[part 4 of 12: package /Cluster]
AUTOSAR XML (schema 4-3-0)
package /Cluster  (continued)
  can cluster HCP5_CANFD01: baudrate=500000, protocol-name=CAN, protocol-version=2.0, bus-off-recovery={bor-counter-l-1-to-l-2=1, bor-time-l-1=0.05, bor-time-l-2=0.2}, can-fd-baudrate=2000000  (continued)
    can physical channel CHNL: comm-connectors=CN_HCP5_CANFD01  (continued)
      frame BMC_HV_03_XIX_HCP5_CANFD01: id 0x1A555555, from BMC_HV, frame-length=24, can-addressing-mode=EXTENDED, can-frame-rx-behavior=CAN-FD, can-frame-tx-behavior=CAN-FD
        pdu BMC_HV_03_XIX_HCP5_CANFD01: length=24, transmission-mode-true-timing=cyclic-timing={time-offset=0, time-period=0.5}, unused-bit-pattern=0
          signal BMC_ThermSpreizung_XIX_BMC_HV_03_XIX_HCP5_CANFD01: start 12, 4 bit, little-endian, data-type-policy=OVERRIDE, i-signal-type=PRIMITIVE, init-value=14, base-type=BT_BMC_ThermSpreizung, invalid-value=Invalid_BMC_ThermSpreizung_XIX_BMC_HV_03_XIX_HCP5_CANFD01:15, compu {phys=raw*10 for raw 0..10, 14=Cxe_Init (CM_BMC_ThermSpreizung_Cxe_Init), 15=Cxf_Fehler (CM_BMC_ThermSpreizung_Cxf_Fehler); unit Unit_PerCent}, range phys 0..100 Unit_PerCent, raw 0..15, unit=Unit_PerCent, transfer-property=PENDING  # Beschreibt die thermische Spreizung der HV-Batterie. 0 % homogener Temperaturverlauf. 100% hoechst heterogener Temperaturverlauf
          signal BMC_VorlaufTemperatur_XIX_BMC_HV_03_XIX_HCP5_CANFD01: start 16, 10 bit, little-endian, data-type-policy=OVERRIDE, i-signal-type=PRIMITIVE, init-value=1022, base-type=BT_BMC_VorlaufTemperatur, invalid-value=Invalid_BMC_VorlaufTemperatur_XIX_BMC_HV_03_XIX_HCP5_CANFD01:1023, compu {phys=raw*0.125-40 for raw 0..1020, 1021=Cx3fd_Nicht_verbaut (CM_BMC_VorlaufTemperatur_Cx3fd_Nicht_verbaut), 1022=Cx3fe_Init (CM_BMC_VorlaufTemperatur_Cx3fe_Init), 1023=Cx3ff_Fehler (CM_BMC_VorlaufTemperatur_Cx3ff_Fehler); unit Unit_DegreCelsi}, range phys -40..87.5 Unit_DegreCelsi, raw 0..1023, unit=Unit_DegreCelsi, transfer-property=PENDING  # Aktuelle Vorlauftemperatur der Batterie
          signal BMC_RuecklaufTemperatur_XIX_BMC_HV_03_XIX_HCP5_CANFD01: start 26, 10 bit, little-endian, data-type-policy=OVERRIDE, i-signal-type=PRIMITIVE, init-value=1022, base-type=BT_BMC_RuecklaufTemperatur, invalid-value=Invalid_BMC_RuecklaufTemperatur_XIX_BMC_HV_03_XIX_HCP5_CANFD01:1023, compu {phys=raw*0.125-40 for raw 0..1020, 1021=Cx3fd_Nicht_verbaut (CM_BMC_RuecklaufTemperatur_Cx3fd_Nicht_verbaut), 1022=Cx3fe_Init (CM_BMC_RuecklaufTemperatur_Cx3fe_Init), 1023=Cx3ff_Fehler (CM_BMC_RuecklaufTemperatur_Cx3ff_Fehler); unit Unit_DegreCelsi}, range phys -40..87.5 Unit_DegreCelsi, raw 0..1023, unit=Unit_DegreCelsi, transfer-property=PENDING  # Aktuelle Ruecklauftemperatur der Batterie
          signal BMC_Temperatur_XIX_BMC_HV_03_XIX_HCP5_CANFD01: start 36, 10 bit, little-endian, data-type-policy=OVERRIDE, i-signal-type=PRIMITIVE, init-value=1022, base-type=BT_BMC_Temperatur, invalid-value=Invalid_BMC_Temperatur_XIX_BMC_HV_03_XIX_HCP5_CANFD01:1023, compu {phys=raw*0.125-40 for raw 0..1021, 1022=Cx3fe_Init (CM_BMC_Temperatur_Cx3fe_Init), 1023=Cx3ff_Fehler (CM_BMC_Temperatur_Cx3ff_Fehler); unit Unit_DegreCelsi}, range phys -40..87.625 Unit_DegreCelsi, raw 0..1023, unit=Unit_DegreCelsi, transfer-property=PENDING  # battery temperature / Momentanwert: Temperatur der Traktionsbatterie
          signal BMC_Abschaltankuendigung_XIX_BMC_HV_03_XIX_HCP5_CANFD01: start 46, 10 bit, little-endian, data-type-policy=OVERRIDE, i-signal-type=PRIMITIVE, init-value=1022, base-type=BT_BMC_Abschaltankuendigung, invalid-value=Invalid_BMC_Abschaltankuendigung_XIX_BMC_HV_03_XIX_HCP5_CANFD01:1023, compu {phys=raw*0.5 for raw 0..1021, 1022=Cx3fe_keine_Abschaltung (CM_BMC_Abschaltankuendigung_Cx3fe_keine_Abschaltung) (keine Abschaltung), 1023=Cx3ff_Fehler (CM_BMC_Abschaltankuendigung_Cx3ff_Fehler); unit Unit_Secon}, range phys 0..510.5 Unit_Secon, raw 0..1023, unit=Unit_Secon, transfer-property=PENDING  # Zeitliche Ankündigung einer Abschaltung der HV Batterie.
          signal BMC_NutzbareKapazitaet_XIX_BMC_HV_03_XIX_HCP5_CANFD01: start 56, 12 bit, little-endian, data-type-policy=OVERRIDE, i-signal-type=PRIMITIVE, init-value=4094, base-type=BT_BMC_NutzbareKapazitaet, invalid-value=Invalid_BMC_NutzbareKapazitaet_XIX_BMC_HV_03_XIX_HCP5_CANFD01:4095, compu {phys=raw*0.125 for raw 0..4093, 4094=Cxffe_Init (CM_BMC_NutzbareKapazitaet_Cxffe_Init), 4095=Cxfff_Fehler (CM_BMC_NutzbareKapazitaet_Cxfff_Fehler); unit Unit_AmperHour}, range phys 0..511.625 Unit_AmperHour, raw 0..4095, unit=Unit_AmperHour, transfer-property=PENDING  # Nutzbare Kapazität der Batterie, entspricht der Ladungsmenge von 100% NutzbarerSOC. Diese Größe ist abhängig vom Bank-Modus (seriell/parallel).
          signal BMC_Dauer_Entladeleistung_XIX_BMC_HV_03_XIX_HCP5_CANFD01: start 68, 12 bit, little-endian, data-type-policy=OVERRIDE, i-signal-type=PRIMITIVE, init-value=4094, base-type=BT_BMC_Dauer_Entladeleistung, invalid-value=Invalid_BMC_Dauer_Entladeleistung_XIX_BMC_HV_03_XIX_HCP5_CANFD01:4095, compu {phys=raw*200 for raw 0..4093, 4094=Cxffe_Init (CM_BMC_Dauer_Entladeleistung_Cxffe_Init), 4095=Cxfff_Fehler (CM_BMC_Dauer_Entladeleistung_Cxfff_Fehler); unit Unit_Watt}, range phys 0..818600 Unit_Watt, raw 0..4095, unit=Unit_Watt, transfer-property=PENDING  # ist die aktuelle Dauer-Leistungsfähigkeit der Batterie. Wenn dieser Wert überschritten wird, kann ein zeitliches Derating der maximalen Leistungsgrenzen stattfindet. Die Dauerleistung ändert sich mit Batterietemperatur und Ladezustand.
          signal BMC_Dauer_Ladeleistung_XIX_BMC_HV_03_XIX_HCP5_CANFD01: start 80, 12 bit, little-endian, data-type-policy=OVERRIDE, i-signal-type=PRIMITIVE, init-value=4094, base-type=BT_BMC_Dauer_Ladeleistung, invalid-value=Invalid_BMC_Dauer_Ladeleistung_XIX_BMC_HV_03_XIX_HCP5_CANFD01:4095, compu {phys=raw*200 for raw 0..4093, 4094=Cxffe_Init (CM_BMC_Dauer_Ladeleistung_Cxffe_Init), 4095=Cxfff_Fehler (CM_BMC_Dauer_Ladeleistung_Cxfff_Fehler); unit Unit_Watt}, range phys 0..818600 Unit_Watt, raw 0..4095, unit=Unit_Watt, transfer-property=PENDING  # ist die aktuelle Dauer-Leistungsfähigkeit der Batterie. Wenn dieser Wert überschritten wird, kann ein zeitliches Derating der maximalen Leistungsgrenzen stattfindet. Die Dauerleistung ändert sich mit Batterietemperatur und Ladezustand.
          signal BMC_VerlustEnergie_XIX_BMC_HV_03_XIX_HCP5_CANFD01: start 92, 13 bit, little-endian, data-type-policy=OVERRIDE, i-signal-type=PRIMITIVE, init-value=8190, base-type=BT_BMC_VerlustEnergie, invalid-value=Invalid_BMC_VerlustEnergie_XIX_BMC_HV_03_XIX_HCP5_CANFD01:8191, compu {phys=raw*4 for raw 0..8189, 8190=Cx1ffe_Init (CM_BMC_VerlustEnergie_Cx1ffe_Init), 8191=Cx1fff_Fehler (CM_BMC_VerlustEnergie_Cx1fff_Fehler); unit Unit_WattHour}, range phys 0..32756 Unit_WattHour, raw 0..8191, unit=Unit_WattHour, transfer-property=PENDING  # Verlustenergie für den Fall, dass I=Irwds eingeprägt wird im HV-ON bis zur vollständigen Entladung (KundenSOC=0%) . Im AC/DC-Laden bis zur vollständigen Ladung (KundenSOC=100%).
          signal BMC_ThermAuslastung_XIX_BMC_HV_03_XIX_HCP5_CANFD01: start 105, 7 bit, little-endian, data-type-policy=OVERRIDE, i-signal-type=PRIMITIVE, init-value=126, base-type=BT_BMC_ThermAuslastung, invalid-value=Invalid_BMC_ThermAuslastung_XIX_BMC_HV_03_XIX_HCP5_CANFD01:127, compu {phys=raw for raw 0..100, 101=Cx65_Notfallkuehlung (CM_BMC_ThermAuslastung_Cx65_Notfallkuehlung), 126=Cx7e_Init (CM_BMC_ThermAuslastung_Cx7e_Init), 127=Cx7f_Fehler (CM_BMC_ThermAuslastung_Cx7f_Fehler); unit Unit_PerCent}, range phys 0..100 Unit_PerCent, raw 0..127, unit=Unit_PerCent, transfer-property=PENDING  # 0- hohe Heizanforderung funktionale Einschränkung 26- mittlere Heizanforderung Temperatur anheben 36- kleine Heizanforderung passives Heizen 46- thermischer Wohlfühlbereich keine Kühl-/Heizleistung 56- kleine Kühlstufe Temperatur halten 66- mittlere Kühlstufe Temperatur absenken 76- große Kühlstufe funktionale Einschränkung 101- Notfallkühlung 126- Init 127- Fehler
          signal BMC_MaxEnergieinhalt_XIX_BMC_HV_03_XIX_HCP5_CANFD01: start 112, 16 bit, little-endian, data-type-policy=OVERRIDE, i-signal-type=PRIMITIVE, init-value=65534, base-type=BT_BMC_MaxEnergieinhalt, invalid-value=Invalid_BMC_MaxEnergieinhalt_XIX_BMC_HV_03_XIX_HCP5_CANFD01:65535, compu {phys=raw*4 for raw 0..65533, 65534=Cxfffe_Init (CM_BMC_MaxEnergieinhalt_Cxfffe_Init), 65535=Cxffff_Fehler (CM_BMC_MaxEnergieinhalt_Cxffff_Fehler); unit Unit_WattHour}, range phys 0..262132 Unit_WattHour, raw 0..65535, unit=Unit_WattHour, transfer-property=PENDING  # Maximaler Energieinhalt der Batterie bei 100% NutzbarerSOC unter Beruecksichtigung der Verluste (I_RWDS)
          signal BMC_Energie_Entladen_XIX_BMC_HV_03_XIX_HCP5_CANFD01: start 128, 16 bit, little-endian, data-type-policy=OVERRIDE, i-signal-type=PRIMITIVE, init-value=65534, base-type=BT_BMC_Energie_Entladen, invalid-value=Invalid_BMC_Energie_Entladen_XIX_BMC_HV_03_XIX_HCP5_CANFD01:65535, compu {phys=raw*0.01 for raw 0..65533, 65534=Cxfffe_Init (CM_BMC_Energie_Entladen_Cxfffe_Init), 65535=Cxffff_Fehler (CM_BMC_Energie_Entladen_Cxffff_Fehler); unit Unit_KiloWattHour}, range phys 0..655.33 Unit_KiloWattHour, raw 0..65535, unit=Unit_KiloWattHour, transfer-property=PENDING  # Energie, welche seit dem letzten Fahrzyklus während eines Ladevorgangs aus der HV-Batterie entnommen wurde
          signal BMC_Energie_Laden_XIX_BMC_HV_03_XIX_HCP5_CANFD01: start 144, 16 bit, little-endian, data-type-policy=OVERRIDE, i-signal-type=PRIMITIVE, init-value=65534, base-type=BT_BMC_Energie_Laden, invalid-value=Invalid_BMC_Energie_Laden_XIX_BMC_HV_03_XIX_HCP5_CANFD01:65535, compu {phys=raw*0.01 for raw 0..65533, 65534=Cxfffe_Init (CM_BMC_Energie_Laden_Cxfffe_Init), 65535=Cxffff_Fehler (CM_BMC_Energie_Laden_Cxffff_Fehler); unit Unit_KiloWattHour}, range phys 0..655.33 Unit_KiloWattHour, raw 0..65535, unit=Unit_KiloWattHour, transfer-property=PENDING  # Energie, welche seit dem letzten Fahrzyklus während eines Ladevorgansg in die HV-Batterie geladen wurde.
          signal BMC_Konditionierung_Anf_XIX_BMC_HV_03_XIX_HCP5_CANFD01: start 160, 1 bit, little-endian, data-type-policy=OVERRIDE, i-signal-type=PRIMITIVE, init-value=0, base-type=BT_BMC_Konditionierung_Anf, compu {0=Cx0_keine_Konditionierungsanforderung (CM_BMC_Konditionierung_Anf_Cx0_keine_Konditionierungsanforderung) (keine Konditionierungsanforderung), 1=Cx1_Konditionierungsanforderung (CM_BMC_Konditionierung_Anf_Cx1_Konditionierungsanforderung)}, range raw 0..1, transfer-property=PENDING  # Anforderung der HV Batterie um deren thermische Konditionierung durchzuführen nachdem das Fahrzeug geweckt wurde.
          signal BMC_Bidi_Min_SoC_XIX_BMC_HV_03_XIX_HCP5_CANFD01: start 161, 7 bit, little-endian, data-type-policy=OVERRIDE, i-signal-type=PRIMITIVE, init-value=126, base-type=BT_BMC_Bidi_Min_SoC, invalid-value=Invalid_BMC_Bidi_Min_SoC_XIX_BMC_HV_03_XIX_HCP5_CANFD01:127, compu {phys=raw for raw 0..100, 126=Cx7e_Init (CM_BMC_Bidi_Min_SoC_Cx7e_Init), 127=Cx7f_Fehler (CM_BMC_Bidi_Min_SoC_Cx7f_Fehler); unit Unit_PerCent}, range phys 0..100 Unit_PerCent, raw 0..127, unit=Unit_PerCent, transfer-property=PENDING  # Wertebereich: 0 - 100% Defaultwert: 20%
          signal BMC_Bidi_GenutzteEnergie_XIX_BMC_HV_03_XIX_HCP5_CANFD01: start 168, 16 bit, little-endian, data-type-policy=OVERRIDE, i-signal-type=PRIMITIVE, init-value=65534, base-type=BT_BMC_Bidi_GenutzteEnergie, invalid-value=Invalid_BMC_Bidi_GenutzteEnergie_XIX_BMC_HV_03_XIX_HCP5_CANFD01:65535, compu {phys=raw for raw 0..65533, 65534=Cxfffe_Init (CM_BMC_Bidi_GenutzteEnergie_Cxfffe_Init), 65535=Cxffff_Fehler (CM_BMC_Bidi_GenutzteEnergie_Cxffff_Fehler); unit Unit_KiloWattHour}, range phys 0..65533 Unit_KiloWattHour, raw 0..65535, unit=Unit_KiloWattHour, transfer-property=PENDING  # Beschreibt den bereits verwendeten Energiedurchsatz (Absolutwert, für Entladen) für die Funktion Bidi.
          signal BMC_Bidi_Veto_Temp_XIX_BMC_HV_03_XIX_HCP5_CANFD01: start 184, 1 bit, little-endian, data-type-policy=OVERRIDE, i-signal-type=PRIMITIVE, init-value=0, base-type=BT_BMC_Bidi_Veto_Temp, compu {0=Cx0_kein_Veto (CM_BMC_Bidi_Veto_Temp_Cx0_kein_Veto), 1=Cx1_Veto (CM_BMC_Bidi_Veto_Temp_Cx1_Veto)}, range raw 0..1, transfer-property=PENDING  # Freigabestatus der Funktion Bidi in Abhängigkeit der Ist-Temperatur
          signal BMC_Bidi_Max_SoC_XIX_BMC_HV_03_XIX_HCP5_CANFD01: start 185, 7 bit, little-endian, data-type-policy=OVERRIDE, i-signal-type=PRIMITIVE, init-value=126, base-type=BT_BMC_Bidi_Max_SoC, invalid-value=Invalid_BMC_Bidi_Max_SoC_XIX_BMC_HV_03_XIX_HCP5_CANFD01:127, compu {phys=raw for raw 0..100, 126=Cx7e_Init (CM_BMC_Bidi_Max_SoC_Cx7e_Init), 127=Cx7f_Fehler (CM_BMC_Bidi_Max_SoC_Cx7f_Fehler); unit Unit_PerCent}, range phys 0..100 Unit_PerCent, raw 0..127, unit=Unit_PerCent, transfer-property=PENDING  # Wertebereich: 0 - 100% Defaultwert: 80%
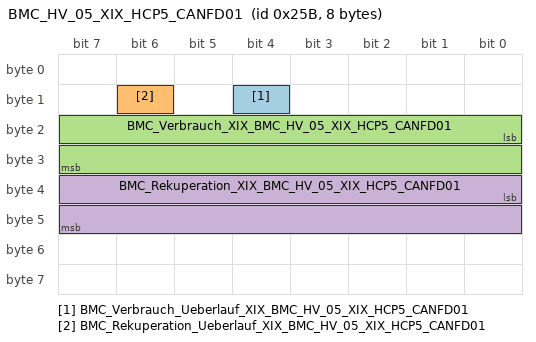
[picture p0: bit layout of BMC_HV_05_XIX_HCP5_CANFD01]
      frame BMC_HV_05_XIX_HCP5_CANFD01: id 0x25B, from BMC_HV, frame-length=8, can-addressing-mode=STANDARD, can-frame-rx-behavior=CAN-FD, can-frame-tx-behavior=CAN-FD
        pdu BMC_HV_05_XIX_HCP5_CANFD01: length=8, transmission-mode-true-timing=cyclic-timing={time-offset=0, time-period=0.05}, unused-bit-pattern=0
          signal BMC_Verbrauch_Ueberlauf_XIX_BMC_HV_05_XIX_HCP5_CANFD01: start 12, 1 bit, little-endian, data-type-policy=OVERRIDE, i-signal-type=PRIMITIVE, init-value=0, base-type=BT_BMC_Verbrauch_Ueberlauf, compu {0=Cx0_nicht_Ueberlauf (CM_BMC_Verbrauch_Ueberlauf_Cx0_nicht_Ueberlauf), 1=Cx1_Ueberlauf (CM_BMC_Verbrauch_Ueberlauf_Cx1_Ueberlauf)}, range raw 0..1, transfer-property=PENDING  # Signalisiert ob der Überlauf einen physikalischer Ursprung hat (0 = kein Überlauf oder Überlauf mit keinem physikalischem Ursprung)
          signal BMC_Rekuperation_Ueberlauf_XIX_BMC_HV_05_XIX_HCP5_CANFD01: start 14, 1 bit, little-endian, data-type-policy=OVERRIDE, i-signal-type=PRIMITIVE, init-value=0, base-type=BT_BMC_Rekuperation_Ueberlauf, compu {0=Cx0_kein_Ueberlauf (CM_BMC_Rekuperation_Ueberlauf_Cx0_kein_Ueberlauf), 1=Cx1_Ueberlauf (CM_BMC_Rekuperation_Ueberlauf_Cx1_Ueberlauf)}, range raw 0..1, transfer-property=PENDING  # Signalisiert ob der Überlauf einen physikalischer Ursprung hat (0 = kein Überlauf oder Überlauf mit keinem physikalischem Ursprung)
          signal BMC_Verbrauch_XIX_BMC_HV_05_XIX_HCP5_CANFD01: start 16, 16 bit, little-endian, data-type-policy=OVERRIDE, i-signal-type=PRIMITIVE, init-value=0, base-type=BT_BMC_Verbrauch, compu {phys=raw*10 for raw 0..65535; unit Unit_WattSecond}, range phys 0..655350 Unit_WattSecond, raw 0..65535, unit=Unit_WattSecond, transfer-property=PENDING  # Zähler: Energieentnahme aus der HV-Batterie
          signal BMC_Rekuperation_XIX_BMC_HV_05_XIX_HCP5_CANFD01: start 32, 16 bit, little-endian, data-type-policy=OVERRIDE, i-signal-type=PRIMITIVE, init-value=0, base-type=BT_BMC_Rekuperation, compu {phys=raw*10 for raw 0..65535; unit Unit_WattSecond}, range phys 0..655350 Unit_WattSecond, raw 0..65535, unit=Unit_WattSecond, transfer-property=PENDING  # Zähler: Anzeigesignal: Energiezufuhr in die HV-Batterie (Reku). Darf nicht durch Laden der Batterie bedatet werden
      frame BMC_HV_06_SOK_XIX_HCP5_CANFD01: id 0x16A95516, from BMC_HV, frame-length=12, can-addressing-mode=EXTENDED, can-frame-rx-behavior=CAN-FD, can-frame-tx-behavior=CAN-FD
        secured i pdu BMC_HV_06_SOK_XIX_HCP5_CANFD01:
          length=12
          authentication-props=SecureCommunicationAuthenticationProps_XIX_32
          freshness-props=SecureCommunicationFreshnessProps
          payload=PT_BMC_HV_06
          secure-communication-props={auth-data-freshness-length=0, auth-data-freshness-start-position=0, auth-info-tx-length=32, authentication-build-attempts=1, authentication-retries=4, data-id=535, freshness-value-id=2, freshness-value-length=64, freshness-value-tx-length=0}
          use-as-cryptographic-i-pdu=false
      frame BMC_HV_07_SOK_XIX_HCP5_CANFD01: id 0x16A95532, from BMC_HV, frame-length=12, can-addressing-mode=EXTENDED, can-frame-rx-behavior=CAN-FD, can-frame-tx-behavior=CAN-FD
        secured i pdu BMC_HV_07_SOK_XIX_HCP5_CANFD01:
          length=12
          authentication-props=SecureCommunicationAuthenticationProps_XIX_32
          freshness-props=SecureCommunicationFreshnessProps
          payload=PT_BMC_HV_07
          secure-communication-props={auth-data-freshness-length=0, auth-data-freshness-start-position=0, auth-info-tx-length=32, authentication-build-attempts=1, authentication-retries=4, data-id=730, freshness-value-id=3, freshness-value-length=64, freshness-value-tx-length=0}
          use-as-cryptographic-i-pdu=false
      frame BMC_HV_08_SOK_XIX_HCP5_CANFD01: id 0x1A555631, from BMC_HV, frame-length=48, can-addressing-mode=EXTENDED, can-frame-rx-behavior=CAN-FD, can-frame-tx-behavior=CAN-FD
        secured i pdu BMC_HV_08_SOK_XIX_HCP5_CANFD01:
          length=48
          authentication-props=SecureCommunicationAuthenticationProps_XIX_32
          freshness-props=SecureCommunicationFreshnessProps
          payload=PT_BMC_HV_08
          secure-communication-props={auth-data-freshness-length=0, auth-data-freshness-start-position=0, auth-info-tx-length=32, authentication-build-attempts=1, authentication-retries=4, data-id=731, freshness-value-id=4, freshness-value-length=64, freshness-value-tx-length=0}
          use-as-cryptographic-i-pdu=false
      frame BMC_HV_09_SOK_XIX_HCP5_CANFD01: id 0x12DD5593, from BMC_HV, frame-length=20, can-addressing-mode=EXTENDED, can-frame-rx-behavior=CAN-FD, can-frame-tx-behavior=CAN-FD
        secured i pdu BMC_HV_09_SOK_XIX_HCP5_CANFD01:
          length=20
          authentication-props=SecureCommunicationAuthenticationProps_XIX_32
          freshness-props=SecureCommunicationFreshnessProps
          payload=PT_BMC_HV_09
          secure-communication-props={auth-data-freshness-length=0, auth-data-freshness-start-position=0, auth-info-tx-length=32, authentication-build-attempts=1, authentication-retries=4, data-id=810, freshness-value-id=5, freshness-value-length=64, freshness-value-tx-length=0}
          use-as-cryptographic-i-pdu=false
      frame BMC_HV_14_SOK_XIX_HCP5_CANFD01: id 0x12DD55C4, from BMC_HV, frame-length=16, can-addressing-mode=STANDARD, can-frame-rx-behavior=CAN-FD, can-frame-tx-behavior=CAN-FD
        secured i pdu BMC_HV_14_SOK_XIX_HCP5_CANFD01:
          length=16
          authentication-props=SecureCommunicationAuthenticationProps_XIX_32
          freshness-props=SecureCommunicationFreshnessProps
          payload=PT_BMC_HV_14
          secure-communication-props={auth-data-freshness-length=0, auth-data-freshness-start-position=0, auth-info-tx-length=32, authentication-build-attempts=1, authentication-retries=4, data-id=846, freshness-value-id=6, freshness-value-length=64, freshness-value-tx-length=0}
          use-as-cryptographic-i-pdu=false
      frame Charisma_20_XIX_HCP5_CANFD01: id 0x1A55556D, to BMC_HV, frame-length=20, can-addressing-mode=EXTENDED, can-frame-rx-behavior=CAN-FD, can-frame-tx-behavior=CAN-FD
        pdu Charisma_20_XIX_HCP5_CANFD01: length=20, minimum-delay=0.05, transmission-mode-true-timing={cyclic-timing={time-offset=0, time-period=1}, event-controlled-timing={number-of-repetitions=0, repetition-period=0}}, unused-bit-pattern=0
          signal CHA_ReqPrgBms_XIX_Charisma_20_XIX_HCP5_CANFD01: start 12, 4 bit, little-endian, data-type-policy=OVERRIDE, i-signal-type=PRIMITIVE, init-value=0, base-type=BT_CHA_ReqPrgBms, compu {0=Cx0_no_program (CM_CHA_ReqPrgBms_Cx0_no_program), 1=Cx1_program_1 (CM_CHA_ReqPrgBms_Cx1_program_1), 2=Cx2_program_2 (CM_CHA_ReqPrgBms_Cx2_program_2), 3=Cx3_program_3 (CM_CHA_ReqPrgBms_Cx3_program_3), 4=Cx4_program_4 (CM_CHA_ReqPrgBms_Cx4_program_4), 5=Cx5_program_5 (CM_CHA_ReqPrgBms_Cx5_program_5), 6=Cx6_program_6 (CM_CHA_ReqPrgBms_Cx6_program_6), 7=Cx7_program_7 (CM_CHA_ReqPrgBms_Cx7_program_7), 8=Cx8_program_8 (CM_CHA_ReqPrgBms_Cx8_program_8), 9=Cx9_program_9 (CM_CHA_ReqPrgBms_Cx9_program_9), 10=Cxa_program_10 (CM_CHA_ReqPrgBms_Cxa_program_10), 11=Cxb_program_11 (CM_CHA_ReqPrgBms_Cxb_program_11), 12=Cxc_program_12 (CM_CHA_ReqPrgBms_Cxc_program_12), 13=Cxd_program_13 (CM_CHA_ReqPrgBms_Cxd_program_13), 14=Cxe_program_14 (CM_CHA_ReqPrgBms_Cxe_program_14), 15=Cxf_program_15 (CM_CHA_ReqPrgBms_Cxf_program_15)}, range raw 0..15, transfer-property=TRIGGERED-ON-CHANGE-WITHOUT-REPETITION, to BMC_HV(timeout 5 s)  # Anforderung des Fahrprogramms seitens Charisma an das Batterie-Management-System
          signal CHA_ReqPrgEps_XIX_Charisma_20_XIX_HCP5_CANFD01: start 20, 4 bit, little-endian, data-type-policy=OVERRIDE, i-signal-type=PRIMITIVE, init-value=0, base-type=BT_CHA_ReqPrgEps, compu {0=Cx0_no_program (CM_CHA_ReqPrgEps_Cx0_no_program), 1=Cx1_program_1 (CM_CHA_ReqPrgEps_Cx1_program_1), 2=Cx2_program_2 (CM_CHA_ReqPrgEps_Cx2_program_2), 3=Cx3_program_3 (CM_CHA_ReqPrgEps_Cx3_program_3), 4=Cx4_program_4 (CM_CHA_ReqPrgEps_Cx4_program_4), 5=Cx5_program_5 (CM_CHA_ReqPrgEps_Cx5_program_5), 6=Cx6_program_6 (CM_CHA_ReqPrgEps_Cx6_program_6), 7=Cx7_program_7 (CM_CHA_ReqPrgEps_Cx7_program_7), 8=Cx8_program_8 (CM_CHA_ReqPrgEps_Cx8_program_8), 9=Cx9_program_9 (CM_CHA_ReqPrgEps_Cx9_program_9), 10=Cxa_program_10 (CM_CHA_ReqPrgEps_Cxa_program_10), 11=Cxb_program_11 (CM_CHA_ReqPrgEps_Cxb_program_11), 12=Cxc_program_12 (CM_CHA_ReqPrgEps_Cxc_program_12), 13=Cxd_program_13 (CM_CHA_ReqPrgEps_Cxd_program_13), 14=Cxe_program_14 (CM_CHA_ReqPrgEps_Cxe_program_14), 15=Cxf_program_15 (CM_CHA_ReqPrgEps_Cxf_program_15)}, range raw 0..15, transfer-property=TRIGGERED-ON-CHANGE-WITHOUT-REPETITION  # Anforderung des Fahrprogramms seitens Charisma an die EPS-Lenkung.
          signal CHA_ReqPrgTqVect_XIX_Charisma_20_XIX_HCP5_CANFD01: start 28, 4 bit, little-endian, data-type-policy=OVERRIDE, i-signal-type=PRIMITIVE, init-value=0, base-type=BT_CHA_ReqPrgTqVect, compu {0=Cx0_no_program (CM_CHA_ReqPrgTqVect_Cx0_no_program), 1=Cx1_program_1 (CM_CHA_ReqPrgTqVect_Cx1_program_1), 2=Cx2_program_2 (CM_CHA_ReqPrgTqVect_Cx2_program_2), 3=Cx3_program_3 (CM_CHA_ReqPrgTqVect_Cx3_program_3), 4=Cx4_program_4 (CM_CHA_ReqPrgTqVect_Cx4_program_4), 5=Cx5_program_5 (CM_CHA_ReqPrgTqVect_Cx5_program_5), 6=Cx6_program_6 (CM_CHA_ReqPrgTqVect_Cx6_program_6), 7=Cx7_program_7 (CM_CHA_ReqPrgTqVect_Cx7_program_7), 8=Cx8_program_8 (CM_CHA_ReqPrgTqVect_Cx8_program_8), 9=Cx9_program_9 (CM_CHA_ReqPrgTqVect_Cx9_program_9), 10=Cxa_program_10 (CM_CHA_ReqPrgTqVect_Cxa_program_10), 11=Cxb_program_11 (CM_CHA_ReqPrgTqVect_Cxb_program_11), 12=Cxc_program_12 (CM_CHA_ReqPrgTqVect_Cxc_program_12), 13=Cxd_program_13 (CM_CHA_ReqPrgTqVect_Cxd_program_13), 14=Cxe_program_14 (CM_CHA_ReqPrgTqVect_Cxe_program_14), 15=Cxf_program_15 (CM_CHA_ReqPrgTqVect_Cxf_program_15)}, range raw 0..15, transfer-property=TRIGGERED-ON-CHANGE-WITHOUT-REPETITION  # Anforderung des Fahrprogramms seitens Charisma an die Torque-Vectoring-Systeme (z.B. QSP, eTV, BTV)
          signal CHA_ReqPrgKl_XIX_Charisma_20_XIX_HCP5_CANFD01: start 32, 4 bit, little-endian, data-type-policy=OVERRIDE, i-signal-type=PRIMITIVE, init-value=0, base-type=BT_CHA_ReqPrgKl, compu {0=Cx0_no_program (CM_CHA_ReqPrgKl_Cx0_no_program), 1=Cx1_program_1 (CM_CHA_ReqPrgKl_Cx1_program_1), 2=Cx2_program_2 (CM_CHA_ReqPrgKl_Cx2_program_2), 3=Cx3_program_3 (CM_CHA_ReqPrgKl_Cx3_program_3), 4=Cx4_program_4 (CM_CHA_ReqPrgKl_Cx4_program_4), 5=Cx5_program_5 (CM_CHA_ReqPrgKl_Cx5_program_5), 6=Cx6_program_6 (CM_CHA_ReqPrgKl_Cx6_program_6), 7=Cx7_program_7 (CM_CHA_ReqPrgKl_Cx7_program_7), 8=Cx8_program_8 (CM_CHA_ReqPrgKl_Cx8_program_8), 9=Cx9_program_9 (CM_CHA_ReqPrgKl_Cx9_program_9), 10=Cxa_program_10 (CM_CHA_ReqPrgKl_Cxa_program_10), 11=Cxb_program_11 (CM_CHA_ReqPrgKl_Cxb_program_11), 12=Cxc_program_12 (CM_CHA_ReqPrgKl_Cxc_program_12), 13=Cxd_program_13 (CM_CHA_ReqPrgKl_Cxd_program_13), 14=Cxe_program_14 (CM_CHA_ReqPrgKl_Cxe_program_14), 15=Cxf_program_15 (CM_CHA_ReqPrgKl_Cxf_program_15)}, range raw 0..15, transfer-property=TRIGGERED-ON-CHANGE-WITHOUT-REPETITION  # Anforderung des Fahrprogramms seitens Charisma an die Klima-Anlage
          signal CHA_ReqPrgDynTqCtrl_XIX_Charisma_20_XIX_HCP5_CANFD01: start 36, 4 bit, little-endian, data-type-policy=OVERRIDE, i-signal-type=PRIMITIVE, init-value=0, base-type=BT_CHA_ReqPrgDynTqCtrl, compu {0=Cx0_no_program (CM_CHA_ReqPrgDynTqCtrl_Cx0_no_program), 1=Cx1_program_1 (CM_CHA_ReqPrgDynTqCtrl_Cx1_program_1), 2=Cx2_program_2 (CM_CHA_ReqPrgDynTqCtrl_Cx2_program_2), 3=Cx3_program_3 (CM_CHA_ReqPrgDynTqCtrl_Cx3_program_3), 4=Cx4_program_4 (CM_CHA_ReqPrgDynTqCtrl_Cx4_program_4), 5=Cx5_program_5 (CM_CHA_ReqPrgDynTqCtrl_Cx5_program_5), 6=Cx6_program_6 (CM_CHA_ReqPrgDynTqCtrl_Cx6_program_6), 7=Cx7_program_7 (CM_CHA_ReqPrgDynTqCtrl_Cx7_program_7), 8=Cx8_program_8 (CM_CHA_ReqPrgDynTqCtrl_Cx8_program_8), 9=Cx9_program_9 (CM_CHA_ReqPrgDynTqCtrl_Cx9_program_9), 10=Cxa_program_10 (CM_CHA_ReqPrgDynTqCtrl_Cxa_program_10), 11=Cxb_program_11 (CM_CHA_ReqPrgDynTqCtrl_Cxb_program_11), 12=Cxc_program_12 (CM_CHA_ReqPrgDynTqCtrl_Cxc_program_12), 13=Cxd_program_13 (CM_CHA_ReqPrgDynTqCtrl_Cxd_program_13), 14=Cxe_program_14 (CM_CHA_ReqPrgDynTqCtrl_Cxe_program_14), 15=Cxf_program_15 (CM_CHA_ReqPrgDynTqCtrl_Cxf_program_15)}, range raw 0..15, transfer-property=TRIGGERED-ON-CHANGE-WITHOUT-REPETITION  # Anforderung des Fahrprogramms seitens Charisma an Allradregelsysteme (z.B. quattro ultra und eQuattro)
          signal CHA_ReqPrgAcc_XIX_Charisma_20_XIX_HCP5_CANFD01: start 40, 4 bit, little-endian, data-type-policy=OVERRIDE, i-signal-type=PRIMITIVE, init-value=0, base-type=BT_CHA_ReqPrgAcc, compu {0=Cx0_no_program (CM_CHA_ReqPrgAcc_Cx0_no_program), 1=Cx1_program_1 (CM_CHA_ReqPrgAcc_Cx1_program_1), 2=Cx2_program_2 (CM_CHA_ReqPrgAcc_Cx2_program_2), 3=Cx3_program_3 (CM_CHA_ReqPrgAcc_Cx3_program_3), 4=Cx4_program_4 (CM_CHA_ReqPrgAcc_Cx4_program_4), 5=Cx5_program_5 (CM_CHA_ReqPrgAcc_Cx5_program_5), 6=Cx6_program_6 (CM_CHA_ReqPrgAcc_Cx6_program_6), 7=Cx7_program_7 (CM_CHA_ReqPrgAcc_Cx7_program_7), 8=Cx8_program_8 (CM_CHA_ReqPrgAcc_Cx8_program_8), 9=Cx9_program_9 (CM_CHA_ReqPrgAcc_Cx9_program_9), 10=Cxa_program_10 (CM_CHA_ReqPrgAcc_Cxa_program_10), 11=Cxb_program_11 (CM_CHA_ReqPrgAcc_Cxb_program_11), 12=Cxc_program_12 (CM_CHA_ReqPrgAcc_Cxc_program_12), 13=Cxd_program_13 (CM_CHA_ReqPrgAcc_Cxd_program_13), 14=Cxe_program_14 (CM_CHA_ReqPrgAcc_Cxe_program_14), 15=Cxf_program_15 (CM_CHA_ReqPrgAcc_Cxf_program_15)}, range raw 0..15, transfer-property=TRIGGERED-ON-CHANGE-WITHOUT-REPETITION  # Anforderung des Fahrprogramms seitens Charisma an die Funktion ACC.
          signal CHA_ReqPrgRwb_XIX_Charisma_20_XIX_HCP5_CANFD01: start 44, 4 bit, little-endian, data-type-policy=OVERRIDE, i-signal-type=PRIMITIVE, init-value=0, base-type=BT_CHA_ReqPrgRwb, compu {0=Cx0_no_program (CM_CHA_ReqPrgRwb_Cx0_no_program), 1=Cx1_program_1 (CM_CHA_ReqPrgRwb_Cx1_program_1), 2=Cx2_program_2 (CM_CHA_ReqPrgRwb_Cx2_program_2), 3=Cx3_program_3 (CM_CHA_ReqPrgRwb_Cx3_program_3), 4=Cx4_program_4 (CM_CHA_ReqPrgRwb_Cx4_program_4), 5=Cx5_program_5 (CM_CHA_ReqPrgRwb_Cx5_program_5), 6=Cx6_program_6 (CM_CHA_ReqPrgRwb_Cx6_program_6), 7=Cx7_program_7 (CM_CHA_ReqPrgRwb_Cx7_program_7), 8=Cx8_program_8 (CM_CHA_ReqPrgRwb_Cx8_program_8), 9=Cx9_program_9 (CM_CHA_ReqPrgRwb_Cx9_program_9), 10=Cxa_program_10 (CM_CHA_ReqPrgRwb_Cxa_program_10), 11=Cxb_program_11 (CM_CHA_ReqPrgRwb_Cxb_program_11), 12=Cxc_program_12 (CM_CHA_ReqPrgRwb_Cxc_program_12), 13=Cxd_program_13 (CM_CHA_ReqPrgRwb_Cxd_program_13), 14=Cxe_program_14 (CM_CHA_ReqPrgRwb_Cxe_program_14), 15=Cxf_program_15 (CM_CHA_ReqPrgRwb_Cxf_program_15)}, range raw 0..15, transfer-property=TRIGGERED-ON-CHANGE-WITHOUT-REPETITION  # Anforderung des Fahrprogramms seitens Charisma an die Funktion Reichweitenberechnung.
          signal CHA_ReqPrgHsp_XIX_Charisma_20_XIX_HCP5_CANFD01: start 48, 4 bit, little-endian, data-type-policy=OVERRIDE, i-signal-type=PRIMITIVE, init-value=0, base-type=BT_CHA_ReqPrgHsp, compu {0=Cx0_no_program (CM_CHA_ReqPrgHsp_Cx0_no_program), 1=Cx1_program_1 (CM_CHA_ReqPrgHsp_Cx1_program_1), 2=Cx2_program_2 (CM_CHA_ReqPrgHsp_Cx2_program_2), 3=Cx3_program_3 (CM_CHA_ReqPrgHsp_Cx3_program_3), 4=Cx4_program_4 (CM_CHA_ReqPrgHsp_Cx4_program_4), 5=Cx5_program_5 (CM_CHA_ReqPrgHsp_Cx5_program_5), 6=Cx6_program_6 (CM_CHA_ReqPrgHsp_Cx6_program_6), 7=Cx7_program_7 (CM_CHA_ReqPrgHsp_Cx7_program_7), 8=Cx8_program_8 (CM_CHA_ReqPrgHsp_Cx8_program_8), 9=Cx9_program_9 (CM_CHA_ReqPrgHsp_Cx9_program_9), 10=Cxa_program_10 (CM_CHA_ReqPrgHsp_Cxa_program_10), 11=Cxb_program_11 (CM_CHA_ReqPrgHsp_Cxb_program_11), 12=Cxc_program_12 (CM_CHA_ReqPrgHsp_Cxc_program_12), 13=Cxd_program_13 (CM_CHA_ReqPrgHsp_Cxd_program_13), 14=Cxe_program_14 (CM_CHA_ReqPrgHsp_Cxe_program_14), 15=Cxf_program_15 (CM_CHA_ReqPrgHsp_Cxf_program_15)}, range raw 0..15, transfer-property=TRIGGERED-ON-CHANGE-WITHOUT-REPETITION  # Anforderung des Fahrprogramms seitens Charisma an die Heckspoiler-Steuerung. Nur in Porsche-Fahrzeugen gütlig.
          signal CHA_ReqPrgWarnBrk_XIX_Charisma_20_XIX_HCP5_CANFD01: start 52, 4 bit, little-endian, data-type-policy=OVERRIDE, i-signal-type=PRIMITIVE, init-value=0, base-type=BT_CHA_ReqPrgWarnBrk, compu {0=Cx0_no_program (CM_CHA_ReqPrgWarnBrk_Cx0_no_program), 1=Cx1_program_1 (CM_CHA_ReqPrgWarnBrk_Cx1_program_1), 2=Cx2_program_2 (CM_CHA_ReqPrgWarnBrk_Cx2_program_2), 3=Cx3_program_3 (CM_CHA_ReqPrgWarnBrk_Cx3_program_3), 4=Cx4_program_4 (CM_CHA_ReqPrgWarnBrk_Cx4_program_4), 5=Cx5_program_5 (CM_CHA_ReqPrgWarnBrk_Cx5_program_5), 6=Cx6_program_6 (CM_CHA_ReqPrgWarnBrk_Cx6_program_6), 7=Cx7_program_7 (CM_CHA_ReqPrgWarnBrk_Cx7_program_7), 8=Cx8_program_8 (CM_CHA_ReqPrgWarnBrk_Cx8_program_8), 9=Cx9_program_9 (CM_CHA_ReqPrgWarnBrk_Cx9_program_9), 10=Cxa_program_10 (CM_CHA_ReqPrgWarnBrk_Cxa_program_10), 11=Cxb_program_11 (CM_CHA_ReqPrgWarnBrk_Cxb_program_11), 12=Cxc_program_12 (CM_CHA_ReqPrgWarnBrk_Cxc_program_12), 13=Cxd_program_13 (CM_CHA_ReqPrgWarnBrk_Cxd_program_13), 14=Cxe_program_14 (CM_CHA_ReqPrgWarnBrk_Cxe_program_14), 15=Cxf_program_15 (CM_CHA_ReqPrgWarnBrk_Cxf_program_15)}, range raw 0..15, transfer-property=TRIGGERED-ON-CHANGE-WITHOUT-REPETITION  # Anforderung des Fahrprogramms seitens Charisma an die Funktion Warn-Brems
          signal CHA_ReqPrgExtrLight_XIX_Charisma_20_XIX_HCP5_CANFD01: start 56, 4 bit, little-endian, data-type-policy=OVERRIDE, i-signal-type=PRIMITIVE, init-value=0, base-type=BT_CHA_ReqPrgExtrLight, compu {0=Cx0_no_program (CM_CHA_ReqPrgExtrLight_Cx0_no_program), 1=Cx1_program_1 (CM_CHA_ReqPrgExtrLight_Cx1_program_1), 2=Cx2_program_2 (CM_CHA_ReqPrgExtrLight_Cx2_program_2), 3=Cx3_program_3 (CM_CHA_ReqPrgExtrLight_Cx3_program_3), 4=Cx4_program_4 (CM_CHA_ReqPrgExtrLight_Cx4_program_4), 5=Cx5_program_5 (CM_CHA_ReqPrgExtrLight_Cx5_program_5), 6=Cx6_program_6 (CM_CHA_ReqPrgExtrLight_Cx6_program_6), 7=Cx7_program_7 (CM_CHA_ReqPrgExtrLight_Cx7_program_7), 8=Cx8_program_8 (CM_CHA_ReqPrgExtrLight_Cx8_program_8), 9=Cx9_program_9 (CM_CHA_ReqPrgExtrLight_Cx9_program_9), 10=Cxa_program_10 (CM_CHA_ReqPrgExtrLight_Cxa_program_10), 11=Cxb_program_11 (CM_CHA_ReqPrgExtrLight_Cxb_program_11), 12=Cxc_program_12 (CM_CHA_ReqPrgExtrLight_Cxc_program_12), 13=Cxd_program_13 (CM_CHA_ReqPrgExtrLight_Cxd_program_13), 14=Cxe_program_14 (CM_CHA_ReqPrgExtrLight_Cxe_program_14), 15=Cxf_program_15 (CM_CHA_ReqPrgExtrLight_Cxf_program_15)}, range raw 0..15, transfer-property=TRIGGERED-ON-CHANGE-WITHOUT-REPETITION  # Anforderung des Fahrprogramms seitens Charisma an die Scheinwerfer-Funktionen.
          signal CHA_ReqPrgEsc_XIX_Charisma_20_XIX_HCP5_CANFD01: start 60, 4 bit, little-endian, data-type-policy=OVERRIDE, i-signal-type=PRIMITIVE, init-value=0, base-type=BT_CHA_ReqPrgEsc, compu {0=Cx0_no_program (CM_CHA_ReqPrgEsc_Cx0_no_program), 1=Cx1_program_1 (CM_CHA_ReqPrgEsc_Cx1_program_1), 2=Cx2_program_2 (CM_CHA_ReqPrgEsc_Cx2_program_2), 3=Cx3_program_3 (CM_CHA_ReqPrgEsc_Cx3_program_3), 4=Cx4_program_4 (CM_CHA_ReqPrgEsc_Cx4_program_4), 5=Cx5_program_5 (CM_CHA_ReqPrgEsc_Cx5_program_5), 6=Cx6_program_6 (CM_CHA_ReqPrgEsc_Cx6_program_6), 7=Cx7_program_7 (CM_CHA_ReqPrgEsc_Cx7_program_7), 8=Cx8_program_8 (CM_CHA_ReqPrgEsc_Cx8_program_8), 9=Cx9_program_9 (CM_CHA_ReqPrgEsc_Cx9_program_9), 10=Cxa_program_10 (CM_CHA_ReqPrgEsc_Cxa_program_10), 11=Cxb_program_11 (CM_CHA_ReqPrgEsc_Cxb_program_11), 12=Cxc_program_12 (CM_CHA_ReqPrgEsc_Cxc_program_12), 13=Cxd_program_13 (CM_CHA_ReqPrgEsc_Cxd_program_13), 14=Cxe_program_14 (CM_CHA_ReqPrgEsc_Cxe_program_14), 15=Cxf_program_15 (CM_CHA_ReqPrgEsc_Cxf_program_15)}, range raw 0..15, transfer-property=TRIGGERED-ON-CHANGE-WITHOUT-REPETITION  # Anforderung des Fahrprogramms seitens Charisma an das ESC
          signal CHA_ReqPrgHdc_XIX_Charisma_20_XIX_HCP5_CANFD01: start 64, 4 bit, little-endian, data-type-policy=OVERRIDE, i-signal-type=PRIMITIVE, init-value=0, base-type=BT_CHA_ReqPrgHdc, compu {0=Cx0_no_program (CM_CHA_ReqPrgHdc_Cx0_no_program), 1=Cx1_program_1 (CM_CHA_ReqPrgHdc_Cx1_program_1), 2=Cx2_program_2 (CM_CHA_ReqPrgHdc_Cx2_program_2), 3=Cx3_program_3 (CM_CHA_ReqPrgHdc_Cx3_program_3), 4=Cx4_program_4 (CM_CHA_ReqPrgHdc_Cx4_program_4), 5=Cx5_program_5 (CM_CHA_ReqPrgHdc_Cx5_program_5), 6=Cx6_program_6 (CM_CHA_ReqPrgHdc_Cx6_program_6), 7=Cx7_program_7 (CM_CHA_ReqPrgHdc_Cx7_program_7), 8=Cx8_program_8 (CM_CHA_ReqPrgHdc_Cx8_program_8), 9=Cx9_program_9 (CM_CHA_ReqPrgHdc_Cx9_program_9), 10=Cxa_program_10 (CM_CHA_ReqPrgHdc_Cxa_program_10), 11=Cxb_program_11 (CM_CHA_ReqPrgHdc_Cxb_program_11), 12=Cxc_program_12 (CM_CHA_ReqPrgHdc_Cxc_program_12), 13=Cxd_program_13 (CM_CHA_ReqPrgHdc_Cxd_program_13), 14=Cxe_program_14 (CM_CHA_ReqPrgHdc_Cxe_program_14), 15=Cxf_program_15 (CM_CHA_ReqPrgHdc_Cxf_program_15)}, range raw 0..15, transfer-property=TRIGGERED-ON-CHANGE-WITHOUT-REPETITION  # Anforderung des Fahrprogramms seitens Charisma an die Bergabfahrhilfe.
          signal CHA_ReqPrgLC_XIX_Charisma_20_XIX_HCP5_CANFD01: start 68, 4 bit, little-endian, data-type-policy=OVERRIDE, i-signal-type=PRIMITIVE, init-value=0, base-type=BT_CHA_ReqPrgLC, compu {0=Cx0_no_program (CM_CHA_ReqPrgLC_Cx0_no_program), 1=Cx1_program_1 (CM_CHA_ReqPrgLC_Cx1_program_1), 2=Cx2_program_2 (CM_CHA_ReqPrgLC_Cx2_program_2), 3=Cx3_program_3 (CM_CHA_ReqPrgLC_Cx3_program_3), 4=Cx4_program_4 (CM_CHA_ReqPrgLC_Cx4_program_4), 5=Cx5_program_5 (CM_CHA_ReqPrgLC_Cx5_program_5), 6=Cx6_program_6 (CM_CHA_ReqPrgLC_Cx6_program_6), 7=Cx7_program_7 (CM_CHA_ReqPrgLC_Cx7_program_7), 8=Cx8_program_8 (CM_CHA_ReqPrgLC_Cx8_program_8), 9=Cx9_program_9 (CM_CHA_ReqPrgLC_Cx9_program_9), 10=Cxa_program_10 (CM_CHA_ReqPrgLC_Cxa_program_10), 11=Cxb_program_11 (CM_CHA_ReqPrgLC_Cxb_program_11), 12=Cxc_program_12 (CM_CHA_ReqPrgLC_Cxc_program_12), 13=Cxd_program_13 (CM_CHA_ReqPrgLC_Cxd_program_13), 14=Cxe_program_14 (CM_CHA_ReqPrgLC_Cxe_program_14), 15=Cxf_program_15 (CM_CHA_ReqPrgLC_Cxf_program_15)}, range raw 0..15, transfer-property=TRIGGERED-ON-CHANGE-WITHOUT-REPETITION  # Anforderung des Fahrprogramms seitens Charisma an die Funktion Niveauregulierung.
          signal CHA_ReqPrgAcvChassis_XIX_Charisma_20_XIX_HCP5_CANFD01: start 72, 4 bit, little-endian, data-type-policy=OVERRIDE, i-signal-type=PRIMITIVE, init-value=0, base-type=BT_CHA_ReqPrgAcvChassis, compu {0=Cx0_no_program (CM_CHA_ReqPrgAcvChassis_Cx0_no_program), 1=Cx1_program_1 (CM_CHA_ReqPrgAcvChassis_Cx1_program_1), 2=Cx2_program_2 (CM_CHA_ReqPrgAcvChassis_Cx2_program_2), 3=Cx3_program_3 (CM_CHA_ReqPrgAcvChassis_Cx3_program_3), 4=Cx4_program_4 (CM_CHA_ReqPrgAcvChassis_Cx4_program_4), 5=Cx5_program_5 (CM_CHA_ReqPrgAcvChassis_Cx5_program_5), 6=Cx6_program_6 (CM_CHA_ReqPrgAcvChassis_Cx6_program_6), 7=Cx7_program_7 (CM_CHA_ReqPrgAcvChassis_Cx7_program_7), 8=Cx8_program_8 (CM_CHA_ReqPrgAcvChassis_Cx8_program_8), 9=Cx9_program_9 (CM_CHA_ReqPrgAcvChassis_Cx9_program_9), 10=Cxa_program_10 (CM_CHA_ReqPrgAcvChassis_Cxa_program_10), 11=Cxb_program_11 (CM_CHA_ReqPrgAcvChassis_Cxb_program_11), 12=Cxc_program_12 (CM_CHA_ReqPrgAcvChassis_Cxc_program_12), 13=Cxd_program_13 (CM_CHA_ReqPrgAcvChassis_Cxd_program_13), 14=Cxe_program_14 (CM_CHA_ReqPrgAcvChassis_Cxe_program_14), 15=Cxf_program_15 (CM_CHA_ReqPrgAcvChassis_Cxf_program_15)}, range raw 0..15, transfer-property=TRIGGERED-ON-CHANGE-WITHOUT-REPETITION  # Anforderung des Fahrprogramms seitens Charisma an das aktive Fahrwerk
          signal CHA_ReqPrgDC_XIX_Charisma_20_XIX_HCP5_CANFD01: start 76, 4 bit, little-endian, data-type-policy=OVERRIDE, i-signal-type=PRIMITIVE, init-value=0, base-type=BT_CHA_ReqPrgDC, compu {0=Cx0_no_program (CM_CHA_ReqPrgDC_Cx0_no_program), 1=Cx1_program_1 (CM_CHA_ReqPrgDC_Cx1_program_1), 2=Cx2_program_2 (CM_CHA_ReqPrgDC_Cx2_program_2), 3=Cx3_program_3 (CM_CHA_ReqPrgDC_Cx3_program_3), 4=Cx4_program_4 (CM_CHA_ReqPrgDC_Cx4_program_4), 5=Cx5_program_5 (CM_CHA_ReqPrgDC_Cx5_program_5), 6=Cx6_program_6 (CM_CHA_ReqPrgDC_Cx6_program_6), 7=Cx7_program_7 (CM_CHA_ReqPrgDC_Cx7_program_7), 8=Cx8_program_8 (CM_CHA_ReqPrgDC_Cx8_program_8), 9=Cx9_program_9 (CM_CHA_ReqPrgDC_Cx9_program_9), 10=Cxa_program_10 (CM_CHA_ReqPrgDC_Cxa_program_10), 11=Cxb_program_11 (CM_CHA_ReqPrgDC_Cxb_program_11), 12=Cxc_program_12 (CM_CHA_ReqPrgDC_Cxc_program_12), 13=Cxd_program_13 (CM_CHA_ReqPrgDC_Cxd_program_13), 14=Cxe_program_14 (CM_CHA_ReqPrgDC_Cxe_program_14), 15=Cxf_program_15 (CM_CHA_ReqPrgDC_Cxf_program_15)}, range raw 0..15, transfer-property=TRIGGERED-ON-CHANGE-WITHOUT-REPETITION  # Anforderung des Fahrprogramms seitens Charisma an die Dämpferregelung
          signal CHA_ReqPrgDt_XIX_Charisma_20_XIX_HCP5_CANFD01: start 84, 4 bit, little-endian, data-type-policy=OVERRIDE, i-signal-type=PRIMITIVE, init-value=0, base-type=BT_CHA_ReqPrgDt, compu {0=Cx0_no_program (CM_CHA_ReqPrgDt_Cx0_no_program), 1=Cx1_program_1 (CM_CHA_ReqPrgDt_Cx1_program_1), 2=Cx2_program_2 (CM_CHA_ReqPrgDt_Cx2_program_2), 3=Cx3_program_3 (CM_CHA_ReqPrgDt_Cx3_program_3), 4=Cx4_program_4 (CM_CHA_ReqPrgDt_Cx4_program_4), 5=Cx5_program_5 (CM_CHA_ReqPrgDt_Cx5_program_5), 6=Cx6_program_6 (CM_CHA_ReqPrgDt_Cx6_program_6), 7=Cx7_program_7 (CM_CHA_ReqPrgDt_Cx7_program_7), 8=Cx8_program_8 (CM_CHA_ReqPrgDt_Cx8_program_8), 9=Cx9_program_9 (CM_CHA_ReqPrgDt_Cx9_program_9), 10=Cxa_program_10 (CM_CHA_ReqPrgDt_Cxa_program_10), 11=Cxb_program_11 (CM_CHA_ReqPrgDt_Cxb_program_11), 12=Cxc_program_12 (CM_CHA_ReqPrgDt_Cxc_program_12), 13=Cxd_program_13 (CM_CHA_ReqPrgDt_Cxd_program_13), 14=Cxe_program_14 (CM_CHA_ReqPrgDt_Cxe_program_14), 15=Cxf_program_15 (CM_CHA_ReqPrgDt_Cxf_program_15)}, range raw 0..15, transfer-property=TRIGGERED-ON-CHANGE-WITHOUT-REPETITION  # Anforderung des Fahrprogramms seitens Charisma an die Antriebsfunktionen Motor und Getriebe.
          signal CHA_ReqPrgRcp_XIX_Charisma_20_XIX_HCP5_CANFD01: start 88, 4 bit, little-endian, data-type-policy=OVERRIDE, i-signal-type=PRIMITIVE, init-value=0, base-type=BT_CHA_ReqPrgRcp, compu {0=Cx0_no_program (CM_CHA_ReqPrgRcp_Cx0_no_program), 1=Cx1_program_1 (CM_CHA_ReqPrgRcp_Cx1_program_1), 2=Cx2_program_2 (CM_CHA_ReqPrgRcp_Cx2_program_2), 3=Cx3_program_3 (CM_CHA_ReqPrgRcp_Cx3_program_3), 4=Cx4_program_4 (CM_CHA_ReqPrgRcp_Cx4_program_4), 5=Cx5_program_5 (CM_CHA_ReqPrgRcp_Cx5_program_5), 6=Cx6_program_6 (CM_CHA_ReqPrgRcp_Cx6_program_6), 7=Cx7_program_7 (CM_CHA_ReqPrgRcp_Cx7_program_7), 8=Cx8_program_8 (CM_CHA_ReqPrgRcp_Cx8_program_8), 9=Cx9_program_9 (CM_CHA_ReqPrgRcp_Cx9_program_9), 10=Cxa_program_10 (CM_CHA_ReqPrgRcp_Cxa_program_10), 11=Cxb_program_11 (CM_CHA_ReqPrgRcp_Cxb_program_11), 12=Cxc_program_12 (CM_CHA_ReqPrgRcp_Cxc_program_12), 13=Cxd_program_13 (CM_CHA_ReqPrgRcp_Cxd_program_13), 14=Cxe_program_14 (CM_CHA_ReqPrgRcp_Cxe_program_14), 15=Cxf_program_15 (CM_CHA_ReqPrgRcp_Cxf_program_15)}, range raw 0..15, transfer-property=TRIGGERED-ON-CHANGE-WITHOUT-REPETITION  # Anforderung des Fahrprogramms seitens Charisma an Funktion Rekuperation. Nur in Porsche-Fahrzeugen gütlig.
          signal CHA_ReqPrgIntrLight_XIX_Charisma_20_XIX_HCP5_CANFD01: start 92, 4 bit, little-endian, data-type-policy=OVERRIDE, i-signal-type=PRIMITIVE, init-value=0, base-type=BT_CHA_ReqPrgIntrLight, compu {0=Cx0_no_program (CM_CHA_ReqPrgIntrLight_Cx0_no_program), 1=Cx1_program_1 (CM_CHA_ReqPrgIntrLight_Cx1_program_1), 2=Cx2_program_2 (CM_CHA_ReqPrgIntrLight_Cx2_program_2), 3=Cx3_program_3 (CM_CHA_ReqPrgIntrLight_Cx3_program_3), 4=Cx4_program_4 (CM_CHA_ReqPrgIntrLight_Cx4_program_4), 5=Cx5_program_5 (CM_CHA_ReqPrgIntrLight_Cx5_program_5), 6=Cx6_program_6 (CM_CHA_ReqPrgIntrLight_Cx6_program_6), 7=Cx7_program_7 (CM_CHA_ReqPrgIntrLight_Cx7_program_7), 8=Cx8_program_8 (CM_CHA_ReqPrgIntrLight_Cx8_program_8), 9=Cx9_program_9 (CM_CHA_ReqPrgIntrLight_Cx9_program_9), 10=Cxa_program_10 (CM_CHA_ReqPrgIntrLight_Cxa_program_10), 11=Cxb_program_11 (CM_CHA_ReqPrgIntrLight_Cxb_program_11), 12=Cxc_program_12 (CM_CHA_ReqPrgIntrLight_Cxc_program_12), 13=Cxd_program_13 (CM_CHA_ReqPrgIntrLight_Cxd_program_13), 14=Cxe_program_14 (CM_CHA_ReqPrgIntrLight_Cxe_program_14), 15=Cxf_program_15 (CM_CHA_ReqPrgIntrLight_Cxf_program_15)}, range raw 0..15, transfer-property=TRIGGERED-ON-CHANGE-WITHOUT-REPETITION  # Anforderung des Fahrprogramms seitens Charisma an die Innenbeleuchtung
          signal CHA_ReqPrgPreCrash_XIX_Charisma_20_XIX_HCP5_CANFD01: start 96, 4 bit, little-endian, data-type-policy=OVERRIDE, i-signal-type=PRIMITIVE, init-value=0, base-type=BT_CHA_ReqPrgPreCrash, compu {0=Cx0_no_program (CM_CHA_ReqPrgPreCrash_Cx0_no_program), 1=Cx1_program_1 (CM_CHA_ReqPrgPreCrash_Cx1_program_1), 2=Cx2_program_2 (CM_CHA_ReqPrgPreCrash_Cx2_program_2), 3=Cx3_program_3 (CM_CHA_ReqPrgPreCrash_Cx3_program_3), 4=Cx4_program_4 (CM_CHA_ReqPrgPreCrash_Cx4_program_4), 5=Cx5_program_5 (CM_CHA_ReqPrgPreCrash_Cx5_program_5), 6=Cx6_program_6 (CM_CHA_ReqPrgPreCrash_Cx6_program_6), 7=Cx7_program_7 (CM_CHA_ReqPrgPreCrash_Cx7_program_7), 8=Cx8_program_8 (CM_CHA_ReqPrgPreCrash_Cx8_program_8), 9=Cx9_program_9 (CM_CHA_ReqPrgPreCrash_Cx9_program_9), 10=Cxa_program_10 (CM_CHA_ReqPrgPreCrash_Cxa_program_10), 11=Cxb_program_11 (CM_CHA_ReqPrgPreCrash_Cxb_program_11), 12=Cxc_program_12 (CM_CHA_ReqPrgPreCrash_Cxc_program_12), 13=Cxd_program_13 (CM_CHA_ReqPrgPreCrash_Cxd_program_13), 14=Cxe_program_14 (CM_CHA_ReqPrgPreCrash_Cxe_program_14), 15=Cxf_program_15 (CM_CHA_ReqPrgPreCrash_Cxf_program_15)}, range raw 0..15, transfer-property=TRIGGERED-ON-CHANGE-WITHOUT-REPETITION  # Anforderung des Fahrprogramms seitens Charisma an die PreCrash-Funktion.
          signal CHA_ReqPrgCMM_XIX_Charisma_20_XIX_HCP5_CANFD01: start 100, 4 bit, little-endian, data-type-policy=OVERRIDE, i-signal-type=PRIMITIVE, init-value=0, base-type=BT_CHA_ReqPrgCMM, compu {0=Cx0_no_program (CM_CHA_ReqPrgCMM_Cx0_no_program), 1=Cx1_program_1 (CM_CHA_ReqPrgCMM_Cx1_program_1), 2=Cx2_program_2 (CM_CHA_ReqPrgCMM_Cx2_program_2), 3=Cx3_program_3 (CM_CHA_ReqPrgCMM_Cx3_program_3), 4=Cx4_program_4 (CM_CHA_ReqPrgCMM_Cx4_program_4), 5=Cx5_program_5 (CM_CHA_ReqPrgCMM_Cx5_program_5), 6=Cx6_program_6 (CM_CHA_ReqPrgCMM_Cx6_program_6), 7=Cx7_program_7 (CM_CHA_ReqPrgCMM_Cx7_program_7), 8=Cx8_program_8 (CM_CHA_ReqPrgCMM_Cx8_program_8), 9=Cx9_program_9 (CM_CHA_ReqPrgCMM_Cx9_program_9), 10=Cxa_program_10 (CM_CHA_ReqPrgCMM_Cxa_program_10), 11=Cxb_program_11 (CM_CHA_ReqPrgCMM_Cxb_program_11), 12=Cxc_program_12 (CM_CHA_ReqPrgCMM_Cxc_program_12), 13=Cxd_program_13 (CM_CHA_ReqPrgCMM_Cxd_program_13), 14=Cxe_program_14 (CM_CHA_ReqPrgCMM_Cxe_program_14), 15=Cxf_program_15 (CM_CHA_ReqPrgCMM_Cxf_program_15)}, range raw 0..15, transfer-property=TRIGGERED-ON-CHANGE-WITHOUT-REPETITION  # Requested Charisma-programm directly to ChassisModeManager.
          signal CHA_ReqPrgExtrSound_XIX_Charisma_20_XIX_HCP5_CANFD01: start 104, 4 bit, little-endian, data-type-policy=OVERRIDE, i-signal-type=PRIMITIVE, init-value=0, base-type=BT_CHA_ReqPrgExtrSound, compu {0=Cx0_no_program (CM_CHA_ReqPrgExtrSound_Cx0_no_program), 1=Cx1_program_1 (CM_CHA_ReqPrgExtrSound_Cx1_program_1), 2=Cx2_program_2 (CM_CHA_ReqPrgExtrSound_Cx2_program_2), 3=Cx3_program_3 (CM_CHA_ReqPrgExtrSound_Cx3_program_3), 4=Cx4_program_4 (CM_CHA_ReqPrgExtrSound_Cx4_program_4), 5=Cx5_program_5 (CM_CHA_ReqPrgExtrSound_Cx5_program_5), 6=Cx6_program_6 (CM_CHA_ReqPrgExtrSound_Cx6_program_6), 7=Cx7_program_7 (CM_CHA_ReqPrgExtrSound_Cx7_program_7), 8=Cx8_program_8 (CM_CHA_ReqPrgExtrSound_Cx8_program_8), 9=Cx9_program_9 (CM_CHA_ReqPrgExtrSound_Cx9_program_9), 10=Cxa_program_10 (CM_CHA_ReqPrgExtrSound_Cxa_program_10), 11=Cxb_program_11 (CM_CHA_ReqPrgExtrSound_Cxb_program_11), 12=Cxc_program_12 (CM_CHA_ReqPrgExtrSound_Cxc_program_12), 13=Cxd_program_13 (CM_CHA_ReqPrgExtrSound_Cxd_program_13), 14=Cxe_program_14 (CM_CHA_ReqPrgExtrSound_Cxe_program_14), 15=Cxf_program_15 (CM_CHA_ReqPrgExtrSound_Cxf_program_15)}, range raw 0..15, transfer-property=TRIGGERED-ON-CHANGE-WITHOUT-REPETITION  # Requested Charisma-programm to exterior-sound-systems.
          signal CHA_ReqPrgIntrSound_XIX_Charisma_20_XIX_HCP5_CANFD01: start 108, 4 bit, little-endian, data-type-policy=OVERRIDE, i-signal-type=PRIMITIVE, init-value=0, base-type=BT_CHA_ReqPrgIntrSound, compu {0=Cx0_no_program (CM_CHA_ReqPrgIntrSound_Cx0_no_program), 1=Cx1_program_1 (CM_CHA_ReqPrgIntrSound_Cx1_program_1), 2=Cx2_program_2 (CM_CHA_ReqPrgIntrSound_Cx2_program_2), 3=Cx3_program_3 (CM_CHA_ReqPrgIntrSound_Cx3_program_3), 4=Cx4_program_4 (CM_CHA_ReqPrgIntrSound_Cx4_program_4), 5=Cx5_program_5 (CM_CHA_ReqPrgIntrSound_Cx5_program_5), 6=Cx6_program_6 (CM_CHA_ReqPrgIntrSound_Cx6_program_6), 7=Cx7_program_7 (CM_CHA_ReqPrgIntrSound_Cx7_program_7), 8=Cx8_program_8 (CM_CHA_ReqPrgIntrSound_Cx8_program_8), 9=Cx9_program_9 (CM_CHA_ReqPrgIntrSound_Cx9_program_9), 10=Cxa_program_10 (CM_CHA_ReqPrgIntrSound_Cxa_program_10), 11=Cxb_program_11 (CM_CHA_ReqPrgIntrSound_Cxb_program_11), 12=Cxc_program_12 (CM_CHA_ReqPrgIntrSound_Cxc_program_12), 13=Cxd_program_13 (CM_CHA_ReqPrgIntrSound_Cxd_program_13), 14=Cxe_program_14 (CM_CHA_ReqPrgIntrSound_Cxe_program_14), 15=Cxf_program_15 (CM_CHA_ReqPrgIntrSound_Cxf_program_15)}, range raw 0..15, transfer-property=TRIGGERED-ON-CHANGE-WITHOUT-REPETITION  # Requested Charisma-programm to interior-sound-systems.
          signal CHA_CurProf_XIX_Charisma_20_XIX_HCP5_CANFD01: start 112, 5 bit, little-endian, data-type-policy=OVERRIDE, i-signal-type=PRIMITIVE, init-value=0, base-type=BT_CHA_CurProf, compu {0=Cx0_no_profile (CM_CHA_CurProf_Cx0_no_profile), 1=Cx1_profile_1 (CM_CHA_CurProf_Cx1_profile_1), 2=Cx2_profile_2 (CM_CHA_CurProf_Cx2_profile_2), 3=Cx3_profile_3 (CM_CHA_CurProf_Cx3_profile_3), 4=Cx4_profile_4 (CM_CHA_CurProf_Cx4_profile_4), 5=Cx5_profile_5 (CM_CHA_CurProf_Cx5_profile_5), 6=Cx6_profile_6 (CM_CHA_CurProf_Cx6_profile_6), 7=Cx7_profile_7 (CM_CHA_CurProf_Cx7_profile_7), 8=Cx8_profile_8 (CM_CHA_CurProf_Cx8_profile_8), 9=Cx9_profile_9 (CM_CHA_CurProf_Cx9_profile_9), 10=Cxa_profile_10 (CM_CHA_CurProf_Cxa_profile_10), 11=Cxb_profile_11 (CM_CHA_CurProf_Cxb_profile_11), 12=Cxc_profile_12 (CM_CHA_CurProf_Cxc_profile_12), 13=Cxd_profile_13 (CM_CHA_CurProf_Cxd_profile_13), 14=Cxe_profile_14 (CM_CHA_CurProf_Cxe_profile_14), 15=Cxf_profile_15 (CM_CHA_CurProf_Cxf_profile_15), 16=Cx10_profile_16 (CM_CHA_CurProf_Cx10_profile_16), 17=Cx11_profile_17 (CM_CHA_CurProf_Cx11_profile_17), 18=Cx12_profile_18 (CM_CHA_CurProf_Cx12_profile_18), 19=Cx13_profile_19 (CM_CHA_CurProf_Cx13_profile_19), 20=Cx14_profile_20 (CM_CHA_CurProf_Cx14_profile_20), 21=Cx15_profile_21 (CM_CHA_CurProf_Cx15_profile_21), 22=Cx16_profile_22 (CM_CHA_CurProf_Cx16_profile_22), 23=Cx17_profile_23 (CM_CHA_CurProf_Cx17_profile_23), 24=Cx18_profile_24 (CM_CHA_CurProf_Cx18_profile_24), 25=Cx19_profile_25 (CM_CHA_CurProf_Cx19_profile_25), 26=Cx1a_profile_26 (CM_CHA_CurProf_Cx1a_profile_26), 27=Cx1b_profile_27 (CM_CHA_CurProf_Cx1b_profile_27), 28=Cx1c_profile_28 (CM_CHA_CurProf_Cx1c_profile_28), 29=Cx1d_profile_29 (CM_CHA_CurProf_Cx1d_profile_29), 30=Cx1e_profile_30 (CM_CHA_CurProf_Cx1e_profile_30), 31=Cx1f_profile_31 (CM_CHA_CurProf_Cx1f_profile_31)}, range raw 0..31, transfer-property=TRIGGERED-ON-CHANGE-WITHOUT-REPETITION  # Ausgabe des aktuell selektierten Charisma Fahrprofils
          signal CHA_ProfChanged_XIX_Charisma_20_XIX_HCP5_CANFD01: start 117, 1 bit, little-endian, data-type-policy=OVERRIDE, i-signal-type=PRIMITIVE, init-value=0, base-type=BT_CHA_ProfChanged, compu {0=Cx0_profile_not_changed (CM_CHA_ProfChanged_Cx0_profile_not_changed), 1=Cx1_profile_changed (CM_CHA_ProfChanged_Cx1_profile_changed)}, range raw 0..1, transfer-property=TRIGGERED-ON-CHANGE-WITHOUT-REPETITION  # Triggersignal für die Änderung bzw. Neuauswahl des aktivierten Charisma Fahrprofils
          signal CHA_StCurProfDft_XIX_Charisma_20_XIX_HCP5_CANFD01: start 118, 2 bit, little-endian, data-type-policy=OVERRIDE, i-signal-type=PRIMITIVE, init-value=0, base-type=BT_CHA_StCurProfDft, compu {0=Cx0_Init (CM_CHA_StCurProfDft_Cx0_Init), 1=Cx1_profile_is_not_configurable (CM_CHA_StCurProfDft_Cx1_profile_is_not_configurable), 2=Cx2_profile_is_default (CM_CHA_StCurProfDft_Cx2_profile_is_default), 3=Cx3_profile_is_not_default (CM_CHA_StCurProfDft_Cx3_profile_is_not_default)}, range raw 0..3, transfer-property=TRIGGERED-ON-CHANGE-WITHOUT-REPETITION  # Signal indicates if the current Charisma-profile
          signal CHA_ReqPrgDispSetup_XIX_Charisma_20_XIX_HCP5_CANFD01: start 120, 4 bit, little-endian, data-type-policy=OVERRIDE, i-signal-type=PRIMITIVE, init-value=0, base-type=BT_CHA_ReqPrgDispSetup, compu {0=Cx0_init (CM_CHA_ReqPrgDispSetup_Cx0_init), 1=Cx1_layout_comfort (CM_CHA_ReqPrgDispSetup_Cx1_layout_comfort), 2=Cx2_layout_eco (CM_CHA_ReqPrgDispSetup_Cx2_layout_eco), 3=Cx3_layout_sport (CM_CHA_ReqPrgDispSetup_Cx3_layout_sport), 4=Cx4_layout_offroad (CM_CHA_ReqPrgDispSetup_Cx4_layout_offroad), 5=Cx5_layout_sportplus (CM_CHA_ReqPrgDispSetup_Cx5_layout_sportplus), 6=Cx6_program_6 (CM_CHA_ReqPrgDispSetup_Cx6_program_6), 7=Cx7_program_7 (CM_CHA_ReqPrgDispSetup_Cx7_program_7), 8=Cx8_program_8 (CM_CHA_ReqPrgDispSetup_Cx8_program_8), 9=Cx9_program_9 (CM_CHA_ReqPrgDispSetup_Cx9_program_9), 10=Cxa_program_10 (CM_CHA_ReqPrgDispSetup_Cxa_program_10), 11=Cxb_program_11 (CM_CHA_ReqPrgDispSetup_Cxb_program_11), 12=Cxc_program_12 (CM_CHA_ReqPrgDispSetup_Cxc_program_12), 13=Cxd_program_13 (CM_CHA_ReqPrgDispSetup_Cxd_program_13), 14=Cxe_program_14 (CM_CHA_ReqPrgDispSetup_Cxe_program_14), 15=Cxf_program_15 (CM_CHA_ReqPrgDispSetup_Cxf_program_15)}, range raw 0..15, transfer-property=TRIGGERED-ON-CHANGE-WITHOUT-REPETITION  # Requested Charisma-programm to Kombi to change display setup.
          signal CHA_ReqPrgVLim_XIX_Charisma_20_XIX_HCP5_CANFD01: start 124, 4 bit, little-endian, data-type-policy=OVERRIDE, i-signal-type=PRIMITIVE, init-value=0, base-type=BT_CHA_ReqPrgVLim, compu {0=Cx0_no_program (CM_CHA_ReqPrgVLim_Cx0_no_program), 1=Cx1_program_1 (CM_CHA_ReqPrgVLim_Cx1_program_1), 2=Cx2_program_2 (CM_CHA_ReqPrgVLim_Cx2_program_2), 3=Cx3_program_3 (CM_CHA_ReqPrgVLim_Cx3_program_3), 4=Cx4_program_4 (CM_CHA_ReqPrgVLim_Cx4_program_4), 5=Cx5_program_5 (CM_CHA_ReqPrgVLim_Cx5_program_5), 6=Cx6_program_6 (CM_CHA_ReqPrgVLim_Cx6_program_6), 7=Cx7_program_7 (CM_CHA_ReqPrgVLim_Cx7_program_7), 8=Cx8_program_8 (CM_CHA_ReqPrgVLim_Cx8_program_8), 9=Cx9_program_9 (CM_CHA_ReqPrgVLim_Cx9_program_9), 10=Cxa_program_10 (CM_CHA_ReqPrgVLim_Cxa_program_10), 11=Cxb_program_11 (CM_CHA_ReqPrgVLim_Cxb_program_11), 12=Cxc_program_12 (CM_CHA_ReqPrgVLim_Cxc_program_12), 13=Cxd_program_13 (CM_CHA_ReqPrgVLim_Cxd_program_13), 14=Cxe_program_14 (CM_CHA_ReqPrgVLim_Cxe_program_14), 15=Cxf_program_15 (CM_CHA_ReqPrgVLim_Cxf_program_15)}, range raw 0..15, transfer-property=TRIGGERED-ON-CHANGE-WITHOUT-REPETITION  # Requested Charisma-programm directly to the speedlimiter.
          signal CHA_FlgGlbFallBkIdc_XIX_Charisma_20_XIX_HCP5_CANFD01: start 128, 1 bit, little-endian, data-type-policy=OVERRIDE, i-signal-type=PRIMITIVE, init-value=0, base-type=BT_CHA_FlgGlbFallBkIdc, compu {0=Cx0_global_fall_back_not_indicated (CM_CHA_FlgGlbFallBkIdc_Cx0_global_fall_back_not_indicated), 1=Cx1_global_fall_back_indicated (CM_CHA_FlgGlbFallBkIdc_Cx1_global_fall_back_indicated)}, range raw 0..1, transfer-property=TRIGGERED-ON-CHANGE-WITHOUT-REPETITION  # Rueckmeldung der Funktion Charisma, ob ein Teilnehmer einen globalen Rueckfall gemeldet bzw. angefordert hat. Das Signal gibt keine Aussage darueber , ob in Folge der Teilnehmer-Meldung auch ein Profil-Wechsel oder eine -Sperrung durchgefuehrt wurde.
          signal CHA_ReqPrgAcvStg_XIX_Charisma_20_XIX_HCP5_CANFD01: start 129, 4 bit, little-endian, data-type-policy=OVERRIDE, i-signal-type=PRIMITIVE, init-value=0, base-type=BT_CHA_ReqPrgAcvStg, compu {0=Cx0_no_program (CM_CHA_ReqPrgAcvStg_Cx0_no_program), 1=Cx1_program_1 (CM_CHA_ReqPrgAcvStg_Cx1_program_1), 2=Cx2_program_2 (CM_CHA_ReqPrgAcvStg_Cx2_program_2), 3=Cx3_program_3 (CM_CHA_ReqPrgAcvStg_Cx3_program_3), 4=Cx4_program_4 (CM_CHA_ReqPrgAcvStg_Cx4_program_4), 5=Cx5_program_5 (CM_CHA_ReqPrgAcvStg_Cx5_program_5), 6=Cx6_program_6 (CM_CHA_ReqPrgAcvStg_Cx6_program_6), 7=Cx7_program_7 (CM_CHA_ReqPrgAcvStg_Cx7_program_7), 8=Cx8_program_8 (CM_CHA_ReqPrgAcvStg_Cx8_program_8), 9=Cx9_program_9 (CM_CHA_ReqPrgAcvStg_Cx9_program_9), 10=Cxa_program_10 (CM_CHA_ReqPrgAcvStg_Cxa_program_10), 11=Cxb_program_11 (CM_CHA_ReqPrgAcvStg_Cxb_program_11), 12=Cxc_program_12 (CM_CHA_ReqPrgAcvStg_Cxc_program_12), 13=Cxd_program_13 (CM_CHA_ReqPrgAcvStg_Cxd_program_13), 14=Cxe_program_14 (CM_CHA_ReqPrgAcvStg_Cxe_program_14), 15=Cxf_program_15 (CM_CHA_ReqPrgAcvStg_Cxf_program_15)}, range raw 0..15, transfer-property=TRIGGERED-ON-CHANGE-WITHOUT-REPETITION  # Anforderung des Fahrprogramms seitens Charisma an die Funktion vernetzte Lenkung
          signal CHA_FlgEndOfList_XIX_Charisma_20_XIX_HCP5_CANFD01: start 133, 2 bit, little-endian, data-type-policy=OVERRIDE, i-signal-type=PRIMITIVE, init-value=0, base-type=BT_CHA_FlgEndOfList, compu {0=Cx0_no_trigger (CM_CHA_FlgEndOfList_Cx0_no_trigger), 1=Cx1_left_end_reached_trigger (CM_CHA_FlgEndOfList_Cx1_left_end_reached_trigger), 2=Cx2_right_end_reached_trigger (CM_CHA_FlgEndOfList_Cx2_right_end_reached_trigger)}, range raw 0..2, transfer-property=TRIGGERED-ON-CHANGE-WITHOUT-REPETITION  # Charisma provides the information to the HMI, if the driver selects the first or the last profile in the profile-list. The signal is sent with the correspondig list-end for a certain-time when the driver activates or reactivates a profile at the end of the list.
          signal CHA_ReqPrgHdUpDisp_XIX_Charisma_20_XIX_HCP5_CANFD01: start 135, 4 bit, little-endian, data-type-policy=OVERRIDE, i-signal-type=PRIMITIVE, init-value=0, base-type=BT_CHA_ReqPrgHdUpDisp, compu {0=Cx0_no_program (CM_CHA_ReqPrgHdUpDisp_Cx0_no_program), 1=Cx1_program_1 (CM_CHA_ReqPrgHdUpDisp_Cx1_program_1), 2=Cx2_program_2 (CM_CHA_ReqPrgHdUpDisp_Cx2_program_2), 3=Cx3_program_3 (CM_CHA_ReqPrgHdUpDisp_Cx3_program_3), 4=Cx4_program_4 (CM_CHA_ReqPrgHdUpDisp_Cx4_program_4), 5=Cx5_program_5 (CM_CHA_ReqPrgHdUpDisp_Cx5_program_5), 6=Cx6_program_6 (CM_CHA_ReqPrgHdUpDisp_Cx6_program_6), 7=Cx7_program_7 (CM_CHA_ReqPrgHdUpDisp_Cx7_program_7), 8=Cx8_program_8 (CM_CHA_ReqPrgHdUpDisp_Cx8_program_8), 9=Cx9_program_9 (CM_CHA_ReqPrgHdUpDisp_Cx9_program_9), 10=Cxa_program_10 (CM_CHA_ReqPrgHdUpDisp_Cxa_program_10), 11=Cxb_program_11 (CM_CHA_ReqPrgHdUpDisp_Cxb_program_11), 12=Cxc_program_12 (CM_CHA_ReqPrgHdUpDisp_Cxc_program_12), 13=Cxd_program_13 (CM_CHA_ReqPrgHdUpDisp_Cxd_program_13), 14=Cxe_program_14 (CM_CHA_ReqPrgHdUpDisp_Cxe_program_14), 15=Cxf_program_15 (CM_CHA_ReqPrgHdUpDisp_Cxf_program_15)}, range raw 0..15, transfer-property=TRIGGERED-ON-CHANGE-WITHOUT-REPETITION  # Requested Charisma-programm to headup-display to change it's layout.
      frame ClampControl_01_XIX_HCP5_CANFD01: id 0x12DD54FE, to BMC_HV, frame-length=8, can-addressing-mode=EXTENDED, can-frame-rx-behavior=CAN-FD, can-frame-tx-behavior=CAN-FD
        pdu ClampControl_01_XIX_HCP5_CANFD01: length=8, minimum-delay=0.01, transmission-mode-true-timing={cyclic-timing={time-offset=0, time-period=0.1}, event-controlled-timing={number-of-repetitions=0, repetition-period=0}}, unused-bit-pattern=0
          signal ClampControl_01_CRC_XIX_ClampControl_01_XIX_HCP5_CANFD01: start 0, 8 bit, little-endian, data-type-policy=OVERRIDE, i-signal-type=PRIMITIVE, init-value=0, base-type=BT_ClampControl_01_CRC, compu {phys=raw for raw 0..255}, range phys 0..255, raw 0..255, transfer-property=PENDING  # Für MLB: Berechnung siehe Lastenheft "Kommunikationsabsicherung für FlexRay und CAN" Ab MQB und MLBevo: Berechnung siehe Lastenheft "End-to-End Kommunikationsabsicherung" Endwerte siehe Begleitdokument "S-PDU Kennungsfolgen"
          signal ClampControl_01_BZ_XIX_ClampControl_01_XIX_HCP5_CANFD01: start 8, 4 bit, little-endian, data-type-policy=OVERRIDE, i-signal-type=PRIMITIVE, init-value=0, base-type=BT_ClampControl_01_BZ, compu {phys=raw for raw 0..15}, range phys 0..15, raw 0..15, transfer-property=PENDING  # 4bit Botschaftszähler, wird mit jeder Sendebotschaft inkrementiert
          signal KST_Warn_P1_ZAT_def_XIX_ClampControl_01_XIX_HCP5_CANFD01: start 12, 1 bit, little-endian, data-type-policy=OVERRIDE, i-signal-type=PRIMITIVE, init-value=0, base-type=BT_KST_Warn_P1_ZAT_def, compu {0=Cx0_nicht_defekt (CM_KST_Warn_P1_ZAT_def_Cx0_nicht_defekt), 1=Cx1_defekt (CM_KST_Warn_P1_ZAT_def_Cx1_defekt)}, range raw 0..1, transfer-property=TRIGGERED-ON-CHANGE-WITHOUT-REPETITION  # Kombi Prio Warnung Klemmensteuerung Zündschloß defekt, Service aufsuchen!
          signal KST_Warn_P2_ZAT_def_XIX_ClampControl_01_XIX_HCP5_CANFD01: start 13, 1 bit, little-endian, data-type-policy=OVERRIDE, i-signal-type=PRIMITIVE, init-value=0, base-type=BT_KST_Warn_P2_ZAT_def, compu {0=Cx0_nicht_defekt (CM_KST_Warn_P2_ZAT_def_Cx0_nicht_defekt), 1=Cx1_defekt (CM_KST_Warn_P2_ZAT_def_Cx1_defekt)}, range raw 0..1, transfer-property=TRIGGERED-ON-CHANGE-WITHOUT-REPETITION  # Kombi Prio Warnung Klemmensteuerung Zündschloß defekt!
          signal KST_Deaktivierungs_Trigger_XIX_ClampControl_01_XIX_HCP5_CANFD01: start 14, 2 bit, little-endian, data-type-policy=OVERRIDE, i-signal-type=PRIMITIVE, init-value=0, base-type=BT_KST_Deaktivierungs_Trigger, compu {0=Cx0_KEINE_DEAKTIVIERUNG_ERFOLGT_0 (CM_KST_Deaktivierungs_Trigger_Cx0_KEINE_DEAKTIVIERUNG_ERFOLGT_0), 1=Cx1_DEAKTIVIERUNG_UEBER_ZAT_1 (CM_KST_Deaktivierungs_Trigger_Cx1_DEAKTIVIERUNG_UEBER_ZAT_1), 2=Cx2_DEAKTIVIERUNG_VEREINFACHT_VLK_2 (CM_KST_Deaktivierungs_Trigger_Cx2_DEAKTIVIERUNG_VEREINFACHT_VLK_2)}, range raw 0..2, transfer-property=TRIGGERED-ON-CHANGE-WITHOUT-REPETITION  # Ausgabe des Deaktivierungstriggers für Funktionen mit Goodbye-Szenario zur Unterscheidung zwischen manueller und automatischer Deaktivierung bei Fzg.-Verlassen
          signal KST_Kl_S_XIX_ClampControl_01_XIX_HCP5_CANFD01: start 16, 1 bit, little-endian, data-type-policy=OVERRIDE, i-signal-type=PRIMITIVE, init-value=0, base-type=BT_KST_Kl_S, compu {0=Cx0_aus (CM_KST_Kl_S_Cx0_aus), 1=Cx1_S_Kontakt_ein (CM_KST_Kl_S_Cx1_S_Kontakt_ein)}, range raw 0..1, transfer-property=TRIGGERED-ON-CHANGE-WITHOUT-REPETITION  # Klemme S: S-Kontakt (Schluessel steckt)
          signal KST_KL_15_XIX_ClampControl_01_XIX_HCP5_CANFD01: start 17, 1 bit, little-endian, data-type-policy=OVERRIDE, i-signal-type=PRIMITIVE, init-value=0, base-type=BT_KST_KL_15, compu {0=Cx0_aus (CM_KST_KL_15_Cx0_aus), 1=Cx1_ein (CM_KST_KL_15_Cx1_ein)}, range raw 0..1, transfer-property=TRIGGERED-ON-CHANGE-WITHOUT-REPETITION, to BMC_HV(timeout 1 s)  # Klemme 15: Zuendung (SW-Kl.15)
          signal KST_Kl_50_Startanforderung_XIX_ClampControl_01_XIX_HCP5_CANFD01: start 18, 1 bit, little-endian, data-type-policy=OVERRIDE, i-signal-type=PRIMITIVE, init-value=0, base-type=BT_KST_Kl_50_Startanforderung, compu {0=Cx0_aus (CM_KST_Kl_50_Startanforderung_Cx0_aus), 1=Cx1_KL50_ein_Startwunsch_Fahrer (CM_KST_Kl_50_Startanforderung_Cx1_KL50_ein_Startwunsch_Fahrer)}, range raw 0..1, transfer-property=TRIGGERED-ON-CHANGE-WITHOUT-REPETITION  # Klemme 50: Startwunsch Fahrer
          signal KST_Sonderzustand_Status_XIX_ClampControl_01_XIX_HCP5_CANFD01: start 19, 2 bit, little-endian, data-type-policy=OVERRIDE, i-signal-type=PRIMITIVE, init-value=0, base-type=BT_KST_Sonderzustand_Status, invalid-value=Invalid_KST_Sonderzustand_Status_XIX_ClampControl_01_XIX_HCP5_CANFD01:3, compu {0=Cx0_Init (CM_KST_Sonderzustand_Status_Cx0_Init), 1=Cx1_Uebergang_neue_Anforderung (CM_KST_Sonderzustand_Status_Cx1_Uebergang_neue_Anforderung), 2=Cx2_Aktiv (CM_KST_Sonderzustand_Status_Cx2_Aktiv), 3=Cx3_Fehler (CM_KST_Sonderzustand_Status_Cx3_Fehler)}, range raw 0..3, transfer-property=TRIGGERED-ON-CHANGE-WITHOUT-REPETITION  # Hiermit wird signalisiert, dass eine Sonderfunktion aktiv ist und die Klemme 15 durch diese angefordert wurde bzw. ein Übergang von Sonderfunktionen stattfindet
          signal KST_Ausstiegswunsch_Status_XIX_ClampControl_01_XIX_HCP5_CANFD01: start 21, 1 bit, little-endian, data-type-policy=OVERRIDE, i-signal-type=PRIMITIVE, init-value=0, base-type=BT_KST_Ausstiegswunsch_Status, compu {0=Cx0_KEIN_AUSSTIEGSWUNSCH_AKTIV_0 (CM_KST_Ausstiegswunsch_Status_Cx0_KEIN_AUSSTIEGSWUNSCH_AKTIV_0), 1=Cx1_AUSSTIEGSWUNSCH_AKTIV_1 (CM_KST_Ausstiegswunsch_Status_Cx1_AUSSTIEGSWUNSCH_AKTIV_1)}, range raw 0..1, transfer-property=TRIGGERED-ON-CHANGE-WITHOUT-REPETITION  # Ausstiegswunsch über den Funktionen mit Goodbye-Szenario zentral getriggert werden können.
          signal KST_BulbCheckReq_XIX_ClampControl_01_XIX_HCP5_CANFD01: start 23, 1 bit, little-endian, data-type-policy=OVERRIDE, i-signal-type=PRIMITIVE, init-value=0, base-type=BT_KST_BulbCheckReq, compu {0=Cx0_Keine_Anfrage (CM_KST_BulbCheckReq_Cx0_Keine_Anfrage), 1=Cx1_Anfrage (CM_KST_BulbCheckReq_Cx1_Anfrage)}, range raw 0..1, transfer-property=TRIGGERED-ON-CHANGE-WITHOUT-REPETITION  # Signal fordert eine Lampenaufprüfung (Bulb Check) an.
          signal KST_Kl_X_XIX_ClampControl_01_XIX_HCP5_CANFD01: start 24, 1 bit, little-endian, data-type-policy=OVERRIDE, i-signal-type=PRIMITIVE, init-value=0, base-type=BT_KST_Kl_X, compu {0=Cx0_aus (CM_KST_Kl_X_Cx0_aus), 1=Cx1_ein (CM_KST_Kl_X_Cx1_ein)}, range raw 0..1, transfer-property=TRIGGERED-ON-CHANGE-WITHOUT-REPETITION  # Ausgabe der Klemme 75 aus Kompatibilitätsgründen für COP-Übernahmen aus MEB.
          signal KST_Ausparken_Betrieb_XIX_ClampControl_01_XIX_HCP5_CANFD01: start 25, 1 bit, little-endian, data-type-policy=OVERRIDE, i-signal-type=PRIMITIVE, init-value=0, base-type=BT_KST_Ausparken_Betrieb, compu {0=Cx0_kein_Betrieb (CM_KST_Ausparken_Betrieb_Cx0_kein_Betrieb), 1=Cx1_Ausparkvorgang_aktiv (CM_KST_Ausparken_Betrieb_Cx1_Ausparkvorgang_aktiv)}, range raw 0..1, transfer-property=TRIGGERED-ON-CHANGE-WITHOUT-REPETITION  # Anforderung zur erneuten Lampenaufprüfung und Anzeige von Warnhinweisen nach einem pilotierten Ausparkvorgang (Trigger: fallende Flanke)
          signal KST_Fahrerhinweis_1_XIX_ClampControl_01_XIX_HCP5_CANFD01: start 26, 1 bit, little-endian, data-type-policy=OVERRIDE, i-signal-type=PRIMITIVE, init-value=0, base-type=BT_KST_Fahrerhinweis_1, compu {0=Cx0_inaktiv (CM_KST_Fahrerhinweis_1_Cx0_inaktiv), 1=Cx1_aktiv (CM_KST_Fahrerhinweis_1_Cx1_aktiv)}, range raw 0..1, transfer-property=TRIGGERED-ON-CHANGE-WITHOUT-REPETITION  # Signalisierung Fahrerhinweis 1 der Klemmensteuerung an das Kombi
          signal KST_Fahrerhinweis_2_XIX_ClampControl_01_XIX_HCP5_CANFD01: start 27, 1 bit, little-endian, data-type-policy=OVERRIDE, i-signal-type=PRIMITIVE, init-value=0, base-type=BT_KST_Fahrerhinweis_2, compu {0=Cx0_inaktiv (CM_KST_Fahrerhinweis_2_Cx0_inaktiv), 1=Cx1_aktiv (CM_KST_Fahrerhinweis_2_Cx1_aktiv)}, range raw 0..1, transfer-property=TRIGGERED-ON-CHANGE-WITHOUT-REPETITION  # Signalisierung Fahrerhinweis 2 der Klemmensteuerung an das Kombi
          signal KST_Fahrerhinweis_3_XIX_ClampControl_01_XIX_HCP5_CANFD01: start 28, 1 bit, little-endian, data-type-policy=OVERRIDE, i-signal-type=PRIMITIVE, init-value=0, base-type=BT_KST_Fahrerhinweis_3, compu {0=Cx0_inaktiv (CM_KST_Fahrerhinweis_3_Cx0_inaktiv), 1=Cx1_aktiv (CM_KST_Fahrerhinweis_3_Cx1_aktiv)}, range raw 0..1, transfer-property=TRIGGERED-ON-CHANGE-WITHOUT-REPETITION  # Signalisierung Fahrerhinweis 3 der Klemmensteuerung an das Kombi
          signal KST_Fahrerhinweis_4_XIX_ClampControl_01_XIX_HCP5_CANFD01: start 29, 1 bit, little-endian, data-type-policy=OVERRIDE, i-signal-type=PRIMITIVE, init-value=0, base-type=BT_KST_Fahrerhinweis_4, compu {0=Cx0_inaktiv (CM_KST_Fahrerhinweis_4_Cx0_inaktiv), 1=Cx1_aktiv (CM_KST_Fahrerhinweis_4_Cx1_aktiv)}, range raw 0..1, transfer-property=TRIGGERED-ON-CHANGE-WITHOUT-REPETITION  # Signalisierung Fahrerhinweis 4 der Klemmensteuerung an das Kombi
          signal KST_Fahrerhinweis_5_XIX_ClampControl_01_XIX_HCP5_CANFD01: start 30, 1 bit, little-endian, data-type-policy=OVERRIDE, i-signal-type=PRIMITIVE, init-value=0, base-type=BT_KST_Fahrerhinweis_5, compu {0=Cx0_inaktiv (CM_KST_Fahrerhinweis_5_Cx0_inaktiv), 1=Cx1_aktiv (CM_KST_Fahrerhinweis_5_Cx1_aktiv)}, range raw 0..1, transfer-property=TRIGGERED-ON-CHANGE-WITHOUT-REPETITION  # Anzeigesignal für RemoteStart
          signal KST_Fahrerhinweis_6_XIX_ClampControl_01_XIX_HCP5_CANFD01: start 31, 1 bit, little-endian, data-type-policy=OVERRIDE, i-signal-type=PRIMITIVE, init-value=0, base-type=BT_KST_Fahrerhinweis_6, compu {0=Cx0_inaktiv (CM_KST_Fahrerhinweis_6_Cx0_inaktiv), 1=Cx1_aktiv (CM_KST_Fahrerhinweis_6_Cx1_aktiv)}, range raw 0..1, transfer-property=TRIGGERED-ON-CHANGE-WITHOUT-REPETITION  # Signal aktiviert die Kombi-Anzeigeinstrumente (Drehzahl, Tankinhalt, Kühlmitteltemperatur) während aktiviertem RemoteStart-Betrieb
          signal KST_Txt_Panikabschaltung_XIX_ClampControl_01_XIX_HCP5_CANFD01: start 34, 1 bit, little-endian, data-type-policy=OVERRIDE, i-signal-type=PRIMITIVE, init-value=0, base-type=BT_KST_Txt_Panikabschaltung, compu {0=Cx0_Aus (CM_KST_Txt_Panikabschaltung_Cx0_Aus), 1=Cx1_Ein (CM_KST_Txt_Panikabschaltung_Cx1_Ein)}, range raw 0..1, transfer-property=TRIGGERED-ON-CHANGE-WITHOUT-REPETITION  # Text: 'Notabschaltung''
          signal KST_Anf_Klemmenfreigabe_ELV_XIX_ClampControl_01_XIX_HCP5_CANFD01: start 41, 1 bit, little-endian, data-type-policy=OVERRIDE, i-signal-type=PRIMITIVE, init-value=0, base-type=BT_KST_Anf_Klemmenfreigabe_ELV, compu {0=Cx0_nicht_angefordert (CM_KST_Anf_Klemmenfreigabe_ELV_Cx0_nicht_angefordert), 1=Cx1_angefordert (CM_KST_Anf_Klemmenfreigabe_ELV_Cx1_angefordert)}, range raw 0..1, transfer-property=PENDING  # Klemmensteuerung fordert Klemmen-Freigabe durch die ELV an.
          signal KST_aut_Abschaltung_Zuendung_XIX_ClampControl_01_XIX_HCP5_CANFD01: start 42, 1 bit, little-endian, data-type-policy=OVERRIDE, i-signal-type=PRIMITIVE, init-value=0, base-type=BT_KST_aut_Abschaltung_Zuendung, compu {0=Cx0_Zuendung_wird_bei_Verl_nicht_deaktiviert (CM_KST_aut_Abschaltung_Zuendung_Cx0_Zuendung_wird_bei_Verl_nicht_deaktiviert), 1=Cx1_Zuendung_wird_bei_Verl_deaktiviert (CM_KST_aut_Abschaltung_Zuendung_Cx1_Zuendung_wird_bei_Verl_deaktiviert)}, range raw 0..1, transfer-property=TRIGGERED-ON-CHANGE-WITHOUT-REPETITION  # Falls bei eingeschalteter Zündung das Abblendlicht aktiv war, muss nach der automatischen Abschaltung der Kl_15 & Kl_S, dass Standlicht aktiv bleiben. Das Signal sendet die Information, dass eine automatische Abschaltung der Kl_15 und Kl_S erfogt.
          signal KST_StPtAcvReq_XIX_ClampControl_01_XIX_HCP5_CANFD01: start 43, 2 bit, little-endian, data-type-policy=OVERRIDE, i-signal-type=PRIMITIVE, init-value=0, base-type=BT_KST_StPtAcvReq, compu {0=Cx0_NoActivationRequest (CM_KST_StPtAcvReq_Cx0_NoActivationRequest), 1=Cx1_StoredActivationRequest (CM_KST_StPtAcvReq_Cx1_StoredActivationRequest), 2=Cx2_CurrentActivationRequest (CM_KST_StPtAcvReq_Cx2_CurrentActivationRequest)}, range raw 0..2, transfer-property=TRIGGERED-ON-CHANGE-WITHOUT-REPETITION  # ZAT-activation-demand
          signal KST_StPtDeacReq_XIX_ClampControl_01_XIX_HCP5_CANFD01: start 45, 1 bit, little-endian, data-type-policy=OVERRIDE, i-signal-type=PRIMITIVE, init-value=0, base-type=BT_KST_StPtDeacReq, compu {0=Cx0_NoRequest (CM_KST_StPtDeacReq_Cx0_NoRequest), 1=Cx1_RequestDeactivatePowertrain (CM_KST_StPtDeacReq_Cx1_RequestDeactivatePowertrain)}, range raw 0..1, transfer-property=TRIGGERED-ON-CHANGE-WITHOUT-REPETITION  # Anforderung Deaktivierung des Antriebsstrangs durch Klemmensteuerung
          signal KST_ZAT_betaetigt_XIX_ClampControl_01_XIX_HCP5_CANFD01: start 46, 1 bit, little-endian, data-type-policy=OVERRIDE, i-signal-type=PRIMITIVE, init-value=0, base-type=BT_KST_ZAT_betaetigt, compu {0=Cx0_Aus (CM_KST_ZAT_betaetigt_Cx0_Aus), 1=Cx1_Ein (CM_KST_ZAT_betaetigt_Cx1_Ein)}, range raw 0..1, transfer-property=TRIGGERED-ON-CHANGE-WITHOUT-REPETITION  # Zündanlass-Taster (ZAT) betätigt
          signal KST_ComfortReadyStatus_XIX_ClampControl_01_XIX_HCP5_CANFD01: start 47, 1 bit, little-endian, data-type-policy=OVERRIDE, i-signal-type=PRIMITIVE, init-value=0, base-type=BT_KST_ComfortReadyStatus, compu {0=Cx0_aus (CM_KST_ComfortReadyStatus_Cx0_aus), 1=Cx1_ComfortReadyStatus_ein (CM_KST_ComfortReadyStatus_Cx1_ComfortReadyStatus_ein)}, range raw 0..1, transfer-property=TRIGGERED-ON-CHANGE-WITHOUT-REPETITION  # Zustand des ComfortReadyStatus über den Komfortfunktionen aktiviert werden können.
          signal KST_Sonderzustand_Anforderung_XIX_ClampControl_01_XIX_HCP5_CANFD01: start 48, 5 bit, little-endian, data-type-policy=OVERRIDE, i-signal-type=PRIMITIVE, init-value=0, base-type=BT_KST_Sonderzustand_Anforderung, invalid-value=Invalid_KST_Sonderzustand_Anforderung_XIX_ClampControl_01_XIX_HCP5_CANFD01:31, compu {0=Cx0_Init (CM_KST_Sonderzustand_Anforderung_Cx0_Init), 1=Cx1_RemoteStart (CM_KST_Sonderzustand_Anforderung_Cx1_RemoteStart), 2=Cx2_RemoteParkAssist (CM_KST_Sonderzustand_Anforderung_Cx2_RemoteParkAssist), 3=Cx3_IntelligentParkAssist (CM_KST_Sonderzustand_Anforderung_Cx3_IntelligentParkAssist), 4=Cx4_TrainiertesParken (CM_KST_Sonderzustand_Anforderung_Cx4_TrainiertesParken), 5=Cx5_OnlineRemoteUpdate (CM_KST_Sonderzustand_Anforderung_Cx5_OnlineRemoteUpdate), 6=Cx6_Einfrierschutz (CM_KST_Sonderzustand_Anforderung_Cx6_Einfrierschutz), 7=Cx7_Klemme15ViaDiagnose (CM_KST_Sonderzustand_Anforderung_Cx7_Klemme15ViaDiagnose), 8=Cx8_RueckwandklappenSicherungPDC (CM_KST_Sonderzustand_Anforderung_Cx8_RueckwandklappenSicherungPDC), 9=Cx9_ParkHausPilot (CM_KST_Sonderzustand_Anforderung_Cx9_ParkHausPilot), 10=Cxa_AnhaengerAnkuppelAssistent (CM_KST_Sonderzustand_Anforderung_Cxa_AnhaengerAnkuppelAssistent), 11=Cxb_MotorWeiterlaufSchaltung (CM_KST_Sonderzustand_Anforderung_Cxb_MotorWeiterlaufSchaltung), 31=Cx1f_Fehler (CM_KST_Sonderzustand_Anforderung_Cx1f_Fehler)}, range raw 0..31, transfer-property=TRIGGERED-ON-CHANGE-WITHOUT-REPETITION  # Hiermit wird die aktive bzw. aktuell angeforderte (s. KST_Sonderzustand_Status) Sonderfunktion identifiziert
          signal KST_WFS_Fahrfreigabe_Anforderung_XIX_ClampControl_01_XIX_HCP5_CANFD01: start 53, 2 bit, little-endian, data-type-policy=OVERRIDE, i-signal-type=PRIMITIVE, init-value=0, base-type=BT_KST_WFS_Fahrfreigabe_Anforderung, compu {0=Cx0_Keine (CM_KST_WFS_Fahrfreigabe_Anforderung_Cx0_Keine), 1=Cx1_Uneingeschraenkt (CM_KST_WFS_Fahrfreigabe_Anforderung_Cx1_Uneingeschraenkt), 2=Cx2_Eingeschraenkt (CM_KST_WFS_Fahrfreigabe_Anforderung_Cx2_Eingeschraenkt)}, range raw 0..2, transfer-property=TRIGGERED-ON-CHANGE-WITHOUT-REPETITION  # Hiermit wird den Wegfahrsperren-Teilnehmern signalisiert welche Art der Fahrfreigabe von der anfordernden Sonderfunktion benötigt wird
      frame DAAP_Funkt_Req_MC_FD_XIX_HCP5_CANFD01: id 0x1C413FDD, to BMC_HV, frame-length=8, can-addressing-mode=EXTENDED, can-frame-rx-behavior=CAN-FD, can-frame-tx-behavior=CAN-FD
        n pdu DAAP_Funkt_Req_MC_FD_XIX_HCP5_CANFD01: length=8
      frame DAAP_Hybrid_01_Req_FD_XIX_HCP5_CANFD01: id 0x1C403F7B, to BMC_HV, frame-length=64, can-addressing-mode=EXTENDED, can-frame-rx-behavior=CAN-FD, can-frame-tx-behavior=CAN-FD
        n pdu DAAP_Hybrid_01_Req_FD_XIX_HCP5_CANFD01: length=64
      frame DAAP_Hybrid_01_Resp_FD_XIX_HCP5_CANFD01: id 0x1C423F7B, from BMC_HV, frame-length=64, can-addressing-mode=EXTENDED, can-frame-rx-behavior=CAN-FD, can-frame-tx-behavior=CAN-FD
        n pdu DAAP_Hybrid_01_Resp_FD_XIX_HCP5_CANFD01: length=64
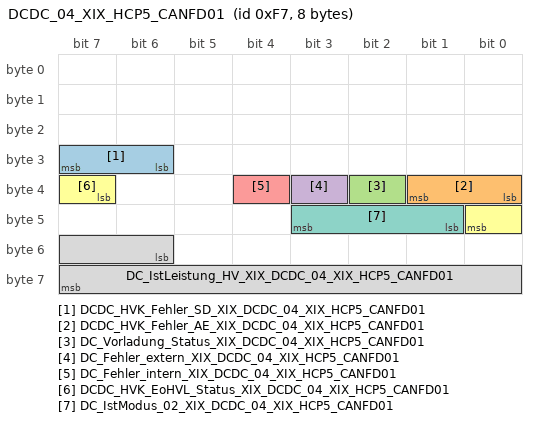
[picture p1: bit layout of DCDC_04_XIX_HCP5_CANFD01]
      frame DCDC_04_XIX_HCP5_CANFD01: id 0xF7, to BMC_HV, frame-length=8, can-addressing-mode=STANDARD, can-frame-rx-behavior=CAN-FD, can-frame-tx-behavior=CAN-FD
        pdu DCDC_04_XIX_HCP5_CANFD01: length=8, transmission-mode-true-timing=cyclic-timing={time-offset=0, time-period=0.01}, unused-bit-pattern=0
          signal DCDC_HVK_Fehler_SD_XIX_DCDC_04_XIX_HCP5_CANFD01: start 30, 2 bit, little-endian, data-type-policy=OVERRIDE, i-signal-type=PRIMITIVE, init-value=3, base-type=BT_DCDC_HVK_Fehler_SD, invalid-value=Invalid_DCDC_HVK_Fehler_SD_XIX_DCDC_04_XIX_HCP5_CANFD01:2, compu {0=Cx0_SD_gesteckt (CM_DCDC_HVK_Fehler_SD_Cx0_SD_gesteckt) (SD gesteckt), 1=Cx1_SD_gezogen (CM_DCDC_HVK_Fehler_SD_Cx1_SD_gezogen) (SD gezogen), 2=Cx2_Fehler (CM_DCDC_HVK_Fehler_SD_Cx2_Fehler), 3=Cx3_Init (CM_DCDC_HVK_Fehler_SD_Cx3_Init)}, range raw 0..3, transfer-property=PENDING  # Status Service Disconnect an DC/DC-Wandler
          signal DCDC_HVK_Fehler_AE_XIX_DCDC_04_XIX_HCP5_CANFD01: start 32, 2 bit, little-endian, data-type-policy=OVERRIDE, i-signal-type=PRIMITIVE, init-value=3, base-type=BT_DCDC_HVK_Fehler_AE, compu {0=Cx0_kein_Fehler_AE (CM_DCDC_HVK_Fehler_AE_Cx0_kein_Fehler_AE), 1=Cx1_Fehler_AE (CM_DCDC_HVK_Fehler_AE_Cx1_Fehler_AE), 3=Cx3_Init (CM_DCDC_HVK_Fehler_AE_Cx3_Init)}, range raw 0..3, transfer-property=PENDING  # Fehlerstatus aktive Entladung DC/DC-Wandler. In PPE: Status Aktive Entladung IPB (Integrated Power Box)
          signal DC_Vorladung_Status_XIX_DCDC_04_XIX_HCP5_CANFD01: start 34, 1 bit, little-endian, data-type-policy=OVERRIDE, i-signal-type=PRIMITIVE, init-value=0, base-type=BT_DC_Vorladung_Status, compu {0=Cx0_nicht_abgeschlossen (CM_DC_Vorladung_Status_Cx0_nicht_abgeschlossen), 1=Cx1_abgeschlossen (CM_DC_Vorladung_Status_Cx1_abgeschlossen)}, range raw 0..1, transfer-property=PENDING  # Status der ZK-Vorladung: =0, nicht_abgeschlossen =1, abgeschlossen DCDC-Wandler gibt Empfehlung für schließen der Schützen. HVK/BMS prüft die ZK-Spannung und entscheidet ob die Schütze geschlossen werden können.
          signal DC_Fehler_extern_XIX_DCDC_04_XIX_HCP5_CANFD01: start 35, 1 bit, little-endian, data-type-policy=OVERRIDE, i-signal-type=PRIMITIVE, init-value=0, base-type=BT_DC_Fehler_extern, invalid-value=Invalid_DC_Fehler_extern_XIX_DCDC_04_XIX_HCP5_CANFD01:1, compu {0=Cx0_kein_Fehler (CM_DC_Fehler_extern_Cx0_kein_Fehler), 1=Cx1_Fehler (CM_DC_Fehler_extern_Cx1_Fehler)}, range raw 0..1, transfer-property=PENDING  # Fehler/Abschaltung: DC/DC-Wandler ist aufgrund einer Umgebungsbedingung (z.B. HV-Spannung, NV-Spannung Kühlmitteltemperatur oder Systemfehler (ZK-Vorladung) ) nicht in der Lage geforderten Regelbetrieb einzuhalten.
          signal DC_Fehler_intern_XIX_DCDC_04_XIX_HCP5_CANFD01: start 36, 1 bit, little-endian, data-type-policy=OVERRIDE, i-signal-type=PRIMITIVE, init-value=0, base-type=BT_DC_Fehler_intern, compu {0=Cx0_kein_Fehler (CM_DC_Fehler_intern_Cx0_kein_Fehler), 1=Cx1_interner_Fehler_erkannt (CM_DC_Fehler_intern_Cx1_interner_Fehler_erkannt)}, range raw 0..1, transfer-property=PENDING  # Fehler: DC/DC-Wandler ist aufgrund eines internen Hardware-Fehlers abgeschaltet
          signal DCDC_HVK_EoHVL_Status_XIX_DCDC_04_XIX_HCP5_CANFD01: start 39, 2 bit, little-endian, data-type-policy=OVERRIDE, i-signal-type=PRIMITIVE, init-value=0, base-type=BT_DCDC_HVK_EoHVL_Status, invalid-value=Invalid_DCDC_HVK_EoHVL_Status_XIX_DCDC_04_XIX_HCP5_CANFD01:3, compu {0=Cx0_Init (CM_DCDC_HVK_EoHVL_Status_Cx0_Init), 1=Cx1_Uzwkr_kleiner_UEoHVL_Schwell (CM_DCDC_HVK_EoHVL_Status_Cx1_Uzwkr_kleiner_UEoHVL_Schwell), 2=Cx2_Uzwkr_groesgleich_UEoHVL_Schwell (CM_DCDC_HVK_EoHVL_Status_Cx2_Uzwkr_groesgleich_UEoHVL_Schwell), 3=Cx3_Fehler (CM_DCDC_HVK_EoHVL_Status_Cx3_Fehler)}, range raw 0..3, transfer-property=PENDING  # Erkennung einer offenen HV-Leitung (EoHVL), bewertet anhand einer Spannungsgrenze.
          signal DC_IstModus_02_XIX_DCDC_04_XIX_HCP5_CANFD01: start 41, 3 bit, little-endian, data-type-policy=OVERRIDE, i-signal-type=PRIMITIVE, init-value=7, base-type=BT_DC_IstModus_02, invalid-value=Invalid_DC_IstModus_02_XIX_DCDC_04_XIX_HCP5_CANFD01:5, compu {0=Cx0_Standby (CM_DC_IstModus_02_Cx0_Standby), 1=Cx1_HV_On_Vorladen (CM_DC_IstModus_02_Cx1_HV_On_Vorladen), 2=Cx2_Tiefsetzen (CM_DC_IstModus_02_Cx2_Tiefsetzen), 3=Cx3_Hochsetzen (CM_DC_IstModus_02_Cx3_Hochsetzen), 4=Cx4_Pruefimpuls_12V (CM_DC_IstModus_02_Cx4_Pruefimpuls_12V), 5=Cx5_Fehler (CM_DC_IstModus_02_Cx5_Fehler), 7=Cx7_Initialisierung (CM_DC_IstModus_02_Cx7_Initialisierung)}, range raw 0..7, transfer-property=PENDING  # aktuelle Betriebsart des DC/DC Wandlers; 0: Standby; Kommunikation aktiv 1: HV_On_Vorladen 2: Tiefsetzen 3: Hochsetzen 4: Pruefimpuls_12V 5: interner Fehler DC/DC-Wandler / angeforderter Sollmodus kann nicht eingestellt werden 6: reserve 7: Initialisierung
          signal DC_IstLeistung_HV_XIX_DCDC_04_XIX_HCP5_CANFD01: start 54, 10 bit, little-endian, data-type-policy=OVERRIDE, i-signal-type=PRIMITIVE, init-value=1022, base-type=BT_DC_IstLeistung_HV, invalid-value=Invalid_DC_IstLeistung_HV_XIX_DCDC_04_XIX_HCP5_CANFD01:1023, compu {phys=raw*10-4000 for raw 0..1021, 1022=Cx3fe_Init (CM_DC_IstLeistung_HV_Cx3fe_Init), 1023=Cx3ff_Fehler (CM_DC_IstLeistung_HV_Cx3ff_Fehler); unit Unit_Watt}, range phys -4000..6210 Unit_Watt, raw 0..1023, unit=Unit_Watt, transfer-property=PENDING, to BMC_HV(timeout 0.5 s)  # Aktuelle Ist-Leistung des Bordnetzwandlers auf der HV-Seite. Tiefsetzen - positiv Hochsetzen- negativ
      frame DCDC_NV_CALID_XIX_HCP5_CANFD01: id 0x1A5556B4, to BMC_HV, frame-length=16, can-addressing-mode=EXTENDED, can-frame-rx-behavior=CAN-FD, can-frame-tx-behavior=CAN-FD
        pdu DCDC_NV_CALID_XIX_HCP5_CANFD01: length=16, transmission-mode-true-timing=cyclic-timing={time-offset=0, time-period=1}, unused-bit-pattern=0
          signal DCDC_NV_CALID_Index_01_XIX_DCDC_NV_CALID_XIX_HCP5_CANFD01: start 0, 8 bit, little-endian, data-type-policy=OVERRIDE, i-signal-type=PRIMITIVE, init-value=63, base-type=BT_DCDC_NV_CALID_Index_01, compu {phys=raw for raw 0..255}, range phys 0..255, raw 0..255, transfer-property=PENDING, to BMC_HV(timeout 5 s)  # Calibration Identification
          signal DCDC_NV_CALID_Index_02_XIX_DCDC_NV_CALID_XIX_HCP5_CANFD01: start 8, 8 bit, little-endian, data-type-policy=OVERRIDE, i-signal-type=PRIMITIVE, init-value=63, base-type=BT_DCDC_NV_CALID_Index_02, compu {phys=raw for raw 0..255}, range phys 0..255, raw 0..255, transfer-property=PENDING, to BMC_HV(timeout 5 s)  # Calibration Identification
          signal DCDC_NV_CALID_Index_03_XIX_DCDC_NV_CALID_XIX_HCP5_CANFD01: start 16, 8 bit, little-endian, data-type-policy=OVERRIDE, i-signal-type=PRIMITIVE, init-value=63, base-type=BT_DCDC_NV_CALID_Index_03, compu {phys=raw for raw 0..255}, range phys 0..255, raw 0..255, transfer-property=PENDING, to BMC_HV(timeout 5 s)  # Calibration Identification
          signal DCDC_NV_CALID_Index_04_XIX_DCDC_NV_CALID_XIX_HCP5_CANFD01: start 24, 8 bit, little-endian, data-type-policy=OVERRIDE, i-signal-type=PRIMITIVE, init-value=63, base-type=BT_DCDC_NV_CALID_Index_04, compu {phys=raw for raw 0..255}, range phys 0..255, raw 0..255, transfer-property=PENDING, to BMC_HV(timeout 5 s)  # Calibration Identification
          signal DCDC_NV_CALID_Index_05_XIX_DCDC_NV_CALID_XIX_HCP5_CANFD01: start 32, 8 bit, little-endian, data-type-policy=OVERRIDE, i-signal-type=PRIMITIVE, init-value=63, base-type=BT_DCDC_NV_CALID_Index_05, compu {phys=raw for raw 0..255}, range phys 0..255, raw 0..255, transfer-property=PENDING, to BMC_HV(timeout 5 s)  # Calibration Identification
          signal DCDC_NV_CALID_Index_06_XIX_DCDC_NV_CALID_XIX_HCP5_CANFD01: start 40, 8 bit, little-endian, data-type-policy=OVERRIDE, i-signal-type=PRIMITIVE, init-value=63, base-type=BT_DCDC_NV_CALID_Index_06, compu {phys=raw for raw 0..255}, range phys 0..255, raw 0..255, transfer-property=PENDING, to BMC_HV(timeout 5 s)  # Calibration Identification
          signal DCDC_NV_CALID_Index_07_XIX_DCDC_NV_CALID_XIX_HCP5_CANFD01: start 48, 8 bit, little-endian, data-type-policy=OVERRIDE, i-signal-type=PRIMITIVE, init-value=63, base-type=BT_DCDC_NV_CALID_Index_07, compu {phys=raw for raw 0..255}, range phys 0..255, raw 0..255, transfer-property=PENDING, to BMC_HV(timeout 5 s)  # Calibration Identification
          signal DCDC_NV_CALID_Index_08_XIX_DCDC_NV_CALID_XIX_HCP5_CANFD01: start 56, 8 bit, little-endian, data-type-policy=OVERRIDE, i-signal-type=PRIMITIVE, init-value=63, base-type=BT_DCDC_NV_CALID_Index_08, compu {phys=raw for raw 0..255}, range phys 0..255, raw 0..255, transfer-property=PENDING, to BMC_HV(timeout 5 s)  # Calibration Identification
          signal DCDC_NV_CALID_Index_09_XIX_DCDC_NV_CALID_XIX_HCP5_CANFD01: start 64, 8 bit, little-endian, data-type-policy=OVERRIDE, i-signal-type=PRIMITIVE, init-value=63, base-type=BT_DCDC_NV_CALID_Index_09, compu {phys=raw for raw 0..255}, range phys 0..255, raw 0..255, transfer-property=PENDING, to BMC_HV(timeout 5 s)  # Calibration Identification
          signal DCDC_NV_CALID_Index_10_XIX_DCDC_NV_CALID_XIX_HCP5_CANFD01: start 72, 8 bit, little-endian, data-type-policy=OVERRIDE, i-signal-type=PRIMITIVE, init-value=63, base-type=BT_DCDC_NV_CALID_Index_10, compu {phys=raw for raw 0..255}, range phys 0..255, raw 0..255, transfer-property=PENDING, to BMC_HV(timeout 5 s)  # Calibration Identification
          signal DCDC_NV_CALID_Index_11_XIX_DCDC_NV_CALID_XIX_HCP5_CANFD01: start 80, 8 bit, little-endian, data-type-policy=OVERRIDE, i-signal-type=PRIMITIVE, init-value=63, base-type=BT_DCDC_NV_CALID_Index_11, compu {phys=raw for raw 0..255}, range phys 0..255, raw 0..255, transfer-property=PENDING, to BMC_HV(timeout 5 s)  # Calibration Identification
          signal DCDC_NV_CALID_Index_12_XIX_DCDC_NV_CALID_XIX_HCP5_CANFD01: start 88, 8 bit, little-endian, data-type-policy=OVERRIDE, i-signal-type=PRIMITIVE, init-value=63, base-type=BT_DCDC_NV_CALID_Index_12, compu {phys=raw for raw 0..255}, range phys 0..255, raw 0..255, transfer-property=PENDING, to BMC_HV(timeout 5 s)  # Calibration Identification
          signal DCDC_NV_CALID_Index_13_XIX_DCDC_NV_CALID_XIX_HCP5_CANFD01: start 96, 8 bit, little-endian, data-type-policy=OVERRIDE, i-signal-type=PRIMITIVE, init-value=63, base-type=BT_DCDC_NV_CALID_Index_13, compu {phys=raw for raw 0..255}, range phys 0..255, raw 0..255, transfer-property=PENDING, to BMC_HV(timeout 5 s)  # Calibration Identification
          signal DCDC_NV_CALID_Index_14_XIX_DCDC_NV_CALID_XIX_HCP5_CANFD01: start 104, 8 bit, little-endian, data-type-policy=OVERRIDE, i-signal-type=PRIMITIVE, init-value=63, base-type=BT_DCDC_NV_CALID_Index_14, compu {phys=raw for raw 0..255}, range phys 0..255, raw 0..255, transfer-property=PENDING, to BMC_HV(timeout 5 s)  # Calibration Identification
          signal DCDC_NV_CALID_Index_15_XIX_DCDC_NV_CALID_XIX_HCP5_CANFD01: start 112, 8 bit, little-endian, data-type-policy=OVERRIDE, i-signal-type=PRIMITIVE, init-value=63, base-type=BT_DCDC_NV_CALID_Index_15, compu {phys=raw for raw 0..255}, range phys 0..255, raw 0..255, transfer-property=PENDING, to BMC_HV(timeout 5 s)  # Calibration Identification
          signal DCDC_NV_CALID_Index_16_XIX_DCDC_NV_CALID_XIX_HCP5_CANFD01: start 120, 8 bit, little-endian, data-type-policy=OVERRIDE, i-signal-type=PRIMITIVE, init-value=63, base-type=BT_DCDC_NV_CALID_Index_16, compu {phys=raw for raw 0..255}, range phys 0..255, raw 0..255, transfer-property=PENDING, to BMC_HV(timeout 5 s)  # Calibration Identification
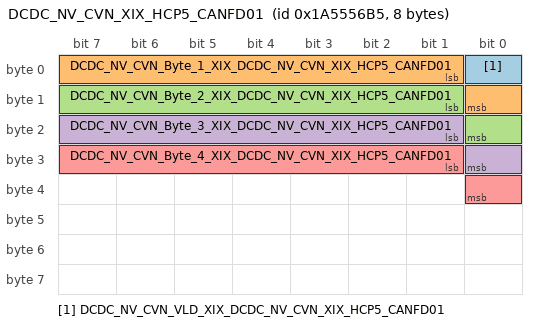
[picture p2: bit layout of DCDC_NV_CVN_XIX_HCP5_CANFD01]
      frame DCDC_NV_CVN_XIX_HCP5_CANFD01: id 0x1A5556B5, to BMC_HV, frame-length=8, can-addressing-mode=EXTENDED, can-frame-rx-behavior=CAN-FD, can-frame-tx-behavior=CAN-FD
        pdu DCDC_NV_CVN_XIX_HCP5_CANFD01: length=8, transmission-mode-true-timing=cyclic-timing={time-offset=0, time-period=1}, unused-bit-pattern=0
          signal DCDC_NV_CVN_VLD_XIX_DCDC_NV_CVN_XIX_HCP5_CANFD01: start 0, 1 bit, little-endian, data-type-policy=OVERRIDE, i-signal-type=PRIMITIVE, init-value=0, base-type=BT_DCDC_NV_CVN_VLD, compu {0=Cx0_Ungueltig (CM_DCDC_NV_CVN_VLD_Cx0_Ungueltig), 1=Cx1_Gueltig (CM_DCDC_NV_CVN_VLD_Cx1_Gueltig)}, range raw 0..1, transfer-property=PENDING, to BMC_HV(timeout 5 s)  # Über dieses Signal wird gekennzeichnet, ob die Berechnung der CVN im SecondaryOBDECU abgeschlossen ist.
          signal DCDC_NV_CVN_Byte_1_XIX_DCDC_NV_CVN_XIX_HCP5_CANFD01: start 1, 8 bit, little-endian, data-type-policy=OVERRIDE, i-signal-type=PRIMITIVE, init-value=0, base-type=BT_DCDC_NV_CVN_Byte_1, compu {phys=raw for raw 0..255}, range phys 0..255, raw 0..255, transfer-property=PENDING, to BMC_HV(timeout 5 s)  # Calibration Verification Number
          signal DCDC_NV_CVN_Byte_2_XIX_DCDC_NV_CVN_XIX_HCP5_CANFD01: start 9, 8 bit, little-endian, data-type-policy=OVERRIDE, i-signal-type=PRIMITIVE, init-value=0, base-type=BT_DCDC_NV_CVN_Byte_2, compu {phys=raw for raw 0..255}, range phys 0..255, raw 0..255, transfer-property=PENDING, to BMC_HV(timeout 5 s)  # Calibration Verification Number
          signal DCDC_NV_CVN_Byte_3_XIX_DCDC_NV_CVN_XIX_HCP5_CANFD01: start 17, 8 bit, little-endian, data-type-policy=OVERRIDE, i-signal-type=PRIMITIVE, init-value=0, base-type=BT_DCDC_NV_CVN_Byte_3, compu {phys=raw for raw 0..255}, range phys 0..255, raw 0..255, transfer-property=PENDING, to BMC_HV(timeout 5 s)  # Calibration Verification Number
          signal DCDC_NV_CVN_Byte_4_XIX_DCDC_NV_CVN_XIX_HCP5_CANFD01: start 25, 8 bit, little-endian, data-type-policy=OVERRIDE, i-signal-type=PRIMITIVE, init-value=0, base-type=BT_DCDC_NV_CVN_Byte_4, compu {phys=raw for raw 0..255}, range phys 0..255, raw 0..255, transfer-property=PENDING, to BMC_HV(timeout 5 s)  # Calibration Verification Number
      frame DCDC_NV_Komponentenfehler_01_XIX_HCP5_CANFD01: id 0x1A5556B0, to BMC_HV, frame-length=8, can-addressing-mode=EXTENDED, can-frame-rx-behavior=CAN-FD, can-frame-tx-behavior=CAN-FD
        pdu DCDC_NV_Komponentenfehler_01_XIX_HCP5_CANFD01: length=8, transmission-mode-true-timing=cyclic-timing={time-offset=0, time-period=0.5}, unused-bit-pattern=0
          signal DCDC_NV_Komponentenfehler_01_XIX_DCDC_NV_Komponentenfehler_01_XIX_HCP5_CANFD01: start 0, 2 bit, little-endian, data-type-policy=OVERRIDE, i-signal-type=PRIMITIVE, init-value=0, base-type=BT_DCDC_NV_Komponentenfehler_01, compu {0=Cx0_TstNotComplThisOpCycle_Init (CM_DCDC_NV_Komponentenfehler_01_Cx0_TstNotComplThisOpCycle_Init), 1=Cx1_TstComplThisOpCycle_Pass (CM_DCDC_NV_Komponentenfehler_01_Cx1_TstComplThisOpCycle_Pass), 2=Cx2_TstCmplThisCycle_Pass_TimeElapse (CM_DCDC_NV_Komponentenfehler_01_Cx2_TstCmplThisCycle_Pass_TimeElapse), 3=Cx3_TstComplThisOpCycle_FAIL (CM_DCDC_NV_Komponentenfehler_01_Cx3_TstComplThisOpCycle_FAIL)}, range raw 0..3, transfer-property=PENDING, to BMC_HV(timeout 5 s)  # Übertragung OBD relevanter Fehlerpfade vom Secondary zum Primary Steuergerät. Zuordnung der generischen Komponentenfehler muss zwischen Sender und Empfänger abgestimmt werden.
          signal DCDC_NV_Komponentenfehler_02_XIX_DCDC_NV_Komponentenfehler_01_XIX_HCP5_CANFD01: start 2, 2 bit, little-endian, data-type-policy=OVERRIDE, i-signal-type=PRIMITIVE, init-value=0, base-type=BT_DCDC_NV_Komponentenfehler_02, compu {0=Cx0_TstNotComplThisOpCycle_Init (CM_DCDC_NV_Komponentenfehler_02_Cx0_TstNotComplThisOpCycle_Init), 1=Cx1_TstComplThisOpCycle_Pass (CM_DCDC_NV_Komponentenfehler_02_Cx1_TstComplThisOpCycle_Pass), 2=Cx2_TstCmplThisCycle_Pass_TimeElapse (CM_DCDC_NV_Komponentenfehler_02_Cx2_TstCmplThisCycle_Pass_TimeElapse), 3=Cx3_TstComplThisOpCycle_FAIL (CM_DCDC_NV_Komponentenfehler_02_Cx3_TstComplThisOpCycle_FAIL)}, range raw 0..3, transfer-property=PENDING, to BMC_HV(timeout 5 s)  # Übertragung OBD relevanter Fehlerpfade vom Secondary zum Primary Steuergerät. Zuordnung der generischen Komponentenfehler muss zwischen Sender und Empfänger abgestimmt werden.
          signal DCDC_NV_Komponentenfehler_03_XIX_DCDC_NV_Komponentenfehler_01_XIX_HCP5_CANFD01: start 4, 2 bit, little-endian, data-type-policy=OVERRIDE, i-signal-type=PRIMITIVE, init-value=0, base-type=BT_DCDC_NV_Komponentenfehler_03, compu {0=Cx0_TstNotComplThisOpCycle_Init (CM_DCDC_NV_Komponentenfehler_03_Cx0_TstNotComplThisOpCycle_Init), 1=Cx1_TstComplThisOpCycle_Pass (CM_DCDC_NV_Komponentenfehler_03_Cx1_TstComplThisOpCycle_Pass), 2=Cx2_TstCmplThisCycle_Pass_TimeElapse (CM_DCDC_NV_Komponentenfehler_03_Cx2_TstCmplThisCycle_Pass_TimeElapse), 3=Cx3_TstComplThisOpCycle_FAIL (CM_DCDC_NV_Komponentenfehler_03_Cx3_TstComplThisOpCycle_FAIL)}, range raw 0..3, transfer-property=PENDING, to BMC_HV(timeout 5 s)  # Übertragung OBD relevanter Fehlerpfade vom Secondary zum Primary Steuergerät. Zuordnung der generischen Komponentenfehler muss zwischen Sender und Empfänger abgestimmt werden.
          signal DCDC_NV_Komponentenfehler_04_XIX_DCDC_NV_Komponentenfehler_01_XIX_HCP5_CANFD01: start 6, 2 bit, little-endian, data-type-policy=OVERRIDE, i-signal-type=PRIMITIVE, init-value=0, base-type=BT_DCDC_NV_Komponentenfehler_04, compu {0=Cx0_TstNotComplThisOpCycle_Init (CM_DCDC_NV_Komponentenfehler_04_Cx0_TstNotComplThisOpCycle_Init), 1=Cx1_TstComplThisOpCycle_Pass (CM_DCDC_NV_Komponentenfehler_04_Cx1_TstComplThisOpCycle_Pass), 2=Cx2_TstCmplThisCycle_Pass_TimeElapse (CM_DCDC_NV_Komponentenfehler_04_Cx2_TstCmplThisCycle_Pass_TimeElapse), 3=Cx3_TstComplThisOpCycle_FAIL (CM_DCDC_NV_Komponentenfehler_04_Cx3_TstComplThisOpCycle_FAIL)}, range raw 0..3, transfer-property=PENDING, to BMC_HV(timeout 5 s)  # Übertragung OBD relevanter Fehlerpfade vom Secondary zum Primary Steuergerät. Zuordnung der generischen Komponentenfehler muss zwischen Sender und Empfänger abgestimmt werden.
          signal DCDC_NV_Komponentenfehler_05_XIX_DCDC_NV_Komponentenfehler_01_XIX_HCP5_CANFD01: start 8, 2 bit, little-endian, data-type-policy=OVERRIDE, i-signal-type=PRIMITIVE, init-value=0, base-type=BT_DCDC_NV_Komponentenfehler_05, compu {0=Cx0_TstNotComplThisOpCycle_Init (CM_DCDC_NV_Komponentenfehler_05_Cx0_TstNotComplThisOpCycle_Init), 1=Cx1_TstComplThisOpCycle_Pass (CM_DCDC_NV_Komponentenfehler_05_Cx1_TstComplThisOpCycle_Pass), 2=Cx2_TstCmplThisCycle_Pass_TimeElapse (CM_DCDC_NV_Komponentenfehler_05_Cx2_TstCmplThisCycle_Pass_TimeElapse), 3=Cx3_TstComplThisOpCycle_FAIL (CM_DCDC_NV_Komponentenfehler_05_Cx3_TstComplThisOpCycle_FAIL)}, range raw 0..3, transfer-property=PENDING, to BMC_HV(timeout 5 s)  # Übertragung OBD relevanter Fehlerpfade vom Secondary zum Primary Steuergerät. Zuordnung der generischen Komponentenfehler muss zwischen Sender und Empfänger abgestimmt werden.
          signal DCDC_NV_Komponentenfehler_06_XIX_DCDC_NV_Komponentenfehler_01_XIX_HCP5_CANFD01: start 10, 2 bit, little-endian, data-type-policy=OVERRIDE, i-signal-type=PRIMITIVE, init-value=0, base-type=BT_DCDC_NV_Komponentenfehler_06, compu {0=Cx0_TstNotComplThisOpCycle_Init (CM_DCDC_NV_Komponentenfehler_06_Cx0_TstNotComplThisOpCycle_Init), 1=Cx1_TstComplThisOpCycle_Pass (CM_DCDC_NV_Komponentenfehler_06_Cx1_TstComplThisOpCycle_Pass), 2=Cx2_TstCmplThisCycle_Pass_TimeElapse (CM_DCDC_NV_Komponentenfehler_06_Cx2_TstCmplThisCycle_Pass_TimeElapse), 3=Cx3_TstComplThisOpCycle_FAIL (CM_DCDC_NV_Komponentenfehler_06_Cx3_TstComplThisOpCycle_FAIL)}, range raw 0..3, transfer-property=PENDING, to BMC_HV(timeout 5 s)  # Übertragung OBD relevanter Fehlerpfade vom Secondary zum Primary Steuergerät. Zuordnung der generischen Komponentenfehler muss zwischen Sender und Empfänger abgestimmt werden.
          signal DCDC_NV_Komponentenfehler_07_XIX_DCDC_NV_Komponentenfehler_01_XIX_HCP5_CANFD01: start 12, 2 bit, little-endian, data-type-policy=OVERRIDE, i-signal-type=PRIMITIVE, init-value=0, base-type=BT_DCDC_NV_Komponentenfehler_07, compu {0=Cx0_TstNotComplThisOpCycle_Init (CM_DCDC_NV_Komponentenfehler_07_Cx0_TstNotComplThisOpCycle_Init), 1=Cx1_TstComplThisOpCycle_Pass (CM_DCDC_NV_Komponentenfehler_07_Cx1_TstComplThisOpCycle_Pass), 2=Cx2_TstCmplThisCycle_Pass_TimeElapse (CM_DCDC_NV_Komponentenfehler_07_Cx2_TstCmplThisCycle_Pass_TimeElapse), 3=Cx3_TstComplThisOpCycle_FAIL (CM_DCDC_NV_Komponentenfehler_07_Cx3_TstComplThisOpCycle_FAIL)}, range raw 0..3, transfer-property=PENDING, to BMC_HV(timeout 5 s)  # Übertragung OBD relevanter Fehlerpfade vom Secondary zum Primary Steuergerät. Zuordnung der generischen Komponentenfehler muss zwischen Sender und Empfänger abgestimmt werden.
          signal DCDC_NV_Komponentenfehler_08_XIX_DCDC_NV_Komponentenfehler_01_XIX_HCP5_CANFD01: start 14, 2 bit, little-endian, data-type-policy=OVERRIDE, i-signal-type=PRIMITIVE, init-value=0, base-type=BT_DCDC_NV_Komponentenfehler_08, compu {0=Cx0_TstNotComplThisOpCycle_Init (CM_DCDC_NV_Komponentenfehler_08_Cx0_TstNotComplThisOpCycle_Init), 1=Cx1_TstComplThisOpCycle_Pass (CM_DCDC_NV_Komponentenfehler_08_Cx1_TstComplThisOpCycle_Pass), 2=Cx2_TstCmplThisCycle_Pass_TimeElapse (CM_DCDC_NV_Komponentenfehler_08_Cx2_TstCmplThisCycle_Pass_TimeElapse), 3=Cx3_TstComplThisOpCycle_FAIL (CM_DCDC_NV_Komponentenfehler_08_Cx3_TstComplThisOpCycle_FAIL)}, range raw 0..3, transfer-property=PENDING, to BMC_HV(timeout 5 s)  # Übertragung OBD relevanter Fehlerpfade vom Secondary zum Primary Steuergerät. Zuordnung der generischen Komponentenfehler muss zwischen Sender und Empfänger abgestimmt werden.
          signal DCDC_NV_Komponentenfehler_09_XIX_DCDC_NV_Komponentenfehler_01_XIX_HCP5_CANFD01: start 16, 2 bit, little-endian, data-type-policy=OVERRIDE, i-signal-type=PRIMITIVE, init-value=0, base-type=BT_DCDC_NV_Komponentenfehler_09, compu {0=Cx0_TstNotComplThisOpCycle_Init (CM_DCDC_NV_Komponentenfehler_09_Cx0_TstNotComplThisOpCycle_Init), 1=Cx1_TstComplThisOpCycle_Pass (CM_DCDC_NV_Komponentenfehler_09_Cx1_TstComplThisOpCycle_Pass), 2=Cx2_TstCmplThisCycle_Pass_TimeElapse (CM_DCDC_NV_Komponentenfehler_09_Cx2_TstCmplThisCycle_Pass_TimeElapse), 3=Cx3_TstComplThisOpCycle_FAIL (CM_DCDC_NV_Komponentenfehler_09_Cx3_TstComplThisOpCycle_FAIL)}, range raw 0..3, transfer-property=PENDING, to BMC_HV(timeout 5 s)  # Übertragung OBD relevanter Fehlerpfade vom Secondary zum Primary Steuergerät. Zuordnung der generischen Komponentenfehler muss zwischen Sender und Empfänger abgestimmt werden.
          signal DCDC_NV_Komponentenfehler_10_XIX_DCDC_NV_Komponentenfehler_01_XIX_HCP5_CANFD01: start 18, 2 bit, little-endian, data-type-policy=OVERRIDE, i-signal-type=PRIMITIVE, init-value=0, base-type=BT_DCDC_NV_Komponentenfehler_10, compu {0=Cx0_TstNotComplThisOpCycle_Init (CM_DCDC_NV_Komponentenfehler_10_Cx0_TstNotComplThisOpCycle_Init), 1=Cx1_TstComplThisOpCycle_Pass (CM_DCDC_NV_Komponentenfehler_10_Cx1_TstComplThisOpCycle_Pass), 2=Cx2_TstCmplThisCycle_Pass_TimeElapse (CM_DCDC_NV_Komponentenfehler_10_Cx2_TstCmplThisCycle_Pass_TimeElapse), 3=Cx3_TstComplThisOpCycle_FAIL (CM_DCDC_NV_Komponentenfehler_10_Cx3_TstComplThisOpCycle_FAIL)}, range raw 0..3, transfer-property=PENDING, to BMC_HV(timeout 5 s)  # Übertragung OBD relevanter Fehlerpfade vom Secondary zum Primary Steuergerät. Zuordnung der generischen Komponentenfehler muss zwischen Sender und Empfänger abgestimmt werden.
          signal DCDC_NV_Komponentenfehler_11_XIX_DCDC_NV_Komponentenfehler_01_XIX_HCP5_CANFD01: start 20, 2 bit, little-endian, data-type-policy=OVERRIDE, i-signal-type=PRIMITIVE, init-value=0, base-type=BT_DCDC_NV_Komponentenfehler_11, compu {0=Cx0_TstNotComplThisOpCycle_Init (CM_DCDC_NV_Komponentenfehler_11_Cx0_TstNotComplThisOpCycle_Init), 1=Cx1_TstComplThisOpCycle_Pass (CM_DCDC_NV_Komponentenfehler_11_Cx1_TstComplThisOpCycle_Pass), 2=Cx2_TstCmplThisCycle_Pass_TimeElapse (CM_DCDC_NV_Komponentenfehler_11_Cx2_TstCmplThisCycle_Pass_TimeElapse), 3=Cx3_TstComplThisOpCycle_FAIL (CM_DCDC_NV_Komponentenfehler_11_Cx3_TstComplThisOpCycle_FAIL)}, range raw 0..3, transfer-property=PENDING, to BMC_HV(timeout 5 s)  # Übertragung OBD relevanter Fehlerpfade vom Secondary zum Primary Steuergerät. Zuordnung der generischen Komponentenfehler muss zwischen Sender und Empfänger abgestimmt werden.
          signal DCDC_NV_Komponentenfehler_12_XIX_DCDC_NV_Komponentenfehler_01_XIX_HCP5_CANFD01: start 22, 2 bit, little-endian, data-type-policy=OVERRIDE, i-signal-type=PRIMITIVE, init-value=0, base-type=BT_DCDC_NV_Komponentenfehler_12, compu {0=Cx0_TstNotComplThisOpCycle_Init (CM_DCDC_NV_Komponentenfehler_12_Cx0_TstNotComplThisOpCycle_Init), 1=Cx1_TstComplThisOpCycle_Pass (CM_DCDC_NV_Komponentenfehler_12_Cx1_TstComplThisOpCycle_Pass), 2=Cx2_TstCmplThisCycle_Pass_TimeElapse (CM_DCDC_NV_Komponentenfehler_12_Cx2_TstCmplThisCycle_Pass_TimeElapse), 3=Cx3_TstComplThisOpCycle_FAIL (CM_DCDC_NV_Komponentenfehler_12_Cx3_TstComplThisOpCycle_FAIL)}, range raw 0..3, transfer-property=PENDING, to BMC_HV(timeout 5 s)  # Übertragung OBD relevanter Fehlerpfade vom Secondary zum Primary Steuergerät. Zuordnung der generischen Komponentenfehler muss zwischen Sender und Empfänger abgestimmt werden.
          signal DCDC_NV_Komponentenfehler_13_XIX_DCDC_NV_Komponentenfehler_01_XIX_HCP5_CANFD01: start 24, 2 bit, little-endian, data-type-policy=OVERRIDE, i-signal-type=PRIMITIVE, init-value=0, base-type=BT_DCDC_NV_Komponentenfehler_13, compu {0=Cx0_TstNotComplThisOpCycle_Init (CM_DCDC_NV_Komponentenfehler_13_Cx0_TstNotComplThisOpCycle_Init), 1=Cx1_TstComplThisOpCycle_Pass (CM_DCDC_NV_Komponentenfehler_13_Cx1_TstComplThisOpCycle_Pass), 2=Cx2_TstCmplThisCycle_Pass_TimeElapse (CM_DCDC_NV_Komponentenfehler_13_Cx2_TstCmplThisCycle_Pass_TimeElapse), 3=Cx3_TstComplThisOpCycle_FAIL (CM_DCDC_NV_Komponentenfehler_13_Cx3_TstComplThisOpCycle_FAIL)}, range raw 0..3, transfer-property=PENDING, to BMC_HV(timeout 5 s)  # Übertragung OBD relevanter Fehlerpfade vom Secondary zum Primary Steuergerät. Zuordnung der generischen Komponentenfehler muss zwischen Sender und Empfänger abgestimmt werden.
          signal DCDC_NV_Komponentenfehler_14_XIX_DCDC_NV_Komponentenfehler_01_XIX_HCP5_CANFD01: start 26, 2 bit, little-endian, data-type-policy=OVERRIDE, i-signal-type=PRIMITIVE, init-value=0, base-type=BT_DCDC_NV_Komponentenfehler_14, compu {0=Cx0_TstNotComplThisOpCycle_Init (CM_DCDC_NV_Komponentenfehler_14_Cx0_TstNotComplThisOpCycle_Init), 1=Cx1_TstComplThisOpCycle_Pass (CM_DCDC_NV_Komponentenfehler_14_Cx1_TstComplThisOpCycle_Pass), 2=Cx2_TstCmplThisCycle_Pass_TimeElapse (CM_DCDC_NV_Komponentenfehler_14_Cx2_TstCmplThisCycle_Pass_TimeElapse), 3=Cx3_TstComplThisOpCycle_FAIL (CM_DCDC_NV_Komponentenfehler_14_Cx3_TstComplThisOpCycle_FAIL)}, range raw 0..3, transfer-property=PENDING, to BMC_HV(timeout 5 s)  # Übertragung OBD relevanter Fehlerpfade vom Secondary zum Primary Steuergerät. Zuordnung der generischen Komponentenfehler muss zwischen Sender und Empfänger abgestimmt werden.
          signal DCDC_NV_Komponentenfehler_15_XIX_DCDC_NV_Komponentenfehler_01_XIX_HCP5_CANFD01: start 28, 2 bit, little-endian, data-type-policy=OVERRIDE, i-signal-type=PRIMITIVE, init-value=0, base-type=BT_DCDC_NV_Komponentenfehler_15, compu {0=Cx0_TstNotComplThisOpCycle_Init (CM_DCDC_NV_Komponentenfehler_15_Cx0_TstNotComplThisOpCycle_Init), 1=Cx1_TstComplThisOpCycle_Pass (CM_DCDC_NV_Komponentenfehler_15_Cx1_TstComplThisOpCycle_Pass), 2=Cx2_TstCmplThisCycle_Pass_TimeElapse (CM_DCDC_NV_Komponentenfehler_15_Cx2_TstCmplThisCycle_Pass_TimeElapse), 3=Cx3_TstComplThisOpCycle_FAIL (CM_DCDC_NV_Komponentenfehler_15_Cx3_TstComplThisOpCycle_FAIL)}, range raw 0..3, transfer-property=PENDING, to BMC_HV(timeout 5 s)  # Übertragung OBD relevanter Fehlerpfade vom Secondary zum Primary Steuergerät. Zuordnung der generischen Komponentenfehler muss zwischen Sender und Empfänger abgestimmt werden.
          signal DCDC_NV_Komponentenfehler_16_XIX_DCDC_NV_Komponentenfehler_01_XIX_HCP5_CANFD01: start 30, 2 bit, little-endian, data-type-policy=OVERRIDE, i-signal-type=PRIMITIVE, init-value=0, base-type=BT_DCDC_NV_Komponentenfehler_16, compu {0=Cx0_TstNotComplThisOpCycle_Init (CM_DCDC_NV_Komponentenfehler_16_Cx0_TstNotComplThisOpCycle_Init), 1=Cx1_TstComplThisOpCycle_Pass (CM_DCDC_NV_Komponentenfehler_16_Cx1_TstComplThisOpCycle_Pass), 2=Cx2_TstCmplThisCycle_Pass_TimeElapse (CM_DCDC_NV_Komponentenfehler_16_Cx2_TstCmplThisCycle_Pass_TimeElapse), 3=Cx3_TstComplThisOpCycle_FAIL (CM_DCDC_NV_Komponentenfehler_16_Cx3_TstComplThisOpCycle_FAIL)}, range raw 0..3, transfer-property=PENDING, to BMC_HV(timeout 5 s)  # Übertragung OBD relevanter Fehlerpfade vom Secondary zum Primary Steuergerät. Zuordnung der generischen Komponentenfehler muss zwischen Sender und Empfänger abgestimmt werden.
          signal DCDC_NV_Komponentenfehler_17_XIX_DCDC_NV_Komponentenfehler_01_XIX_HCP5_CANFD01: start 32, 2 bit, little-endian, data-type-policy=OVERRIDE, i-signal-type=PRIMITIVE, init-value=0, base-type=BT_DCDC_NV_Komponentenfehler_17, compu {0=Cx0_TstNotComplThisOpCycle_Init (CM_DCDC_NV_Komponentenfehler_17_Cx0_TstNotComplThisOpCycle_Init), 1=Cx1_TstComplThisOpCycle_Pass (CM_DCDC_NV_Komponentenfehler_17_Cx1_TstComplThisOpCycle_Pass), 2=Cx2_TstCmplThisCycle_Pass_TimeElapse (CM_DCDC_NV_Komponentenfehler_17_Cx2_TstCmplThisCycle_Pass_TimeElapse), 3=Cx3_TstComplThisOpCycle_FAIL (CM_DCDC_NV_Komponentenfehler_17_Cx3_TstComplThisOpCycle_FAIL)}, range raw 0..3, transfer-property=PENDING, to BMC_HV(timeout 5 s)  # Übertragung OBD relevanter Fehlerpfade vom Secondary zum Primary Steuergerät. Zuordnung der generischen Komponentenfehler muss zwischen Sender und Empfänger abgestimmt werden.
          signal DCDC_NV_Komponentenfehler_18_XIX_DCDC_NV_Komponentenfehler_01_XIX_HCP5_CANFD01: start 34, 2 bit, little-endian, data-type-policy=OVERRIDE, i-signal-type=PRIMITIVE, init-value=0, base-type=BT_DCDC_NV_Komponentenfehler_18, compu {0=Cx0_TstNotComplThisOpCycle_Init (CM_DCDC_NV_Komponentenfehler_18_Cx0_TstNotComplThisOpCycle_Init), 1=Cx1_TstComplThisOpCycle_Pass (CM_DCDC_NV_Komponentenfehler_18_Cx1_TstComplThisOpCycle_Pass), 2=Cx2_TstCmplThisCycle_Pass_TimeElapse (CM_DCDC_NV_Komponentenfehler_18_Cx2_TstCmplThisCycle_Pass_TimeElapse), 3=Cx3_TstComplThisOpCycle_FAIL (CM_DCDC_NV_Komponentenfehler_18_Cx3_TstComplThisOpCycle_FAIL)}, range raw 0..3, transfer-property=PENDING, to BMC_HV(timeout 5 s)  # Übertragung OBD relevanter Fehlerpfade vom Secondary zum Primary Steuergerät. Zuordnung der generischen Komponentenfehler muss zwischen Sender und Empfänger abgestimmt werden.
          signal DCDC_NV_Komponentenfehler_19_XIX_DCDC_NV_Komponentenfehler_01_XIX_HCP5_CANFD01: start 36, 2 bit, little-endian, data-type-policy=OVERRIDE, i-signal-type=PRIMITIVE, init-value=0, base-type=BT_DCDC_NV_Komponentenfehler_19, compu {0=Cx0_TstNotComplThisOpCycle_Init (CM_DCDC_NV_Komponentenfehler_19_Cx0_TstNotComplThisOpCycle_Init), 1=Cx1_TstComplThisOpCycle_Pass (CM_DCDC_NV_Komponentenfehler_19_Cx1_TstComplThisOpCycle_Pass), 2=Cx2_TstCmplThisCycle_Pass_TimeElapse (CM_DCDC_NV_Komponentenfehler_19_Cx2_TstCmplThisCycle_Pass_TimeElapse), 3=Cx3_TstComplThisOpCycle_FAIL (CM_DCDC_NV_Komponentenfehler_19_Cx3_TstComplThisOpCycle_FAIL)}, range raw 0..3, transfer-property=PENDING, to BMC_HV(timeout 5 s)  # Übertragung OBD relevanter Fehlerpfade vom Secondary zum Primary Steuergerät. Zuordnung der generischen Komponentenfehler muss zwischen Sender und Empfänger abgestimmt werden.
          signal DCDC_NV_Komponentenfehler_20_XIX_DCDC_NV_Komponentenfehler_01_XIX_HCP5_CANFD01: start 38, 2 bit, little-endian, data-type-policy=OVERRIDE, i-signal-type=PRIMITIVE, init-value=0, base-type=BT_DCDC_NV_Komponentenfehler_20, compu {0=Cx0_TstNotComplThisOpCycle_Init (CM_DCDC_NV_Komponentenfehler_20_Cx0_TstNotComplThisOpCycle_Init), 1=Cx1_TstComplThisOpCycle_Pass (CM_DCDC_NV_Komponentenfehler_20_Cx1_TstComplThisOpCycle_Pass), 2=Cx2_TstCmplThisCycle_Pass_TimeElapse (CM_DCDC_NV_Komponentenfehler_20_Cx2_TstCmplThisCycle_Pass_TimeElapse), 3=Cx3_TstComplThisOpCycle_FAIL (CM_DCDC_NV_Komponentenfehler_20_Cx3_TstComplThisOpCycle_FAIL)}, range raw 0..3, transfer-property=PENDING, to BMC_HV(timeout 5 s)  # Übertragung OBD relevanter Fehlerpfade vom Secondary zum Primary Steuergerät. Zuordnung der generischen Komponentenfehler muss zwischen Sender und Empfänger abgestimmt werden.
          signal DCDC_NV_Komponentenfehler_21_XIX_DCDC_NV_Komponentenfehler_01_XIX_HCP5_CANFD01: start 40, 2 bit, little-endian, data-type-policy=OVERRIDE, i-signal-type=PRIMITIVE, init-value=0, base-type=BT_DCDC_NV_Komponentenfehler_21, compu {0=Cx0_TstNotComplThisOpCycle_Init (CM_DCDC_NV_Komponentenfehler_21_Cx0_TstNotComplThisOpCycle_Init), 1=Cx1_TstComplThisOpCycle_Pass (CM_DCDC_NV_Komponentenfehler_21_Cx1_TstComplThisOpCycle_Pass), 2=Cx2_TstCmplThisCycle_Pass_TimeElapse (CM_DCDC_NV_Komponentenfehler_21_Cx2_TstCmplThisCycle_Pass_TimeElapse), 3=Cx3_TstComplThisOpCycle_FAIL (CM_DCDC_NV_Komponentenfehler_21_Cx3_TstComplThisOpCycle_FAIL)}, range raw 0..3, transfer-property=PENDING, to BMC_HV(timeout 5 s)  # Übertragung OBD relevanter Fehlerpfade vom Secondary zum Primary Steuergerät. Zuordnung der generischen Komponentenfehler muss zwischen Sender und Empfänger abgestimmt werden.
          signal DCDC_NV_Komponentenfehler_22_XIX_DCDC_NV_Komponentenfehler_01_XIX_HCP5_CANFD01: start 42, 2 bit, little-endian, data-type-policy=OVERRIDE, i-signal-type=PRIMITIVE, init-value=0, base-type=BT_DCDC_NV_Komponentenfehler_22, compu {0=Cx0_TstNotComplThisOpCycle_Init (CM_DCDC_NV_Komponentenfehler_22_Cx0_TstNotComplThisOpCycle_Init), 1=Cx1_TstComplThisOpCycle_Pass (CM_DCDC_NV_Komponentenfehler_22_Cx1_TstComplThisOpCycle_Pass), 2=Cx2_TstCmplThisCycle_Pass_TimeElapse (CM_DCDC_NV_Komponentenfehler_22_Cx2_TstCmplThisCycle_Pass_TimeElapse), 3=Cx3_TstComplThisOpCycle_FAIL (CM_DCDC_NV_Komponentenfehler_22_Cx3_TstComplThisOpCycle_FAIL)}, range raw 0..3, transfer-property=PENDING, to BMC_HV(timeout 5 s)  # Übertragung OBD relevanter Fehlerpfade vom Secondary zum Primary Steuergerät. Zuordnung der generischen Komponentenfehler muss zwischen Sender und Empfänger abgestimmt werden.
          signal DCDC_NV_Komponentenfehler_23_XIX_DCDC_NV_Komponentenfehler_01_XIX_HCP5_CANFD01: start 44, 2 bit, little-endian, data-type-policy=OVERRIDE, i-signal-type=PRIMITIVE, init-value=0, base-type=BT_DCDC_NV_Komponentenfehler_23, compu {0=Cx0_TstNotComplThisOpCycle_Init (CM_DCDC_NV_Komponentenfehler_23_Cx0_TstNotComplThisOpCycle_Init), 1=Cx1_TstComplThisOpCycle_Pass (CM_DCDC_NV_Komponentenfehler_23_Cx1_TstComplThisOpCycle_Pass), 2=Cx2_TstCmplThisCycle_Pass_TimeElapse (CM_DCDC_NV_Komponentenfehler_23_Cx2_TstCmplThisCycle_Pass_TimeElapse), 3=Cx3_TstComplThisOpCycle_FAIL (CM_DCDC_NV_Komponentenfehler_23_Cx3_TstComplThisOpCycle_FAIL)}, range raw 0..3, transfer-property=PENDING, to BMC_HV(timeout 5 s)  # Übertragung OBD relevanter Fehlerpfade vom Secondary zum Primary Steuergerät. Zuordnung der generischen Komponentenfehler muss zwischen Sender und Empfänger abgestimmt werden.
          signal DCDC_NV_Komponentenfehler_24_XIX_DCDC_NV_Komponentenfehler_01_XIX_HCP5_CANFD01: start 46, 2 bit, little-endian, data-type-policy=OVERRIDE, i-signal-type=PRIMITIVE, init-value=0, base-type=BT_DCDC_NV_Komponentenfehler_24, compu {0=Cx0_TstNotComplThisOpCycle_Init (CM_DCDC_NV_Komponentenfehler_24_Cx0_TstNotComplThisOpCycle_Init), 1=Cx1_TstComplThisOpCycle_Pass (CM_DCDC_NV_Komponentenfehler_24_Cx1_TstComplThisOpCycle_Pass), 2=Cx2_TstCmplThisCycle_Pass_TimeElapse (CM_DCDC_NV_Komponentenfehler_24_Cx2_TstCmplThisCycle_Pass_TimeElapse), 3=Cx3_TstComplThisOpCycle_FAIL (CM_DCDC_NV_Komponentenfehler_24_Cx3_TstComplThisOpCycle_FAIL)}, range raw 0..3, transfer-property=PENDING, to BMC_HV(timeout 5 s)  # Übertragung OBD relevanter Fehlerpfade vom Secondary zum Primary Steuergerät. Zuordnung der generischen Komponentenfehler muss zwischen Sender und Empfänger abgestimmt werden.
          signal DCDC_NV_Komponentenfehler_25_XIX_DCDC_NV_Komponentenfehler_01_XIX_HCP5_CANFD01: start 48, 2 bit, little-endian, data-type-policy=OVERRIDE, i-signal-type=PRIMITIVE, init-value=0, base-type=BT_DCDC_NV_Komponentenfehler_25, compu {0=Cx0_TstNotComplThisOpCycle_Init (CM_DCDC_NV_Komponentenfehler_25_Cx0_TstNotComplThisOpCycle_Init), 1=Cx1_TstComplThisOpCycle_Pass (CM_DCDC_NV_Komponentenfehler_25_Cx1_TstComplThisOpCycle_Pass), 2=Cx2_TstCmplThisCycle_Pass_TimeElapse (CM_DCDC_NV_Komponentenfehler_25_Cx2_TstCmplThisCycle_Pass_TimeElapse), 3=Cx3_TstComplThisOpCycle_FAIL (CM_DCDC_NV_Komponentenfehler_25_Cx3_TstComplThisOpCycle_FAIL)}, range raw 0..3, transfer-property=PENDING, to BMC_HV(timeout 5 s)  # Übertragung OBD relevanter Fehlerpfade vom Secondary zum Primary Steuergerät. Zuordnung der generischen Komponentenfehler muss zwischen Sender und Empfänger abgestimmt werden.
          signal DCDC_NV_Komponentenfehler_26_XIX_DCDC_NV_Komponentenfehler_01_XIX_HCP5_CANFD01: start 50, 2 bit, little-endian, data-type-policy=OVERRIDE, i-signal-type=PRIMITIVE, init-value=0, base-type=BT_DCDC_NV_Komponentenfehler_26, compu {0=Cx0_TstNotComplThisOpCycle_Init (CM_DCDC_NV_Komponentenfehler_26_Cx0_TstNotComplThisOpCycle_Init), 1=Cx1_TstComplThisOpCycle_Pass (CM_DCDC_NV_Komponentenfehler_26_Cx1_TstComplThisOpCycle_Pass), 2=Cx2_TstCmplThisCycle_Pass_TimeElapse (CM_DCDC_NV_Komponentenfehler_26_Cx2_TstCmplThisCycle_Pass_TimeElapse), 3=Cx3_TstComplThisOpCycle_FAIL (CM_DCDC_NV_Komponentenfehler_26_Cx3_TstComplThisOpCycle_FAIL)}, range raw 0..3, transfer-property=PENDING, to BMC_HV(timeout 5 s)  # Übertragung OBD relevanter Fehlerpfade vom Secondary zum Primary Steuergerät. Zuordnung der generischen Komponentenfehler muss zwischen Sender und Empfänger abgestimmt werden.
          signal DCDC_NV_Komponentenfehler_27_XIX_DCDC_NV_Komponentenfehler_01_XIX_HCP5_CANFD01: start 52, 2 bit, little-endian, data-type-policy=OVERRIDE, i-signal-type=PRIMITIVE, init-value=0, base-type=BT_DCDC_NV_Komponentenfehler_27, compu {0=Cx0_TstNotComplThisOpCycle_Init (CM_DCDC_NV_Komponentenfehler_27_Cx0_TstNotComplThisOpCycle_Init), 1=Cx1_TstComplThisOpCycle_Pass (CM_DCDC_NV_Komponentenfehler_27_Cx1_TstComplThisOpCycle_Pass), 2=Cx2_TstCmplThisCycle_Pass_TimeElapse (CM_DCDC_NV_Komponentenfehler_27_Cx2_TstCmplThisCycle_Pass_TimeElapse), 3=Cx3_TstComplThisOpCycle_FAIL (CM_DCDC_NV_Komponentenfehler_27_Cx3_TstComplThisOpCycle_FAIL)}, range raw 0..3, transfer-property=PENDING, to BMC_HV(timeout 5 s)  # Übertragung OBD relevanter Fehlerpfade vom Secondary zum Primary Steuergerät. Zuordnung der generischen Komponentenfehler muss zwischen Sender und Empfänger abgestimmt werden.
          signal DCDC_NV_Komponentenfehler_28_XIX_DCDC_NV_Komponentenfehler_01_XIX_HCP5_CANFD01: start 54, 2 bit, little-endian, data-type-policy=OVERRIDE, i-signal-type=PRIMITIVE, init-value=0, base-type=BT_DCDC_NV_Komponentenfehler_28, compu {0=Cx0_TstNotComplThisOpCycle_Init (CM_DCDC_NV_Komponentenfehler_28_Cx0_TstNotComplThisOpCycle_Init), 1=Cx1_TstComplThisOpCycle_Pass (CM_DCDC_NV_Komponentenfehler_28_Cx1_TstComplThisOpCycle_Pass), 2=Cx2_TstCmplThisCycle_Pass_TimeElapse (CM_DCDC_NV_Komponentenfehler_28_Cx2_TstCmplThisCycle_Pass_TimeElapse), 3=Cx3_TstComplThisOpCycle_FAIL (CM_DCDC_NV_Komponentenfehler_28_Cx3_TstComplThisOpCycle_FAIL)}, range raw 0..3, transfer-property=PENDING, to BMC_HV(timeout 5 s)  # Übertragung OBD relevanter Fehlerpfade vom Secondary zum Primary Steuergerät. Zuordnung der generischen Komponentenfehler muss zwischen Sender und Empfänger abgestimmt werden.
          signal DCDC_NV_Komponentenfehler_29_XIX_DCDC_NV_Komponentenfehler_01_XIX_HCP5_CANFD01: start 56, 2 bit, little-endian, data-type-policy=OVERRIDE, i-signal-type=PRIMITIVE, init-value=0, base-type=BT_DCDC_NV_Komponentenfehler_29, compu {0=Cx0_TstNotComplThisOpCycle_Init (CM_DCDC_NV_Komponentenfehler_29_Cx0_TstNotComplThisOpCycle_Init), 1=Cx1_TstComplThisOpCycle_Pass (CM_DCDC_NV_Komponentenfehler_29_Cx1_TstComplThisOpCycle_Pass), 2=Cx2_TstCmplThisCycle_Pass_TimeElapse (CM_DCDC_NV_Komponentenfehler_29_Cx2_TstCmplThisCycle_Pass_TimeElapse), 3=Cx3_TstComplThisOpCycle_FAIL (CM_DCDC_NV_Komponentenfehler_29_Cx3_TstComplThisOpCycle_FAIL)}, range raw 0..3, transfer-property=PENDING, to BMC_HV(timeout 5 s)  # Übertragung OBD relevanter Fehlerpfade vom Secondary zum Primary Steuergerät. Zuordnung der generischen Komponentenfehler muss zwischen Sender und Empfänger abgestimmt werden.
          signal DCDC_NV_Komponentenfehler_VLD_XIX_DCDC_NV_Komponentenfehler_01_XIX_HCP5_CANFD01: start 63, 1 bit, little-endian, data-type-policy=OVERRIDE, i-signal-type=PRIMITIVE, init-value=0, base-type=BT_DCDC_NV_Komponentenfehler_VLD, compu {0=Cx0_ungueltig (CM_DCDC_NV_Komponentenfehler_VLD_Cx0_ungueltig), 1=Cx1_gueltig (CM_DCDC_NV_Komponentenfehler_VLD_Cx1_gueltig)}, range raw 0..1, transfer-property=PENDING, to BMC_HV(timeout 5 s)  # Valid-Bit der OBD-Komponentenfehler. Das Bit wird beim Fehlerspeicher löschen zurückgenommen und erst wieder gesetzt, wenn der Fehlerspeicher vollständig gelöscht wurde. Der Primary-OBD-ECU soll damit mitgeteilt werden, ob sie den Inhalten der Komponentenfehler-Signalen vertrauen kann oder nicht.
      frame DCDC_NV_Komponentenfehler_02_XIX_HCP5_CANFD01: id 0x1A5556B1, to BMC_HV, frame-length=8, can-addressing-mode=EXTENDED, can-frame-rx-behavior=CAN-FD, can-frame-tx-behavior=CAN-FD
        pdu DCDC_NV_Komponentenfehler_02_XIX_HCP5_CANFD01: length=8, transmission-mode-true-timing=cyclic-timing={time-offset=0, time-period=0.5}, unused-bit-pattern=0
          signal DCDC_NV_Komponentenfehler_30_XIX_DCDC_NV_Komponentenfehler_02_XIX_HCP5_CANFD01: start 0, 2 bit, little-endian, data-type-policy=OVERRIDE, i-signal-type=PRIMITIVE, init-value=0, base-type=BT_DCDC_NV_Komponentenfehler_30, compu {0=Cx0_TstNotComplThisOpCycle_Init (CM_DCDC_NV_Komponentenfehler_30_Cx0_TstNotComplThisOpCycle_Init), 1=Cx1_TstComplThisOpCycle_Pass (CM_DCDC_NV_Komponentenfehler_30_Cx1_TstComplThisOpCycle_Pass), 2=Cx2_TstCmplThisCycle_Pass_TimeElapse (CM_DCDC_NV_Komponentenfehler_30_Cx2_TstCmplThisCycle_Pass_TimeElapse), 3=Cx3_TstComplThisOpCycle_FAIL (CM_DCDC_NV_Komponentenfehler_30_Cx3_TstComplThisOpCycle_FAIL)}, range raw 0..3, transfer-property=PENDING, to BMC_HV(timeout 5 s)  # Übertragung OBD relevanter Fehlerpfade vom Secondary zum Primary Steuergerät. Zuordnung der generischen Komponentenfehler muss zwischen Sender und Empfänger abgestimmt werden.
          signal DCDC_NV_Komponentenfehler_31_XIX_DCDC_NV_Komponentenfehler_02_XIX_HCP5_CANFD01: start 2, 2 bit, little-endian, data-type-policy=OVERRIDE, i-signal-type=PRIMITIVE, init-value=0, base-type=BT_DCDC_NV_Komponentenfehler_31, compu {0=Cx0_TstNotComplThisOpCycle_Init (CM_DCDC_NV_Komponentenfehler_31_Cx0_TstNotComplThisOpCycle_Init), 1=Cx1_TstComplThisOpCycle_Pass (CM_DCDC_NV_Komponentenfehler_31_Cx1_TstComplThisOpCycle_Pass), 2=Cx2_TstCmplThisCycle_Pass_TimeElapse (CM_DCDC_NV_Komponentenfehler_31_Cx2_TstCmplThisCycle_Pass_TimeElapse), 3=Cx3_TstComplThisOpCycle_FAIL (CM_DCDC_NV_Komponentenfehler_31_Cx3_TstComplThisOpCycle_FAIL)}, range raw 0..3, transfer-property=PENDING, to BMC_HV(timeout 5 s)  # Übertragung OBD relevanter Fehlerpfade vom Secondary zum Primary Steuergerät. Zuordnung der generischen Komponentenfehler muss zwischen Sender und Empfänger abgestimmt werden.
          signal DCDC_NV_Komponentenfehler_32_XIX_DCDC_NV_Komponentenfehler_02_XIX_HCP5_CANFD01: start 4, 2 bit, little-endian, data-type-policy=OVERRIDE, i-signal-type=PRIMITIVE, init-value=0, base-type=BT_DCDC_NV_Komponentenfehler_32, compu {0=Cx0_TstNotComplThisOpCycle_Init (CM_DCDC_NV_Komponentenfehler_32_Cx0_TstNotComplThisOpCycle_Init), 1=Cx1_TstComplThisOpCycle_Pass (CM_DCDC_NV_Komponentenfehler_32_Cx1_TstComplThisOpCycle_Pass), 2=Cx2_TstCmplThisCycle_Pass_TimeElapse (CM_DCDC_NV_Komponentenfehler_32_Cx2_TstCmplThisCycle_Pass_TimeElapse), 3=Cx3_TstComplThisOpCycle_FAIL (CM_DCDC_NV_Komponentenfehler_32_Cx3_TstComplThisOpCycle_FAIL)}, range raw 0..3, transfer-property=PENDING, to BMC_HV(timeout 5 s)  # Übertragung OBD relevanter Fehlerpfade vom Secondary zum Primary Steuergerät. Zuordnung der generischen Komponentenfehler muss zwischen Sender und Empfänger abgestimmt werden.
          signal DCDC_NV_Komponentenfehler_33_XIX_DCDC_NV_Komponentenfehler_02_XIX_HCP5_CANFD01: start 6, 2 bit, little-endian, data-type-policy=OVERRIDE, i-signal-type=PRIMITIVE, init-value=0, base-type=BT_DCDC_NV_Komponentenfehler_33, compu {0=Cx0_TstNotComplThisOpCycle_Init (CM_DCDC_NV_Komponentenfehler_33_Cx0_TstNotComplThisOpCycle_Init), 1=Cx1_TstComplThisOpCycle_Pass (CM_DCDC_NV_Komponentenfehler_33_Cx1_TstComplThisOpCycle_Pass), 2=Cx2_TstCmplThisCycle_Pass_TimeElapse (CM_DCDC_NV_Komponentenfehler_33_Cx2_TstCmplThisCycle_Pass_TimeElapse), 3=Cx3_TstComplThisOpCycle_FAIL (CM_DCDC_NV_Komponentenfehler_33_Cx3_TstComplThisOpCycle_FAIL)}, range raw 0..3, transfer-property=PENDING, to BMC_HV(timeout 5 s)  # Übertragung OBD relevanter Fehlerpfade vom Secondary zum Primary Steuergerät. Zuordnung der generischen Komponentenfehler muss zwischen Sender und Empfänger abgestimmt werden.
          signal DCDC_NV_Komponentenfehler_34_XIX_DCDC_NV_Komponentenfehler_02_XIX_HCP5_CANFD01: start 8, 2 bit, little-endian, data-type-policy=OVERRIDE, i-signal-type=PRIMITIVE, init-value=0, base-type=BT_DCDC_NV_Komponentenfehler_34, compu {0=Cx0_TstNotComplThisOpCycle_Init (CM_DCDC_NV_Komponentenfehler_34_Cx0_TstNotComplThisOpCycle_Init), 1=Cx1_TstComplThisOpCycle_Pass (CM_DCDC_NV_Komponentenfehler_34_Cx1_TstComplThisOpCycle_Pass), 2=Cx2_TstCmplThisCycle_Pass_TimeElapse (CM_DCDC_NV_Komponentenfehler_34_Cx2_TstCmplThisCycle_Pass_TimeElapse), 3=Cx3_TstComplThisOpCycle_FAIL (CM_DCDC_NV_Komponentenfehler_34_Cx3_TstComplThisOpCycle_FAIL)}, range raw 0..3, transfer-property=PENDING, to BMC_HV(timeout 5 s)  # Übertragung OBD relevanter Fehlerpfade vom Secondary zum Primary Steuergerät. Zuordnung der generischen Komponentenfehler muss zwischen Sender und Empfänger abgestimmt werden.
          signal DCDC_NV_Komponentenfehler_35_XIX_DCDC_NV_Komponentenfehler_02_XIX_HCP5_CANFD01: start 10, 2 bit, little-endian, data-type-policy=OVERRIDE, i-signal-type=PRIMITIVE, init-value=0, base-type=BT_DCDC_NV_Komponentenfehler_35, compu {0=Cx0_TstNotComplThisOpCycle_Init (CM_DCDC_NV_Komponentenfehler_35_Cx0_TstNotComplThisOpCycle_Init), 1=Cx1_TstComplThisOpCycle_Pass (CM_DCDC_NV_Komponentenfehler_35_Cx1_TstComplThisOpCycle_Pass), 2=Cx2_TstCmplThisCycle_Pass_TimeElapse (CM_DCDC_NV_Komponentenfehler_35_Cx2_TstCmplThisCycle_Pass_TimeElapse), 3=Cx3_TstComplThisOpCycle_FAIL (CM_DCDC_NV_Komponentenfehler_35_Cx3_TstComplThisOpCycle_FAIL)}, range raw 0..3, transfer-property=PENDING, to BMC_HV(timeout 5 s)  # Übertragung OBD relevanter Fehlerpfade vom Secondary zum Primary Steuergerät. Zuordnung der generischen Komponentenfehler muss zwischen Sender und Empfänger abgestimmt werden.
          signal DCDC_NV_Komponentenfehler_36_XIX_DCDC_NV_Komponentenfehler_02_XIX_HCP5_CANFD01: start 12, 2 bit, little-endian, data-type-policy=OVERRIDE, i-signal-type=PRIMITIVE, init-value=0, base-type=BT_DCDC_NV_Komponentenfehler_36, compu {0=Cx0_TstNotComplThisOpCycle_Init (CM_DCDC_NV_Komponentenfehler_36_Cx0_TstNotComplThisOpCycle_Init), 1=Cx1_TstComplThisOpCycle_Pass (CM_DCDC_NV_Komponentenfehler_36_Cx1_TstComplThisOpCycle_Pass), 2=Cx2_TstCmplThisCycle_Pass_TimeElapse (CM_DCDC_NV_Komponentenfehler_36_Cx2_TstCmplThisCycle_Pass_TimeElapse), 3=Cx3_TstComplThisOpCycle_FAIL (CM_DCDC_NV_Komponentenfehler_36_Cx3_TstComplThisOpCycle_FAIL)}, range raw 0..3, transfer-property=PENDING, to BMC_HV(timeout 5 s)  # Übertragung OBD relevanter Fehlerpfade vom Secondary zum Primary Steuergerät. Zuordnung der generischen Komponentenfehler muss zwischen Sender und Empfänger abgestimmt werden.
          signal DCDC_NV_Komponentenfehler_37_XIX_DCDC_NV_Komponentenfehler_02_XIX_HCP5_CANFD01: start 14, 2 bit, little-endian, data-type-policy=OVERRIDE, i-signal-type=PRIMITIVE, init-value=0, base-type=BT_DCDC_NV_Komponentenfehler_37, compu {0=Cx0_TstNotComplThisOpCycle_Init (CM_DCDC_NV_Komponentenfehler_37_Cx0_TstNotComplThisOpCycle_Init), 1=Cx1_TstComplThisOpCycle_Pass (CM_DCDC_NV_Komponentenfehler_37_Cx1_TstComplThisOpCycle_Pass), 2=Cx2_TstCmplThisCycle_Pass_TimeElapse (CM_DCDC_NV_Komponentenfehler_37_Cx2_TstCmplThisCycle_Pass_TimeElapse), 3=Cx3_TstComplThisOpCycle_FAIL (CM_DCDC_NV_Komponentenfehler_37_Cx3_TstComplThisOpCycle_FAIL)}, range raw 0..3, transfer-property=PENDING, to BMC_HV(timeout 5 s)  # Übertragung OBD relevanter Fehlerpfade vom Secondary zum Primary Steuergerät. Zuordnung der generischen Komponentenfehler muss zwischen Sender und Empfänger abgestimmt werden.
          signal DCDC_NV_Komponentenfehler_38_XIX_DCDC_NV_Komponentenfehler_02_XIX_HCP5_CANFD01: start 16, 2 bit, little-endian, data-type-policy=OVERRIDE, i-signal-type=PRIMITIVE, init-value=0, base-type=BT_DCDC_NV_Komponentenfehler_38, compu {0=Cx0_TstNotComplThisOpCycle_Init (CM_DCDC_NV_Komponentenfehler_38_Cx0_TstNotComplThisOpCycle_Init), 1=Cx1_TstComplThisOpCycle_Pass (CM_DCDC_NV_Komponentenfehler_38_Cx1_TstComplThisOpCycle_Pass), 2=Cx2_TstCmplThisCycle_Pass_TimeElapse (CM_DCDC_NV_Komponentenfehler_38_Cx2_TstCmplThisCycle_Pass_TimeElapse), 3=Cx3_TstComplThisOpCycle_FAIL (CM_DCDC_NV_Komponentenfehler_38_Cx3_TstComplThisOpCycle_FAIL)}, range raw 0..3, transfer-property=PENDING, to BMC_HV(timeout 5 s)  # Übertragung OBD relevanter Fehlerpfade vom Secondary zum Primary Steuergerät. Zuordnung der generischen Komponentenfehler muss zwischen Sender und Empfänger abgestimmt werden.
          signal DCDC_NV_Komponentenfehler_39_XIX_DCDC_NV_Komponentenfehler_02_XIX_HCP5_CANFD01: start 18, 2 bit, little-endian, data-type-policy=OVERRIDE, i-signal-type=PRIMITIVE, init-value=0, base-type=BT_DCDC_NV_Komponentenfehler_39, compu {0=Cx0_TstNotComplThisOpCycle_Init (CM_DCDC_NV_Komponentenfehler_39_Cx0_TstNotComplThisOpCycle_Init), 1=Cx1_TstComplThisOpCycle_Pass (CM_DCDC_NV_Komponentenfehler_39_Cx1_TstComplThisOpCycle_Pass), 2=Cx2_TstCmplThisCycle_Pass_TimeElapse (CM_DCDC_NV_Komponentenfehler_39_Cx2_TstCmplThisCycle_Pass_TimeElapse), 3=Cx3_TstComplThisOpCycle_FAIL (CM_DCDC_NV_Komponentenfehler_39_Cx3_TstComplThisOpCycle_FAIL)}, range raw 0..3, transfer-property=PENDING, to BMC_HV(timeout 5 s)  # Übertragung OBD relevanter Fehlerpfade vom Secondary zum Primary Steuergerät. Zuordnung der generischen Komponentenfehler muss zwischen Sender und Empfänger abgestimmt werden.
          signal DCDC_NV_Komponentenfehler_40_XIX_DCDC_NV_Komponentenfehler_02_XIX_HCP5_CANFD01: start 20, 2 bit, little-endian, data-type-policy=OVERRIDE, i-signal-type=PRIMITIVE, init-value=0, base-type=BT_DCDC_NV_Komponentenfehler_40, compu {0=Cx0_TstNotComplThisOpCycle_Init (CM_DCDC_NV_Komponentenfehler_40_Cx0_TstNotComplThisOpCycle_Init), 1=Cx1_TstComplThisOpCycle_Pass (CM_DCDC_NV_Komponentenfehler_40_Cx1_TstComplThisOpCycle_Pass), 2=Cx2_TstCmplThisCycle_Pass_TimeElapse (CM_DCDC_NV_Komponentenfehler_40_Cx2_TstCmplThisCycle_Pass_TimeElapse), 3=Cx3_TstComplThisOpCycle_FAIL (CM_DCDC_NV_Komponentenfehler_40_Cx3_TstComplThisOpCycle_FAIL)}, range raw 0..3, transfer-property=PENDING, to BMC_HV(timeout 5 s)  # Übertragung OBD relevanter Fehlerpfade vom Secondary zum Primary Steuergerät. Zuordnung der generischen Komponentenfehler muss zwischen Sender und Empfänger abgestimmt werden.
          signal DCDC_NV_Komponentenfehler_41_XIX_DCDC_NV_Komponentenfehler_02_XIX_HCP5_CANFD01: start 22, 2 bit, little-endian, data-type-policy=OVERRIDE, i-signal-type=PRIMITIVE, init-value=0, base-type=BT_DCDC_NV_Komponentenfehler_41, compu {0=Cx0_TstNotComplThisOpCycle_Init (CM_DCDC_NV_Komponentenfehler_41_Cx0_TstNotComplThisOpCycle_Init), 1=Cx1_TstComplThisOpCycle_Pass (CM_DCDC_NV_Komponentenfehler_41_Cx1_TstComplThisOpCycle_Pass), 2=Cx2_TstCmplThisCycle_Pass_TimeElapse (CM_DCDC_NV_Komponentenfehler_41_Cx2_TstCmplThisCycle_Pass_TimeElapse), 3=Cx3_TstComplThisOpCycle_FAIL (CM_DCDC_NV_Komponentenfehler_41_Cx3_TstComplThisOpCycle_FAIL)}, range raw 0..3, transfer-property=PENDING, to BMC_HV(timeout 5 s)  # Übertragung OBD relevanter Fehlerpfade vom Secondary zum Primary Steuergerät. Zuordnung der generischen Komponentenfehler muss zwischen Sender und Empfänger abgestimmt werden.
          signal DCDC_NV_Komponentenfehler_42_XIX_DCDC_NV_Komponentenfehler_02_XIX_HCP5_CANFD01: start 24, 2 bit, little-endian, data-type-policy=OVERRIDE, i-signal-type=PRIMITIVE, init-value=0, base-type=BT_DCDC_NV_Komponentenfehler_42, compu {0=Cx0_TstNotComplThisOpCycle_Init (CM_DCDC_NV_Komponentenfehler_42_Cx0_TstNotComplThisOpCycle_Init), 1=Cx1_TstComplThisOpCycle_Pass (CM_DCDC_NV_Komponentenfehler_42_Cx1_TstComplThisOpCycle_Pass), 2=Cx2_TstCmplThisCycle_Pass_TimeElapse (CM_DCDC_NV_Komponentenfehler_42_Cx2_TstCmplThisCycle_Pass_TimeElapse), 3=Cx3_TstComplThisOpCycle_FAIL (CM_DCDC_NV_Komponentenfehler_42_Cx3_TstComplThisOpCycle_FAIL)}, range raw 0..3, transfer-property=PENDING, to BMC_HV(timeout 5 s)  # Übertragung OBD relevanter Fehlerpfade vom Secondary zum Primary Steuergerät. Zuordnung der generischen Komponentenfehler muss zwischen Sender und Empfänger abgestimmt werden.
          signal DCDC_NV_Komponentenfehler_43_XIX_DCDC_NV_Komponentenfehler_02_XIX_HCP5_CANFD01: start 26, 2 bit, little-endian, data-type-policy=OVERRIDE, i-signal-type=PRIMITIVE, init-value=0, base-type=BT_DCDC_NV_Komponentenfehler_43, compu {0=Cx0_TstNotComplThisOpCycle_Init (CM_DCDC_NV_Komponentenfehler_43_Cx0_TstNotComplThisOpCycle_Init), 1=Cx1_TstComplThisOpCycle_Pass (CM_DCDC_NV_Komponentenfehler_43_Cx1_TstComplThisOpCycle_Pass), 2=Cx2_TstCmplThisCycle_Pass_TimeElapse (CM_DCDC_NV_Komponentenfehler_43_Cx2_TstCmplThisCycle_Pass_TimeElapse), 3=Cx3_TstComplThisOpCycle_FAIL (CM_DCDC_NV_Komponentenfehler_43_Cx3_TstComplThisOpCycle_FAIL)}, range raw 0..3, transfer-property=PENDING, to BMC_HV(timeout 5 s)  # Übertragung OBD relevanter Fehlerpfade vom Secondary zum Primary Steuergerät. Zuordnung der generischen Komponentenfehler muss zwischen Sender und Empfänger abgestimmt werden.
          signal DCDC_NV_Komponentenfehler_44_XIX_DCDC_NV_Komponentenfehler_02_XIX_HCP5_CANFD01: start 28, 2 bit, little-endian, data-type-policy=OVERRIDE, i-signal-type=PRIMITIVE, init-value=0, base-type=BT_DCDC_NV_Komponentenfehler_44, compu {0=Cx0_TstNotComplThisOpCycle_Init (CM_DCDC_NV_Komponentenfehler_44_Cx0_TstNotComplThisOpCycle_Init), 1=Cx1_TstComplThisOpCycle_Pass (CM_DCDC_NV_Komponentenfehler_44_Cx1_TstComplThisOpCycle_Pass), 2=Cx2_TstCmplThisCycle_Pass_TimeElapse (CM_DCDC_NV_Komponentenfehler_44_Cx2_TstCmplThisCycle_Pass_TimeElapse), 3=Cx3_TstComplThisOpCycle_FAIL (CM_DCDC_NV_Komponentenfehler_44_Cx3_TstComplThisOpCycle_FAIL)}, range raw 0..3, transfer-property=PENDING, to BMC_HV(timeout 5 s)  # Übertragung OBD relevanter Fehlerpfade vom Secondary zum Primary Steuergerät. Zuordnung der generischen Komponentenfehler muss zwischen Sender und Empfänger abgestimmt werden.
          signal DCDC_NV_Komponentenfehler_45_XIX_DCDC_NV_Komponentenfehler_02_XIX_HCP5_CANFD01: start 30, 2 bit, little-endian, data-type-policy=OVERRIDE, i-signal-type=PRIMITIVE, init-value=0, base-type=BT_DCDC_NV_Komponentenfehler_45, compu {0=Cx0_TstNotComplThisOpCycle_Init (CM_DCDC_NV_Komponentenfehler_45_Cx0_TstNotComplThisOpCycle_Init), 1=Cx1_TstComplThisOpCycle_Pass (CM_DCDC_NV_Komponentenfehler_45_Cx1_TstComplThisOpCycle_Pass), 2=Cx2_TstCmplThisCycle_Pass_TimeElapse (CM_DCDC_NV_Komponentenfehler_45_Cx2_TstCmplThisCycle_Pass_TimeElapse), 3=Cx3_TstComplThisOpCycle_FAIL (CM_DCDC_NV_Komponentenfehler_45_Cx3_TstComplThisOpCycle_FAIL)}, range raw 0..3, transfer-property=PENDING, to BMC_HV(timeout 5 s)  # Übertragung OBD relevanter Fehlerpfade vom Secondary zum Primary Steuergerät. Zuordnung der generischen Komponentenfehler muss zwischen Sender und Empfänger abgestimmt werden.
          signal DCDC_NV_Komponentenfehler_46_XIX_DCDC_NV_Komponentenfehler_02_XIX_HCP5_CANFD01: start 32, 2 bit, little-endian, data-type-policy=OVERRIDE, i-signal-type=PRIMITIVE, init-value=0, base-type=BT_DCDC_NV_Komponentenfehler_46, compu {0=Cx0_TstNotComplThisOpCycle_Init (CM_DCDC_NV_Komponentenfehler_46_Cx0_TstNotComplThisOpCycle_Init), 1=Cx1_TstComplThisOpCycle_Pass (CM_DCDC_NV_Komponentenfehler_46_Cx1_TstComplThisOpCycle_Pass), 2=Cx2_TstCmplThisCycle_Pass_TimeElapse (CM_DCDC_NV_Komponentenfehler_46_Cx2_TstCmplThisCycle_Pass_TimeElapse), 3=Cx3_TstComplThisOpCycle_FAIL (CM_DCDC_NV_Komponentenfehler_46_Cx3_TstComplThisOpCycle_FAIL)}, range raw 0..3, transfer-property=PENDING, to BMC_HV(timeout 5 s)  # Übertragung OBD relevanter Fehlerpfade vom Secondary zum Primary Steuergerät. Zuordnung der generischen Komponentenfehler muss zwischen Sender und Empfänger abgestimmt werden.
          signal DCDC_NV_Komponentenfehler_47_XIX_DCDC_NV_Komponentenfehler_02_XIX_HCP5_CANFD01: start 34, 2 bit, little-endian, data-type-policy=OVERRIDE, i-signal-type=PRIMITIVE, init-value=0, base-type=BT_DCDC_NV_Komponentenfehler_47, compu {0=Cx0_TstNotComplThisOpCycle_Init (CM_DCDC_NV_Komponentenfehler_47_Cx0_TstNotComplThisOpCycle_Init), 1=Cx1_TstComplThisOpCycle_Pass (CM_DCDC_NV_Komponentenfehler_47_Cx1_TstComplThisOpCycle_Pass), 2=Cx2_TstCmplThisCycle_Pass_TimeElapse (CM_DCDC_NV_Komponentenfehler_47_Cx2_TstCmplThisCycle_Pass_TimeElapse), 3=Cx3_TstComplThisOpCycle_FAIL (CM_DCDC_NV_Komponentenfehler_47_Cx3_TstComplThisOpCycle_FAIL)}, range raw 0..3, transfer-property=PENDING, to BMC_HV(timeout 5 s)  # Übertragung OBD relevanter Fehlerpfade vom Secondary zum Primary Steuergerät. Zuordnung der generischen Komponentenfehler muss zwischen Sender und Empfänger abgestimmt werden.
          signal DCDC_NV_Komponentenfehler_48_XIX_DCDC_NV_Komponentenfehler_02_XIX_HCP5_CANFD01: start 36, 2 bit, little-endian, data-type-policy=OVERRIDE, i-signal-type=PRIMITIVE, init-value=0, base-type=BT_DCDC_NV_Komponentenfehler_48, compu {0=Cx0_TstNotComplThisOpCycle_Init (CM_DCDC_NV_Komponentenfehler_48_Cx0_TstNotComplThisOpCycle_Init), 1=Cx1_TstComplThisOpCycle_Pass (CM_DCDC_NV_Komponentenfehler_48_Cx1_TstComplThisOpCycle_Pass), 2=Cx2_TstCmplThisCycle_Pass_TimeElapse (CM_DCDC_NV_Komponentenfehler_48_Cx2_TstCmplThisCycle_Pass_TimeElapse), 3=Cx3_TstComplThisOpCycle_FAIL (CM_DCDC_NV_Komponentenfehler_48_Cx3_TstComplThisOpCycle_FAIL)}, range raw 0..3, transfer-property=PENDING, to BMC_HV(timeout 5 s)  # Übertragung OBD relevanter Fehlerpfade vom Secondary zum Primary Steuergerät. Zuordnung der generischen Komponentenfehler muss zwischen Sender und Empfänger abgestimmt werden.
          signal DCDC_NV_Komponentenfehler_49_XIX_DCDC_NV_Komponentenfehler_02_XIX_HCP5_CANFD01: start 38, 2 bit, little-endian, data-type-policy=OVERRIDE, i-signal-type=PRIMITIVE, init-value=0, base-type=BT_DCDC_NV_Komponentenfehler_49, compu {0=Cx0_TstNotComplThisOpCycle_Init (CM_DCDC_NV_Komponentenfehler_49_Cx0_TstNotComplThisOpCycle_Init), 1=Cx1_TstComplThisOpCycle_Pass (CM_DCDC_NV_Komponentenfehler_49_Cx1_TstComplThisOpCycle_Pass), 2=Cx2_TstCmplThisCycle_Pass_TimeElapse (CM_DCDC_NV_Komponentenfehler_49_Cx2_TstCmplThisCycle_Pass_TimeElapse), 3=Cx3_TstComplThisOpCycle_FAIL (CM_DCDC_NV_Komponentenfehler_49_Cx3_TstComplThisOpCycle_FAIL)}, range raw 0..3, transfer-property=PENDING, to BMC_HV(timeout 5 s)  # Übertragung OBD relevanter Fehlerpfade vom Secondary zum Primary Steuergerät. Zuordnung der generischen Komponentenfehler muss zwischen Sender und Empfänger abgestimmt werden.
          signal DCDC_NV_Komponentenfehler_50_XIX_DCDC_NV_Komponentenfehler_02_XIX_HCP5_CANFD01: start 40, 2 bit, little-endian, data-type-policy=OVERRIDE, i-signal-type=PRIMITIVE, init-value=0, base-type=BT_DCDC_NV_Komponentenfehler_50, compu {0=Cx0_TstNotComplThisOpCycle_Init (CM_DCDC_NV_Komponentenfehler_50_Cx0_TstNotComplThisOpCycle_Init), 1=Cx1_TstComplThisOpCycle_Pass (CM_DCDC_NV_Komponentenfehler_50_Cx1_TstComplThisOpCycle_Pass), 2=Cx2_TstCmplThisCycle_Pass_TimeElapse (CM_DCDC_NV_Komponentenfehler_50_Cx2_TstCmplThisCycle_Pass_TimeElapse), 3=Cx3_TstComplThisOpCycle_FAIL (CM_DCDC_NV_Komponentenfehler_50_Cx3_TstComplThisOpCycle_FAIL)}, range raw 0..3, transfer-property=PENDING, to BMC_HV(timeout 5 s)  # Übertragung OBD relevanter Fehlerpfade vom Secondary zum Primary Steuergerät. Zuordnung der generischen Komponentenfehler muss zwischen Sender und Empfänger abgestimmt werden.
          signal DCDC_NV_Komponentenfehler_51_XIX_DCDC_NV_Komponentenfehler_02_XIX_HCP5_CANFD01: start 42, 2 bit, little-endian, data-type-policy=OVERRIDE, i-signal-type=PRIMITIVE, init-value=0, base-type=BT_DCDC_NV_Komponentenfehler_51, compu {0=Cx0_TstNotComplThisOpCycle_Init (CM_DCDC_NV_Komponentenfehler_51_Cx0_TstNotComplThisOpCycle_Init), 1=Cx1_TstComplThisOpCycle_Pass (CM_DCDC_NV_Komponentenfehler_51_Cx1_TstComplThisOpCycle_Pass), 2=Cx2_TstCmplThisCycle_Pass_TimeElapse (CM_DCDC_NV_Komponentenfehler_51_Cx2_TstCmplThisCycle_Pass_TimeElapse), 3=Cx3_TstComplThisOpCycle_FAIL (CM_DCDC_NV_Komponentenfehler_51_Cx3_TstComplThisOpCycle_FAIL)}, range raw 0..3, transfer-property=PENDING, to BMC_HV(timeout 5 s)  # Übertragung OBD relevanter Fehlerpfade vom Secondary zum Primary Steuergerät. Zuordnung der generischen Komponentenfehler muss zwischen Sender und Empfänger abgestimmt werden.
          signal DCDC_NV_Komponentenfehler_52_XIX_DCDC_NV_Komponentenfehler_02_XIX_HCP5_CANFD01: start 44, 2 bit, little-endian, data-type-policy=OVERRIDE, i-signal-type=PRIMITIVE, init-value=0, base-type=BT_DCDC_NV_Komponentenfehler_52, compu {0=Cx0_TstNotComplThisOpCycle_Init (CM_DCDC_NV_Komponentenfehler_52_Cx0_TstNotComplThisOpCycle_Init), 1=Cx1_TstComplThisOpCycle_Pass (CM_DCDC_NV_Komponentenfehler_52_Cx1_TstComplThisOpCycle_Pass), 2=Cx2_TstCmplThisCycle_Pass_TimeElapse (CM_DCDC_NV_Komponentenfehler_52_Cx2_TstCmplThisCycle_Pass_TimeElapse), 3=Cx3_TstComplThisOpCycle_FAIL (CM_DCDC_NV_Komponentenfehler_52_Cx3_TstComplThisOpCycle_FAIL)}, range raw 0..3, transfer-property=PENDING, to BMC_HV(timeout 5 s)  # Übertragung OBD relevanter Fehlerpfade vom Secondary zum Primary Steuergerät. Zuordnung der generischen Komponentenfehler muss zwischen Sender und Empfänger abgestimmt werden.
          signal DCDC_NV_Komponentenfehler_53_XIX_DCDC_NV_Komponentenfehler_02_XIX_HCP5_CANFD01: start 46, 2 bit, little-endian, data-type-policy=OVERRIDE, i-signal-type=PRIMITIVE, init-value=0, base-type=BT_DCDC_NV_Komponentenfehler_53, compu {0=Cx0_TstNotComplThisOpCycle_Init (CM_DCDC_NV_Komponentenfehler_53_Cx0_TstNotComplThisOpCycle_Init), 1=Cx1_TstComplThisOpCycle_Pass (CM_DCDC_NV_Komponentenfehler_53_Cx1_TstComplThisOpCycle_Pass), 2=Cx2_TstCmplThisCycle_Pass_TimeElapse (CM_DCDC_NV_Komponentenfehler_53_Cx2_TstCmplThisCycle_Pass_TimeElapse), 3=Cx3_TstComplThisOpCycle_FAIL (CM_DCDC_NV_Komponentenfehler_53_Cx3_TstComplThisOpCycle_FAIL)}, range raw 0..3, transfer-property=PENDING, to BMC_HV(timeout 5 s)  # Übertragung OBD relevanter Fehlerpfade vom Secondary zum Primary Steuergerät. Zuordnung der generischen Komponentenfehler muss zwischen Sender und Empfänger abgestimmt werden.
          signal DCDC_NV_Komponentenfehler_54_XIX_DCDC_NV_Komponentenfehler_02_XIX_HCP5_CANFD01: start 48, 2 bit, little-endian, data-type-policy=OVERRIDE, i-signal-type=PRIMITIVE, init-value=0, base-type=BT_DCDC_NV_Komponentenfehler_54, compu {0=Cx0_TstNotComplThisOpCycle_Init (CM_DCDC_NV_Komponentenfehler_54_Cx0_TstNotComplThisOpCycle_Init), 1=Cx1_TstComplThisOpCycle_Pass (CM_DCDC_NV_Komponentenfehler_54_Cx1_TstComplThisOpCycle_Pass), 2=Cx2_TstCmplThisCycle_Pass_TimeElapse (CM_DCDC_NV_Komponentenfehler_54_Cx2_TstCmplThisCycle_Pass_TimeElapse), 3=Cx3_TstComplThisOpCycle_FAIL (CM_DCDC_NV_Komponentenfehler_54_Cx3_TstComplThisOpCycle_FAIL)}, range raw 0..3, transfer-property=PENDING, to BMC_HV(timeout 5 s)  # Übertragung OBD relevanter Fehlerpfade vom Secondary zum Primary Steuergerät. Zuordnung der generischen Komponentenfehler muss zwischen Sender und Empfänger abgestimmt werden.
          signal DCDC_NV_Komponentenfehler_55_XIX_DCDC_NV_Komponentenfehler_02_XIX_HCP5_CANFD01: start 50, 2 bit, little-endian, data-type-policy=OVERRIDE, i-signal-type=PRIMITIVE, init-value=0, base-type=BT_DCDC_NV_Komponentenfehler_55, compu {0=Cx0_TstNotComplThisOpCycle_Init (CM_DCDC_NV_Komponentenfehler_55_Cx0_TstNotComplThisOpCycle_Init), 1=Cx1_TstComplThisOpCycle_Pass (CM_DCDC_NV_Komponentenfehler_55_Cx1_TstComplThisOpCycle_Pass), 2=Cx2_TstCmplThisCycle_Pass_TimeElapse (CM_DCDC_NV_Komponentenfehler_55_Cx2_TstCmplThisCycle_Pass_TimeElapse), 3=Cx3_TstComplThisOpCycle_FAIL (CM_DCDC_NV_Komponentenfehler_55_Cx3_TstComplThisOpCycle_FAIL)}, range raw 0..3, transfer-property=PENDING, to BMC_HV(timeout 5 s)  # Übertragung OBD relevanter Fehlerpfade vom Secondary zum Primary Steuergerät. Zuordnung der generischen Komponentenfehler muss zwischen Sender und Empfänger abgestimmt werden.
          signal DCDC_NV_Komponentenfehler_56_XIX_DCDC_NV_Komponentenfehler_02_XIX_HCP5_CANFD01: start 52, 2 bit, little-endian, data-type-policy=OVERRIDE, i-signal-type=PRIMITIVE, init-value=0, base-type=BT_DCDC_NV_Komponentenfehler_56, compu {0=Cx0_TstNotComplThisOpCycle_Init (CM_DCDC_NV_Komponentenfehler_56_Cx0_TstNotComplThisOpCycle_Init), 1=Cx1_TstComplThisOpCycle_Pass (CM_DCDC_NV_Komponentenfehler_56_Cx1_TstComplThisOpCycle_Pass), 2=Cx2_TstCmplThisCycle_Pass_TimeElapse (CM_DCDC_NV_Komponentenfehler_56_Cx2_TstCmplThisCycle_Pass_TimeElapse), 3=Cx3_TstComplThisOpCycle_FAIL (CM_DCDC_NV_Komponentenfehler_56_Cx3_TstComplThisOpCycle_FAIL)}, range raw 0..3, transfer-property=PENDING, to BMC_HV(timeout 5 s)  # Übertragung OBD relevanter Fehlerpfade vom Secondary zum Primary Steuergerät. Zuordnung der generischen Komponentenfehler muss zwischen Sender und Empfänger abgestimmt werden.
          signal DCDC_NV_Komponentenfehler_57_XIX_DCDC_NV_Komponentenfehler_02_XIX_HCP5_CANFD01: start 54, 2 bit, little-endian, data-type-policy=OVERRIDE, i-signal-type=PRIMITIVE, init-value=0, base-type=BT_DCDC_NV_Komponentenfehler_57, compu {0=Cx0_TstNotComplThisOpCycle_Init (CM_DCDC_NV_Komponentenfehler_57_Cx0_TstNotComplThisOpCycle_Init), 1=Cx1_TstComplThisOpCycle_Pass (CM_DCDC_NV_Komponentenfehler_57_Cx1_TstComplThisOpCycle_Pass), 2=Cx2_TstCmplThisCycle_Pass_TimeElapse (CM_DCDC_NV_Komponentenfehler_57_Cx2_TstCmplThisCycle_Pass_TimeElapse), 3=Cx3_TstComplThisOpCycle_FAIL (CM_DCDC_NV_Komponentenfehler_57_Cx3_TstComplThisOpCycle_FAIL)}, range raw 0..3, transfer-property=PENDING, to BMC_HV(timeout 5 s)  # Übertragung OBD relevanter Fehlerpfade vom Secondary zum Primary Steuergerät. Zuordnung der generischen Komponentenfehler muss zwischen Sender und Empfänger abgestimmt werden.
          signal DCDC_NV_Komponentenfehler_58_XIX_DCDC_NV_Komponentenfehler_02_XIX_HCP5_CANFD01: start 56, 2 bit, little-endian, data-type-policy=OVERRIDE, i-signal-type=PRIMITIVE, init-value=0, base-type=BT_DCDC_NV_Komponentenfehler_58, compu {0=Cx0_TstNotComplThisOpCycle_Init (CM_DCDC_NV_Komponentenfehler_58_Cx0_TstNotComplThisOpCycle_Init), 1=Cx1_TstComplThisOpCycle_Pass (CM_DCDC_NV_Komponentenfehler_58_Cx1_TstComplThisOpCycle_Pass), 2=Cx2_TstCmplThisCycle_Pass_TimeElapse (CM_DCDC_NV_Komponentenfehler_58_Cx2_TstCmplThisCycle_Pass_TimeElapse), 3=Cx3_TstComplThisOpCycle_FAIL (CM_DCDC_NV_Komponentenfehler_58_Cx3_TstComplThisOpCycle_FAIL)}, range raw 0..3, transfer-property=PENDING, to BMC_HV(timeout 5 s)  # Übertragung OBD relevanter Fehlerpfade vom Secondary zum Primary Steuergerät. Zuordnung der generischen Komponentenfehler muss zwischen Sender und Empfänger abgestimmt werden.
          signal DCDC_NV_Komponentenfehler_59_XIX_DCDC_NV_Komponentenfehler_02_XIX_HCP5_CANFD01: start 58, 2 bit, little-endian, data-type-policy=OVERRIDE, i-signal-type=PRIMITIVE, init-value=0, base-type=BT_DCDC_NV_Komponentenfehler_59, compu {0=Cx0_TstNotComplThisOpCycle_Init (CM_DCDC_NV_Komponentenfehler_59_Cx0_TstNotComplThisOpCycle_Init), 1=Cx1_TstComplThisOpCycle_Pass (CM_DCDC_NV_Komponentenfehler_59_Cx1_TstComplThisOpCycle_Pass), 2=Cx2_TstCmplThisCycle_Pass_TimeElapse (CM_DCDC_NV_Komponentenfehler_59_Cx2_TstCmplThisCycle_Pass_TimeElapse), 3=Cx3_TstComplThisOpCycle_FAIL (CM_DCDC_NV_Komponentenfehler_59_Cx3_TstComplThisOpCycle_FAIL)}, range raw 0..3, transfer-property=PENDING, to BMC_HV(timeout 5 s)  # Übertragung OBD relevanter Fehlerpfade vom Secondary zum Primary Steuergerät. Zuordnung der generischen Komponentenfehler muss zwischen Sender und Empfänger abgestimmt werden.
          signal DCDC_NV_Komponentenfehler_60_XIX_DCDC_NV_Komponentenfehler_02_XIX_HCP5_CANFD01: start 60, 2 bit, little-endian, data-type-policy=OVERRIDE, i-signal-type=PRIMITIVE, init-value=0, base-type=BT_DCDC_NV_Komponentenfehler_60, compu {0=Cx0_TstNotComplThisOpCycle_Init (CM_DCDC_NV_Komponentenfehler_60_Cx0_TstNotComplThisOpCycle_Init), 1=Cx1_TstComplThisOpCycle_Pass (CM_DCDC_NV_Komponentenfehler_60_Cx1_TstComplThisOpCycle_Pass), 2=Cx2_TstCmplThisCycle_Pass_TimeElapse (CM_DCDC_NV_Komponentenfehler_60_Cx2_TstCmplThisCycle_Pass_TimeElapse), 3=Cx3_TstComplThisOpCycle_FAIL (CM_DCDC_NV_Komponentenfehler_60_Cx3_TstComplThisOpCycle_FAIL)}, range raw 0..3, transfer-property=PENDING, to BMC_HV(timeout 5 s)  # Übertragung OBD relevanter Fehlerpfade vom Secondary zum Primary Steuergerät. Zuordnung der generischen Komponentenfehler muss zwischen Sender und Empfänger abgestimmt werden.
      frame DCDC_NV_Komponentenfehler_03_XIX_HCP5_CANFD01: id 0x1A5556B2, to BMC_HV, frame-length=8, can-addressing-mode=EXTENDED, can-frame-rx-behavior=CAN-FD, can-frame-tx-behavior=CAN-FD
        pdu DCDC_NV_Komponentenfehler_03_XIX_HCP5_CANFD01: length=8, transmission-mode-true-timing=cyclic-timing={time-offset=0, time-period=0.5}, unused-bit-pattern=0
          signal DCDC_NV_Komponentenfehler_61_XIX_DCDC_NV_Komponentenfehler_03_XIX_HCP5_CANFD01: start 0, 2 bit, little-endian, data-type-policy=OVERRIDE, i-signal-type=PRIMITIVE, init-value=0, base-type=BT_DCDC_NV_Komponentenfehler_61, compu {0=Cx0_TstNotComplThisOpCycle_Init (CM_DCDC_NV_Komponentenfehler_61_Cx0_TstNotComplThisOpCycle_Init), 1=Cx1_TstComplThisOpCycle_Pass (CM_DCDC_NV_Komponentenfehler_61_Cx1_TstComplThisOpCycle_Pass), 2=Cx2_TstCmplThisCycle_Pass_TimeElapse (CM_DCDC_NV_Komponentenfehler_61_Cx2_TstCmplThisCycle_Pass_TimeElapse), 3=Cx3_TstComplThisOpCycle_FAIL (CM_DCDC_NV_Komponentenfehler_61_Cx3_TstComplThisOpCycle_FAIL)}, range raw 0..3, transfer-property=PENDING, to BMC_HV(timeout 5 s)  # Übertragung OBD relevanter Fehlerpfade vom Secondary zum Primary Steuergerät. Zuordnung der generischen Komponentenfehler muss zwischen Sender und Empfänger abgestimmt werden.
          signal DCDC_NV_Komponentenfehler_62_XIX_DCDC_NV_Komponentenfehler_03_XIX_HCP5_CANFD01: start 2, 2 bit, little-endian, data-type-policy=OVERRIDE, i-signal-type=PRIMITIVE, init-value=0, base-type=BT_DCDC_NV_Komponentenfehler_62, compu {0=Cx0_TstNotComplThisOpCycle_Init (CM_DCDC_NV_Komponentenfehler_62_Cx0_TstNotComplThisOpCycle_Init), 1=Cx1_TstComplThisOpCycle_Pass (CM_DCDC_NV_Komponentenfehler_62_Cx1_TstComplThisOpCycle_Pass), 2=Cx2_TstCmplThisCycle_Pass_TimeElapse (CM_DCDC_NV_Komponentenfehler_62_Cx2_TstCmplThisCycle_Pass_TimeElapse), 3=Cx3_TstComplThisOpCycle_FAIL (CM_DCDC_NV_Komponentenfehler_62_Cx3_TstComplThisOpCycle_FAIL)}, range raw 0..3, transfer-property=PENDING, to BMC_HV(timeout 5 s)  # Übertragung OBD relevanter Fehlerpfade vom Secondary zum Primary Steuergerät. Zuordnung der generischen Komponentenfehler muss zwischen Sender und Empfänger abgestimmt werden.
          signal DCDC_NV_Komponentenfehler_63_XIX_DCDC_NV_Komponentenfehler_03_XIX_HCP5_CANFD01: start 4, 2 bit, little-endian, data-type-policy=OVERRIDE, i-signal-type=PRIMITIVE, init-value=0, base-type=BT_DCDC_NV_Komponentenfehler_63, compu {0=Cx0_TstNotComplThisOpCycle_Init (CM_DCDC_NV_Komponentenfehler_63_Cx0_TstNotComplThisOpCycle_Init), 1=Cx1_TstComplThisOpCycle_Pass (CM_DCDC_NV_Komponentenfehler_63_Cx1_TstComplThisOpCycle_Pass), 2=Cx2_TstCmplThisCycle_Pass_TimeElapse (CM_DCDC_NV_Komponentenfehler_63_Cx2_TstCmplThisCycle_Pass_TimeElapse), 3=Cx3_TstComplThisOpCycle_FAIL (CM_DCDC_NV_Komponentenfehler_63_Cx3_TstComplThisOpCycle_FAIL)}, range raw 0..3, transfer-property=PENDING, to BMC_HV(timeout 5 s)  # Übertragung OBD relevanter Fehlerpfade vom Secondary zum Primary Steuergerät. Zuordnung der generischen Komponentenfehler muss zwischen Sender und Empfänger abgestimmt werden.
          signal DCDC_NV_Komponentenfehler_64_XIX_DCDC_NV_Komponentenfehler_03_XIX_HCP5_CANFD01: start 6, 2 bit, little-endian, data-type-policy=OVERRIDE, i-signal-type=PRIMITIVE, init-value=0, base-type=BT_DCDC_NV_Komponentenfehler_64, compu {0=Cx0_TstNotComplThisOpCycle_Init (CM_DCDC_NV_Komponentenfehler_64_Cx0_TstNotComplThisOpCycle_Init), 1=Cx1_TstComplThisOpCycle_Pass (CM_DCDC_NV_Komponentenfehler_64_Cx1_TstComplThisOpCycle_Pass), 2=Cx2_TstCmplThisCycle_Pass_TimeElapse (CM_DCDC_NV_Komponentenfehler_64_Cx2_TstCmplThisCycle_Pass_TimeElapse), 3=Cx3_TstComplThisOpCycle_FAIL (CM_DCDC_NV_Komponentenfehler_64_Cx3_TstComplThisOpCycle_FAIL)}, range raw 0..3, transfer-property=PENDING, to BMC_HV(timeout 5 s)  # Übertragung OBD relevanter Fehlerpfade vom Secondary zum Primary Steuergerät. Zuordnung der generischen Komponentenfehler muss zwischen Sender und Empfänger abgestimmt werden.
          signal DCDC_NV_Komponentenfehler_65_XIX_DCDC_NV_Komponentenfehler_03_XIX_HCP5_CANFD01: start 8, 2 bit, little-endian, data-type-policy=OVERRIDE, i-signal-type=PRIMITIVE, init-value=0, base-type=BT_DCDC_NV_Komponentenfehler_65, compu {0=Cx0_TstNotComplThisOpCycle_Init (CM_DCDC_NV_Komponentenfehler_65_Cx0_TstNotComplThisOpCycle_Init), 1=Cx1_TstComplThisOpCycle_Pass (CM_DCDC_NV_Komponentenfehler_65_Cx1_TstComplThisOpCycle_Pass), 2=Cx2_TstCmplThisCycle_Pass_TimeElapse (CM_DCDC_NV_Komponentenfehler_65_Cx2_TstCmplThisCycle_Pass_TimeElapse), 3=Cx3_TstComplThisOpCycle_FAIL (CM_DCDC_NV_Komponentenfehler_65_Cx3_TstComplThisOpCycle_FAIL)}, range raw 0..3, transfer-property=PENDING, to BMC_HV(timeout 5 s)  # Übertragung OBD relevanter Fehlerpfade vom Secondary zum Primary Steuergerät. Zuordnung der generischen Komponentenfehler muss zwischen Sender und Empfänger abgestimmt werden.
          signal DCDC_NV_Komponentenfehler_66_XIX_DCDC_NV_Komponentenfehler_03_XIX_HCP5_CANFD01: start 10, 2 bit, little-endian, data-type-policy=OVERRIDE, i-signal-type=PRIMITIVE, init-value=0, base-type=BT_DCDC_NV_Komponentenfehler_66, compu {0=Cx0_TstNotComplThisOpCycle_Init (CM_DCDC_NV_Komponentenfehler_66_Cx0_TstNotComplThisOpCycle_Init), 1=Cx1_TstComplThisOpCycle_Pass (CM_DCDC_NV_Komponentenfehler_66_Cx1_TstComplThisOpCycle_Pass), 2=Cx2_TstCmplThisCycle_Pass_TimeElapse (CM_DCDC_NV_Komponentenfehler_66_Cx2_TstCmplThisCycle_Pass_TimeElapse), 3=Cx3_TstComplThisOpCycle_FAIL (CM_DCDC_NV_Komponentenfehler_66_Cx3_TstComplThisOpCycle_FAIL)}, range raw 0..3, transfer-property=PENDING, to BMC_HV(timeout 5 s)  # Übertragung OBD relevanter Fehlerpfade vom Secondary zum Primary Steuergerät. Zuordnung der generischen Komponentenfehler muss zwischen Sender und Empfänger abgestimmt werden.
          signal DCDC_NV_Komponentenfehler_67_XIX_DCDC_NV_Komponentenfehler_03_XIX_HCP5_CANFD01: start 12, 2 bit, little-endian, data-type-policy=OVERRIDE, i-signal-type=PRIMITIVE, init-value=0, base-type=BT_DCDC_NV_Komponentenfehler_67, compu {0=Cx0_TstNotComplThisOpCycle_Init (CM_DCDC_NV_Komponentenfehler_67_Cx0_TstNotComplThisOpCycle_Init), 1=Cx1_TstComplThisOpCycle_Pass (CM_DCDC_NV_Komponentenfehler_67_Cx1_TstComplThisOpCycle_Pass), 2=Cx2_TstCmplThisCycle_Pass_TimeElapse (CM_DCDC_NV_Komponentenfehler_67_Cx2_TstCmplThisCycle_Pass_TimeElapse), 3=Cx3_TstComplThisOpCycle_FAIL (CM_DCDC_NV_Komponentenfehler_67_Cx3_TstComplThisOpCycle_FAIL)}, range raw 0..3, transfer-property=PENDING, to BMC_HV(timeout 5 s)  # Übertragung OBD relevanter Fehlerpfade vom Secondary zum Primary Steuergerät. Zuordnung der generischen Komponentenfehler muss zwischen Sender und Empfänger abgestimmt werden.
          signal DCDC_NV_Komponentenfehler_68_XIX_DCDC_NV_Komponentenfehler_03_XIX_HCP5_CANFD01: start 14, 2 bit, little-endian, data-type-policy=OVERRIDE, i-signal-type=PRIMITIVE, init-value=0, base-type=BT_DCDC_NV_Komponentenfehler_68, compu {0=Cx0_TstNotComplThisOpCycle_Init (CM_DCDC_NV_Komponentenfehler_68_Cx0_TstNotComplThisOpCycle_Init), 1=Cx1_TstComplThisOpCycle_Pass (CM_DCDC_NV_Komponentenfehler_68_Cx1_TstComplThisOpCycle_Pass), 2=Cx2_TstCmplThisCycle_Pass_TimeElapse (CM_DCDC_NV_Komponentenfehler_68_Cx2_TstCmplThisCycle_Pass_TimeElapse), 3=Cx3_TstComplThisOpCycle_FAIL (CM_DCDC_NV_Komponentenfehler_68_Cx3_TstComplThisOpCycle_FAIL)}, range raw 0..3, transfer-property=PENDING, to BMC_HV(timeout 5 s)  # Übertragung OBD relevanter Fehlerpfade vom Secondary zum Primary Steuergerät. Zuordnung der generischen Komponentenfehler muss zwischen Sender und Empfänger abgestimmt werden.
          signal DCDC_NV_Komponentenfehler_69_XIX_DCDC_NV_Komponentenfehler_03_XIX_HCP5_CANFD01: start 16, 2 bit, little-endian, data-type-policy=OVERRIDE, i-signal-type=PRIMITIVE, init-value=0, base-type=BT_DCDC_NV_Komponentenfehler_69, compu {0=Cx0_TstNotComplThisOpCycle_Init (CM_DCDC_NV_Komponentenfehler_69_Cx0_TstNotComplThisOpCycle_Init), 1=Cx1_TstComplThisOpCycle_Pass (CM_DCDC_NV_Komponentenfehler_69_Cx1_TstComplThisOpCycle_Pass), 2=Cx2_TstCmplThisCycle_Pass_TimeElapse (CM_DCDC_NV_Komponentenfehler_69_Cx2_TstCmplThisCycle_Pass_TimeElapse), 3=Cx3_TstComplThisOpCycle_FAIL (CM_DCDC_NV_Komponentenfehler_69_Cx3_TstComplThisOpCycle_FAIL)}, range raw 0..3, transfer-property=PENDING, to BMC_HV(timeout 5 s)  # Übertragung OBD relevanter Fehlerpfade vom Secondary zum Primary Steuergerät. Zuordnung der generischen Komponentenfehler muss zwischen Sender und Empfänger abgestimmt werden.
          signal DCDC_NV_Komponentenfehler_70_XIX_DCDC_NV_Komponentenfehler_03_XIX_HCP5_CANFD01: start 18, 2 bit, little-endian, data-type-policy=OVERRIDE, i-signal-type=PRIMITIVE, init-value=0, base-type=BT_DCDC_NV_Komponentenfehler_70, compu {0=Cx0_TstNotComplThisOpCycle_Init (CM_DCDC_NV_Komponentenfehler_70_Cx0_TstNotComplThisOpCycle_Init), 1=Cx1_TstComplThisOpCycle_Pass (CM_DCDC_NV_Komponentenfehler_70_Cx1_TstComplThisOpCycle_Pass), 2=Cx2_TstCmplThisCycle_Pass_TimeElapse (CM_DCDC_NV_Komponentenfehler_70_Cx2_TstCmplThisCycle_Pass_TimeElapse), 3=Cx3_TstComplThisOpCycle_FAIL (CM_DCDC_NV_Komponentenfehler_70_Cx3_TstComplThisOpCycle_FAIL)}, range raw 0..3, transfer-property=PENDING, to BMC_HV(timeout 5 s)  # Übertragung OBD relevanter Fehlerpfade vom Secondary zum Primary Steuergerät. Zuordnung der generischen Komponentenfehler muss zwischen Sender und Empfänger abgestimmt werden.
          signal DCDC_NV_Komponentenfehler_71_XIX_DCDC_NV_Komponentenfehler_03_XIX_HCP5_CANFD01: start 20, 2 bit, little-endian, data-type-policy=OVERRIDE, i-signal-type=PRIMITIVE, init-value=0, base-type=BT_DCDC_NV_Komponentenfehler_71, compu {0=Cx0_TstNotComplThisOpCycle_Init (CM_DCDC_NV_Komponentenfehler_71_Cx0_TstNotComplThisOpCycle_Init), 1=Cx1_TstComplThisOpCycle_Pass (CM_DCDC_NV_Komponentenfehler_71_Cx1_TstComplThisOpCycle_Pass), 2=Cx2_TstCmplThisCycle_Pass_TimeElapse (CM_DCDC_NV_Komponentenfehler_71_Cx2_TstCmplThisCycle_Pass_TimeElapse), 3=Cx3_TstComplThisOpCycle_FAIL (CM_DCDC_NV_Komponentenfehler_71_Cx3_TstComplThisOpCycle_FAIL)}, range raw 0..3, transfer-property=PENDING, to BMC_HV(timeout 5 s)  # Übertragung OBD relevanter Fehlerpfade vom Secondary zum Primary Steuergerät. Zuordnung der generischen Komponentenfehler muss zwischen Sender und Empfänger abgestimmt werden.
          signal DCDC_NV_Komponentenfehler_72_XIX_DCDC_NV_Komponentenfehler_03_XIX_HCP5_CANFD01: start 22, 2 bit, little-endian, data-type-policy=OVERRIDE, i-signal-type=PRIMITIVE, init-value=0, base-type=BT_DCDC_NV_Komponentenfehler_72, compu {0=Cx0_TstNotComplThisOpCycle_Init (CM_DCDC_NV_Komponentenfehler_72_Cx0_TstNotComplThisOpCycle_Init), 1=Cx1_TstComplThisOpCycle_Pass (CM_DCDC_NV_Komponentenfehler_72_Cx1_TstComplThisOpCycle_Pass), 2=Cx2_TstCmplThisCycle_Pass_TimeElapse (CM_DCDC_NV_Komponentenfehler_72_Cx2_TstCmplThisCycle_Pass_TimeElapse), 3=Cx3_TstComplThisOpCycle_FAIL (CM_DCDC_NV_Komponentenfehler_72_Cx3_TstComplThisOpCycle_FAIL)}, range raw 0..3, transfer-property=PENDING, to BMC_HV(timeout 5 s)  # Übertragung OBD relevanter Fehlerpfade vom Secondary zum Primary Steuergerät. Zuordnung der generischen Komponentenfehler muss zwischen Sender und Empfänger abgestimmt werden.
          signal DCDC_NV_Komponentenfehler_73_XIX_DCDC_NV_Komponentenfehler_03_XIX_HCP5_CANFD01: start 24, 2 bit, little-endian, data-type-policy=OVERRIDE, i-signal-type=PRIMITIVE, init-value=0, base-type=BT_DCDC_NV_Komponentenfehler_73, compu {0=Cx0_TstNotComplThisOpCycle_Init (CM_DCDC_NV_Komponentenfehler_73_Cx0_TstNotComplThisOpCycle_Init), 1=Cx1_TstComplThisOpCycle_Pass (CM_DCDC_NV_Komponentenfehler_73_Cx1_TstComplThisOpCycle_Pass), 2=Cx2_TstCmplThisCycle_Pass_TimeElapse (CM_DCDC_NV_Komponentenfehler_73_Cx2_TstCmplThisCycle_Pass_TimeElapse), 3=Cx3_TstComplThisOpCycle_FAIL (CM_DCDC_NV_Komponentenfehler_73_Cx3_TstComplThisOpCycle_FAIL)}, range raw 0..3, transfer-property=PENDING, to BMC_HV(timeout 5 s)  # Übertragung OBD relevanter Fehlerpfade vom Secondary zum Primary Steuergerät. Zuordnung der generischen Komponentenfehler muss zwischen Sender und Empfänger abgestimmt werden.
          signal DCDC_NV_Komponentenfehler_74_XIX_DCDC_NV_Komponentenfehler_03_XIX_HCP5_CANFD01: start 26, 2 bit, little-endian, data-type-policy=OVERRIDE, i-signal-type=PRIMITIVE, init-value=0, base-type=BT_DCDC_NV_Komponentenfehler_74, compu {0=Cx0_TstNotComplThisOpCycle_Init (CM_DCDC_NV_Komponentenfehler_74_Cx0_TstNotComplThisOpCycle_Init), 1=Cx1_TstComplThisOpCycle_Pass (CM_DCDC_NV_Komponentenfehler_74_Cx1_TstComplThisOpCycle_Pass), 2=Cx2_TstCmplThisCycle_Pass_TimeElapse (CM_DCDC_NV_Komponentenfehler_74_Cx2_TstCmplThisCycle_Pass_TimeElapse), 3=Cx3_TstComplThisOpCycle_FAIL (CM_DCDC_NV_Komponentenfehler_74_Cx3_TstComplThisOpCycle_FAIL)}, range raw 0..3, transfer-property=PENDING, to BMC_HV(timeout 5 s)  # Übertragung OBD relevanter Fehlerpfade vom Secondary zum Primary Steuergerät. Zuordnung der generischen Komponentenfehler muss zwischen Sender und Empfänger abgestimmt werden.
          signal DCDC_NV_Komponentenfehler_75_XIX_DCDC_NV_Komponentenfehler_03_XIX_HCP5_CANFD01: start 28, 2 bit, little-endian, data-type-policy=OVERRIDE, i-signal-type=PRIMITIVE, init-value=0, base-type=BT_DCDC_NV_Komponentenfehler_75, compu {0=Cx0_TstNotComplThisOpCycle_Init (CM_DCDC_NV_Komponentenfehler_75_Cx0_TstNotComplThisOpCycle_Init), 1=Cx1_TstComplThisOpCycle_Pass (CM_DCDC_NV_Komponentenfehler_75_Cx1_TstComplThisOpCycle_Pass), 2=Cx2_TstCmplThisCycle_Pass_TimeElapse (CM_DCDC_NV_Komponentenfehler_75_Cx2_TstCmplThisCycle_Pass_TimeElapse), 3=Cx3_TstComplThisOpCycle_FAIL (CM_DCDC_NV_Komponentenfehler_75_Cx3_TstComplThisOpCycle_FAIL)}, range raw 0..3, transfer-property=PENDING, to BMC_HV(timeout 5 s)  # Übertragung OBD relevanter Fehlerpfade vom Secondary zum Primary Steuergerät. Zuordnung der generischen Komponentenfehler muss zwischen Sender und Empfänger abgestimmt werden.
          signal DCDC_NV_Komponentenfehler_76_XIX_DCDC_NV_Komponentenfehler_03_XIX_HCP5_CANFD01: start 30, 2 bit, little-endian, data-type-policy=OVERRIDE, i-signal-type=PRIMITIVE, init-value=0, base-type=BT_DCDC_NV_Komponentenfehler_76, compu {0=Cx0_TstNotComplThisOpCycle_Init (CM_DCDC_NV_Komponentenfehler_76_Cx0_TstNotComplThisOpCycle_Init), 1=Cx1_TstComplThisOpCycle_Pass (CM_DCDC_NV_Komponentenfehler_76_Cx1_TstComplThisOpCycle_Pass), 2=Cx2_TstCmplThisCycle_Pass_TimeElapse (CM_DCDC_NV_Komponentenfehler_76_Cx2_TstCmplThisCycle_Pass_TimeElapse), 3=Cx3_TstComplThisOpCycle_FAIL (CM_DCDC_NV_Komponentenfehler_76_Cx3_TstComplThisOpCycle_FAIL)}, range raw 0..3, transfer-property=PENDING, to BMC_HV(timeout 5 s)  # Übertragung OBD relevanter Fehlerpfade vom Secondary zum Primary Steuergerät. Zuordnung der generischen Komponentenfehler muss zwischen Sender und Empfänger abgestimmt werden.
          signal DCDC_NV_Komponentenfehler_77_XIX_DCDC_NV_Komponentenfehler_03_XIX_HCP5_CANFD01: start 32, 2 bit, little-endian, data-type-policy=OVERRIDE, i-signal-type=PRIMITIVE, init-value=0, base-type=BT_DCDC_NV_Komponentenfehler_77, compu {0=Cx0_TstNotComplThisOpCycle_Init (CM_DCDC_NV_Komponentenfehler_77_Cx0_TstNotComplThisOpCycle_Init), 1=Cx1_TstComplThisOpCycle_Pass (CM_DCDC_NV_Komponentenfehler_77_Cx1_TstComplThisOpCycle_Pass), 2=Cx2_TstCmplThisCycle_Pass_TimeElapse (CM_DCDC_NV_Komponentenfehler_77_Cx2_TstCmplThisCycle_Pass_TimeElapse), 3=Cx3_TstComplThisOpCycle_FAIL (CM_DCDC_NV_Komponentenfehler_77_Cx3_TstComplThisOpCycle_FAIL)}, range raw 0..3, transfer-property=PENDING, to BMC_HV(timeout 5 s)  # Übertragung OBD relevanter Fehlerpfade vom Secondary zum Primary Steuergerät. Zuordnung der generischen Komponentenfehler muss zwischen Sender und Empfänger abgestimmt werden.
          signal DCDC_NV_Komponentenfehler_78_XIX_DCDC_NV_Komponentenfehler_03_XIX_HCP5_CANFD01: start 34, 2 bit, little-endian, data-type-policy=OVERRIDE, i-signal-type=PRIMITIVE, init-value=0, base-type=BT_DCDC_NV_Komponentenfehler_78, compu {0=Cx0_TstNotComplThisOpCycle_Init (CM_DCDC_NV_Komponentenfehler_78_Cx0_TstNotComplThisOpCycle_Init), 1=Cx1_TstComplThisOpCycle_Pass (CM_DCDC_NV_Komponentenfehler_78_Cx1_TstComplThisOpCycle_Pass), 2=Cx2_TstCmplThisCycle_Pass_TimeElapse (CM_DCDC_NV_Komponentenfehler_78_Cx2_TstCmplThisCycle_Pass_TimeElapse), 3=Cx3_TstComplThisOpCycle_FAIL (CM_DCDC_NV_Komponentenfehler_78_Cx3_TstComplThisOpCycle_FAIL)}, range raw 0..3, transfer-property=PENDING, to BMC_HV(timeout 5 s)  # Übertragung OBD relevanter Fehlerpfade vom Secondary zum Primary Steuergerät. Zuordnung der generischen Komponentenfehler muss zwischen Sender und Empfänger abgestimmt werden.
          signal DCDC_NV_Komponentenfehler_79_XIX_DCDC_NV_Komponentenfehler_03_XIX_HCP5_CANFD01: start 36, 2 bit, little-endian, data-type-policy=OVERRIDE, i-signal-type=PRIMITIVE, init-value=0, base-type=BT_DCDC_NV_Komponentenfehler_79, compu {0=Cx0_TstNotComplThisOpCycle_Init (CM_DCDC_NV_Komponentenfehler_79_Cx0_TstNotComplThisOpCycle_Init), 1=Cx1_TstComplThisOpCycle_Pass (CM_DCDC_NV_Komponentenfehler_79_Cx1_TstComplThisOpCycle_Pass), 2=Cx2_TstCmplThisCycle_Pass_TimeElapse (CM_DCDC_NV_Komponentenfehler_79_Cx2_TstCmplThisCycle_Pass_TimeElapse), 3=Cx3_TstComplThisOpCycle_FAIL (CM_DCDC_NV_Komponentenfehler_79_Cx3_TstComplThisOpCycle_FAIL)}, range raw 0..3, transfer-property=PENDING, to BMC_HV(timeout 5 s)  # Übertragung OBD relevanter Fehlerpfade vom Secondary zum Primary Steuergerät. Zuordnung der generischen Komponentenfehler muss zwischen Sender und Empfänger abgestimmt werden.
          signal DCDC_NV_Komponentenfehler_80_XIX_DCDC_NV_Komponentenfehler_03_XIX_HCP5_CANFD01: start 38, 2 bit, little-endian, data-type-policy=OVERRIDE, i-signal-type=PRIMITIVE, init-value=0, base-type=BT_DCDC_NV_Komponentenfehler_80, compu {0=Cx0_TstNotComplThisOpCycle_Init (CM_DCDC_NV_Komponentenfehler_80_Cx0_TstNotComplThisOpCycle_Init), 1=Cx1_TstComplThisOpCycle_Pass (CM_DCDC_NV_Komponentenfehler_80_Cx1_TstComplThisOpCycle_Pass), 2=Cx2_TstCmplThisCycle_Pass_TimeElapse (CM_DCDC_NV_Komponentenfehler_80_Cx2_TstCmplThisCycle_Pass_TimeElapse), 3=Cx3_TstComplThisOpCycle_FAIL (CM_DCDC_NV_Komponentenfehler_80_Cx3_TstComplThisOpCycle_FAIL)}, range raw 0..3, transfer-property=PENDING, to BMC_HV(timeout 5 s)  # Übertragung OBD relevanter Fehlerpfade vom Secondary zum Primary Steuergerät. Zuordnung der generischen Komponentenfehler muss zwischen Sender und Empfänger abgestimmt werden.
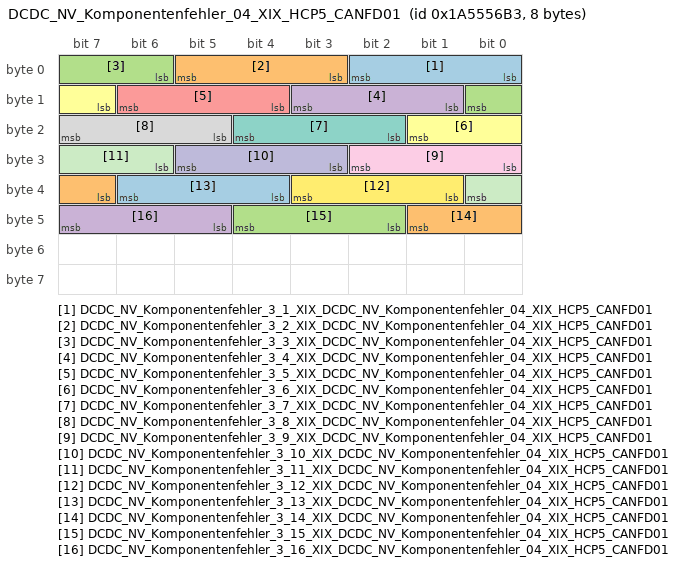
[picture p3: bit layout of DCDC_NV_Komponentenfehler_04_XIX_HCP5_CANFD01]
      frame DCDC_NV_Komponentenfehler_04_XIX_HCP5_CANFD01: id 0x1A5556B3, to BMC_HV, frame-length=8, can-addressing-mode=EXTENDED, can-frame-rx-behavior=CAN-FD, can-frame-tx-behavior=CAN-FD
        pdu DCDC_NV_Komponentenfehler_04_XIX_HCP5_CANFD01: length=8, transmission-mode-true-timing=cyclic-timing={time-offset=0, time-period=0.5}, unused-bit-pattern=0
          signal DCDC_NV_Komponentenfehler_3_1_XIX_DCDC_NV_Komponentenfehler_04_XIX_HCP5_CANFD01: start 0, 3 bit, little-endian, data-type-policy=OVERRIDE, i-signal-type=PRIMITIVE, init-value=0, base-type=BT_DCDC_NV_Komponentenfehler_3_1, compu {0=Cx0_TNCTOC (CM_DCDC_NV_Komponentenfehler_3_1_Cx0_TNCTOC), 1=Cx1_TP_TC (CM_DCDC_NV_Komponentenfehler_3_1_Cx1_TP_TC), 2=Cx2_TP_TC_WCMTL (CM_DCDC_NV_Komponentenfehler_3_1_Cx2_TP_TC_WCMTL), 3=Cx3_TF_TC_Error_1 (CM_DCDC_NV_Komponentenfehler_3_1_Cx3_TF_TC_Error_1), 4=Cx4_TF_TC_Error_2 (CM_DCDC_NV_Komponentenfehler_3_1_Cx4_TF_TC_Error_2), 5=Cx5_TF_TC_Error_3 (CM_DCDC_NV_Komponentenfehler_3_1_Cx5_TF_TC_Error_3), 6=Cx6_TF_TC_Error_4 (CM_DCDC_NV_Komponentenfehler_3_1_Cx6_TF_TC_Error_4), 7=Cx7_TF_TC_Error_5 (CM_DCDC_NV_Komponentenfehler_3_1_Cx7_TF_TC_Error_5)}, range raw 0..7, transfer-property=PENDING, to BMC_HV(timeout 5 s)  # Übertragung OBD relevanter Fehlerpfade vom Secondary zum Primary Steuergerät. Zuordnung der generischen Komponentenfehler muss zwischen Sender und Empfänger abgestimmt werden.
          signal DCDC_NV_Komponentenfehler_3_2_XIX_DCDC_NV_Komponentenfehler_04_XIX_HCP5_CANFD01: start 3, 3 bit, little-endian, data-type-policy=OVERRIDE, i-signal-type=PRIMITIVE, init-value=0, base-type=BT_DCDC_NV_Komponentenfehler_3_2, compu {0=Cx0_TNCTOC (CM_DCDC_NV_Komponentenfehler_3_2_Cx0_TNCTOC), 1=Cx1_TP_TC (CM_DCDC_NV_Komponentenfehler_3_2_Cx1_TP_TC), 2=Cx2_TP_TC_WCMTL (CM_DCDC_NV_Komponentenfehler_3_2_Cx2_TP_TC_WCMTL), 3=Cx3_TF_TC_Error_1 (CM_DCDC_NV_Komponentenfehler_3_2_Cx3_TF_TC_Error_1), 4=Cx4_TF_TC_Error_2 (CM_DCDC_NV_Komponentenfehler_3_2_Cx4_TF_TC_Error_2), 5=Cx5_TF_TC_Error_3 (CM_DCDC_NV_Komponentenfehler_3_2_Cx5_TF_TC_Error_3), 6=Cx6_TF_TC_Error_4 (CM_DCDC_NV_Komponentenfehler_3_2_Cx6_TF_TC_Error_4), 7=Cx7_TF_TC_Error_5 (CM_DCDC_NV_Komponentenfehler_3_2_Cx7_TF_TC_Error_5)}, range raw 0..7, transfer-property=PENDING, to BMC_HV(timeout 5 s)  # Übertragung OBD relevanter Fehlerpfade vom Secondary zum Primary Steuergerät. Zuordnung der generischen Komponentenfehler muss zwischen Sender und Empfänger abgestimmt werden.
          signal DCDC_NV_Komponentenfehler_3_3_XIX_DCDC_NV_Komponentenfehler_04_XIX_HCP5_CANFD01: start 6, 3 bit, little-endian, data-type-policy=OVERRIDE, i-signal-type=PRIMITIVE, init-value=0, base-type=BT_DCDC_NV_Komponentenfehler_3_3, compu {0=Cx0_TNCTOC (CM_DCDC_NV_Komponentenfehler_3_3_Cx0_TNCTOC), 1=Cx1_TP_TC (CM_DCDC_NV_Komponentenfehler_3_3_Cx1_TP_TC), 2=Cx2_TP_TC_WCMTL (CM_DCDC_NV_Komponentenfehler_3_3_Cx2_TP_TC_WCMTL), 3=Cx3_TF_TC_Error_1 (CM_DCDC_NV_Komponentenfehler_3_3_Cx3_TF_TC_Error_1), 4=Cx4_TF_TC_Error_2 (CM_DCDC_NV_Komponentenfehler_3_3_Cx4_TF_TC_Error_2), 5=Cx5_TF_TC_Error_3 (CM_DCDC_NV_Komponentenfehler_3_3_Cx5_TF_TC_Error_3), 6=Cx6_TF_TC_Error_4 (CM_DCDC_NV_Komponentenfehler_3_3_Cx6_TF_TC_Error_4), 7=Cx7_TF_TC_Error_5 (CM_DCDC_NV_Komponentenfehler_3_3_Cx7_TF_TC_Error_5)}, range raw 0..7, transfer-property=PENDING, to BMC_HV(timeout 5 s)  # Übertragung OBD relevanter Fehlerpfade vom Secondary zum Primary Steuergerät. Zuordnung der generischen Komponentenfehler muss zwischen Sender und Empfänger abgestimmt werden.
          signal DCDC_NV_Komponentenfehler_3_4_XIX_DCDC_NV_Komponentenfehler_04_XIX_HCP5_CANFD01: start 9, 3 bit, little-endian, data-type-policy=OVERRIDE, i-signal-type=PRIMITIVE, init-value=0, base-type=BT_DCDC_NV_Komponentenfehler_3_4, compu {0=Cx0_TNCTOC (CM_DCDC_NV_Komponentenfehler_3_4_Cx0_TNCTOC), 1=Cx1_TP_TC (CM_DCDC_NV_Komponentenfehler_3_4_Cx1_TP_TC), 2=Cx2_TP_TC_WCMTL (CM_DCDC_NV_Komponentenfehler_3_4_Cx2_TP_TC_WCMTL), 3=Cx3_TF_TC_Error_1 (CM_DCDC_NV_Komponentenfehler_3_4_Cx3_TF_TC_Error_1), 4=Cx4_TF_TC_Error_2 (CM_DCDC_NV_Komponentenfehler_3_4_Cx4_TF_TC_Error_2), 5=Cx5_TF_TC_Error_3 (CM_DCDC_NV_Komponentenfehler_3_4_Cx5_TF_TC_Error_3), 6=Cx6_TF_TC_Error_4 (CM_DCDC_NV_Komponentenfehler_3_4_Cx6_TF_TC_Error_4), 7=Cx7_TF_TC_Error_5 (CM_DCDC_NV_Komponentenfehler_3_4_Cx7_TF_TC_Error_5)}, range raw 0..7, transfer-property=PENDING, to BMC_HV(timeout 5 s)  # Übertragung OBD relevanter Fehlerpfade vom Secondary zum Primary Steuergerät. Zuordnung der generischen Komponentenfehler muss zwischen Sender und Empfänger abgestimmt werden.
          signal DCDC_NV_Komponentenfehler_3_5_XIX_DCDC_NV_Komponentenfehler_04_XIX_HCP5_CANFD01: start 12, 3 bit, little-endian, data-type-policy=OVERRIDE, i-signal-type=PRIMITIVE, init-value=0, base-type=BT_DCDC_NV_Komponentenfehler_3_5, compu {0=Cx0_TNCTOC (CM_DCDC_NV_Komponentenfehler_3_5_Cx0_TNCTOC), 1=Cx1_TP_TC (CM_DCDC_NV_Komponentenfehler_3_5_Cx1_TP_TC), 2=Cx2_TP_TC_WCMTL (CM_DCDC_NV_Komponentenfehler_3_5_Cx2_TP_TC_WCMTL), 3=Cx3_TF_TC_Error_1 (CM_DCDC_NV_Komponentenfehler_3_5_Cx3_TF_TC_Error_1), 4=Cx4_TF_TC_Error_2 (CM_DCDC_NV_Komponentenfehler_3_5_Cx4_TF_TC_Error_2), 5=Cx5_TF_TC_Error_3 (CM_DCDC_NV_Komponentenfehler_3_5_Cx5_TF_TC_Error_3), 6=Cx6_TF_TC_Error_4 (CM_DCDC_NV_Komponentenfehler_3_5_Cx6_TF_TC_Error_4), 7=Cx7_TF_TC_Error_5 (CM_DCDC_NV_Komponentenfehler_3_5_Cx7_TF_TC_Error_5)}, range raw 0..7, transfer-property=PENDING, to BMC_HV(timeout 5 s)  # Übertragung OBD relevanter Fehlerpfade vom Secondary zum Primary Steuergerät. Zuordnung der generischen Komponentenfehler muss zwischen Sender und Empfänger abgestimmt werden.
          signal DCDC_NV_Komponentenfehler_3_6_XIX_DCDC_NV_Komponentenfehler_04_XIX_HCP5_CANFD01: start 15, 3 bit, little-endian, data-type-policy=OVERRIDE, i-signal-type=PRIMITIVE, init-value=0, base-type=BT_DCDC_NV_Komponentenfehler_3_6, compu {0=Cx0_TNCTOC (CM_DCDC_NV_Komponentenfehler_3_6_Cx0_TNCTOC), 1=Cx1_TP_TC (CM_DCDC_NV_Komponentenfehler_3_6_Cx1_TP_TC), 2=Cx2_TP_TC_WCMTL (CM_DCDC_NV_Komponentenfehler_3_6_Cx2_TP_TC_WCMTL), 3=Cx3_TF_TC_Error_1 (CM_DCDC_NV_Komponentenfehler_3_6_Cx3_TF_TC_Error_1), 4=Cx4_TF_TC_Error_2 (CM_DCDC_NV_Komponentenfehler_3_6_Cx4_TF_TC_Error_2), 5=Cx5_TF_TC_Error_3 (CM_DCDC_NV_Komponentenfehler_3_6_Cx5_TF_TC_Error_3), 6=Cx6_TF_TC_Error_4 (CM_DCDC_NV_Komponentenfehler_3_6_Cx6_TF_TC_Error_4), 7=Cx7_TF_TC_Error_5 (CM_DCDC_NV_Komponentenfehler_3_6_Cx7_TF_TC_Error_5)}, range raw 0..7, transfer-property=PENDING, to BMC_HV(timeout 5 s)  # Übertragung OBD relevanter Fehlerpfade vom Secondary zum Primary Steuergerät. Zuordnung der generischen Komponentenfehler muss zwischen Sender und Empfänger abgestimmt werden.
          signal DCDC_NV_Komponentenfehler_3_7_XIX_DCDC_NV_Komponentenfehler_04_XIX_HCP5_CANFD01: start 18, 3 bit, little-endian, data-type-policy=OVERRIDE, i-signal-type=PRIMITIVE, init-value=0, base-type=BT_DCDC_NV_Komponentenfehler_3_7, compu {0=Cx0_TNCTOC (CM_DCDC_NV_Komponentenfehler_3_7_Cx0_TNCTOC), 1=Cx1_TP_TC (CM_DCDC_NV_Komponentenfehler_3_7_Cx1_TP_TC), 2=Cx2_TP_TC_WCMTL (CM_DCDC_NV_Komponentenfehler_3_7_Cx2_TP_TC_WCMTL), 3=Cx3_TF_TC_Error_1 (CM_DCDC_NV_Komponentenfehler_3_7_Cx3_TF_TC_Error_1), 4=Cx4_TF_TC_Error_2 (CM_DCDC_NV_Komponentenfehler_3_7_Cx4_TF_TC_Error_2), 5=Cx5_TF_TC_Error_3 (CM_DCDC_NV_Komponentenfehler_3_7_Cx5_TF_TC_Error_3), 6=Cx6_TF_TC_Error_4 (CM_DCDC_NV_Komponentenfehler_3_7_Cx6_TF_TC_Error_4), 7=Cx7_TF_TC_Error_5 (CM_DCDC_NV_Komponentenfehler_3_7_Cx7_TF_TC_Error_5)}, range raw 0..7, transfer-property=PENDING, to BMC_HV(timeout 5 s)  # Übertragung OBD relevanter Fehlerpfade vom Secondary zum Primary Steuergerät. Zuordnung der generischen Komponentenfehler muss zwischen Sender und Empfänger abgestimmt werden.
          signal DCDC_NV_Komponentenfehler_3_8_XIX_DCDC_NV_Komponentenfehler_04_XIX_HCP5_CANFD01: start 21, 3 bit, little-endian, data-type-policy=OVERRIDE, i-signal-type=PRIMITIVE, init-value=0, base-type=BT_DCDC_NV_Komponentenfehler_3_8, compu {0=Cx0_TNCTOC (CM_DCDC_NV_Komponentenfehler_3_8_Cx0_TNCTOC), 1=Cx1_TP_TC (CM_DCDC_NV_Komponentenfehler_3_8_Cx1_TP_TC), 2=Cx2_TP_TC_WCMTL (CM_DCDC_NV_Komponentenfehler_3_8_Cx2_TP_TC_WCMTL), 3=Cx3_TF_TC_Error_1 (CM_DCDC_NV_Komponentenfehler_3_8_Cx3_TF_TC_Error_1), 4=Cx4_TF_TC_Error_2 (CM_DCDC_NV_Komponentenfehler_3_8_Cx4_TF_TC_Error_2), 5=Cx5_TF_TC_Error_3 (CM_DCDC_NV_Komponentenfehler_3_8_Cx5_TF_TC_Error_3), 6=Cx6_TF_TC_Error_4 (CM_DCDC_NV_Komponentenfehler_3_8_Cx6_TF_TC_Error_4), 7=Cx7_TF_TC_Error_5 (CM_DCDC_NV_Komponentenfehler_3_8_Cx7_TF_TC_Error_5)}, range raw 0..7, transfer-property=PENDING, to BMC_HV(timeout 5 s)  # Übertragung OBD relevanter Fehlerpfade vom Secondary zum Primary Steuergerät. Zuordnung der generischen Komponentenfehler muss zwischen Sender und Empfänger abgestimmt werden.
          signal DCDC_NV_Komponentenfehler_3_9_XIX_DCDC_NV_Komponentenfehler_04_XIX_HCP5_CANFD01: start 24, 3 bit, little-endian, data-type-policy=OVERRIDE, i-signal-type=PRIMITIVE, init-value=0, base-type=BT_DCDC_NV_Komponentenfehler_3_9, compu {0=Cx0_TNCTOC (CM_DCDC_NV_Komponentenfehler_3_9_Cx0_TNCTOC), 1=Cx1_TP_TC (CM_DCDC_NV_Komponentenfehler_3_9_Cx1_TP_TC), 2=Cx2_TP_TC_WCMTL (CM_DCDC_NV_Komponentenfehler_3_9_Cx2_TP_TC_WCMTL), 3=Cx3_TF_TC_Error_1 (CM_DCDC_NV_Komponentenfehler_3_9_Cx3_TF_TC_Error_1), 4=Cx4_TF_TC_Error_2 (CM_DCDC_NV_Komponentenfehler_3_9_Cx4_TF_TC_Error_2), 5=Cx5_TF_TC_Error_3 (CM_DCDC_NV_Komponentenfehler_3_9_Cx5_TF_TC_Error_3), 6=Cx6_TF_TC_Error_4 (CM_DCDC_NV_Komponentenfehler_3_9_Cx6_TF_TC_Error_4), 7=Cx7_TF_TC_Error_5 (CM_DCDC_NV_Komponentenfehler_3_9_Cx7_TF_TC_Error_5)}, range raw 0..7, transfer-property=PENDING, to BMC_HV(timeout 5 s)  # Übertragung OBD relevanter Fehlerpfade vom Secondary zum Primary Steuergerät. Zuordnung der generischen Komponentenfehler muss zwischen Sender und Empfänger abgestimmt werden.
          signal DCDC_NV_Komponentenfehler_3_10_XIX_DCDC_NV_Komponentenfehler_04_XIX_HCP5_CANFD01: start 27, 3 bit, little-endian, data-type-policy=OVERRIDE, i-signal-type=PRIMITIVE, init-value=0, base-type=BT_DCDC_NV_Komponentenfehler_3_10, compu {0=Cx0_TNCTOC (CM_DCDC_NV_Komponentenfehler_3_10_Cx0_TNCTOC), 1=Cx1_TP_TC (CM_DCDC_NV_Komponentenfehler_3_10_Cx1_TP_TC), 2=Cx2_TP_TC_WCMTL (CM_DCDC_NV_Komponentenfehler_3_10_Cx2_TP_TC_WCMTL), 3=Cx3_TF_TC_Error_1 (CM_DCDC_NV_Komponentenfehler_3_10_Cx3_TF_TC_Error_1), 4=Cx4_TF_TC_Error_2 (CM_DCDC_NV_Komponentenfehler_3_10_Cx4_TF_TC_Error_2), 5=Cx5_TF_TC_Error_3 (CM_DCDC_NV_Komponentenfehler_3_10_Cx5_TF_TC_Error_3), 6=Cx6_TF_TC_Error_4 (CM_DCDC_NV_Komponentenfehler_3_10_Cx6_TF_TC_Error_4), 7=Cx7_TF_TC_Error_5 (CM_DCDC_NV_Komponentenfehler_3_10_Cx7_TF_TC_Error_5)}, range raw 0..7, transfer-property=PENDING, to BMC_HV(timeout 5 s)  # Übertragung OBD relevanter Fehlerpfade vom Secondary zum Primary Steuergerät. Zuordnung der generischen Komponentenfehler muss zwischen Sender und Empfänger abgestimmt werden.
          signal DCDC_NV_Komponentenfehler_3_11_XIX_DCDC_NV_Komponentenfehler_04_XIX_HCP5_CANFD01: start 30, 3 bit, little-endian, data-type-policy=OVERRIDE, i-signal-type=PRIMITIVE, init-value=0, base-type=BT_DCDC_NV_Komponentenfehler_3_11, compu {0=Cx0_TNCTOC (CM_DCDC_NV_Komponentenfehler_3_11_Cx0_TNCTOC), 1=Cx1_TP_TC (CM_DCDC_NV_Komponentenfehler_3_11_Cx1_TP_TC), 2=Cx2_TP_TC_WCMTL (CM_DCDC_NV_Komponentenfehler_3_11_Cx2_TP_TC_WCMTL), 3=Cx3_TF_TC_Error_1 (CM_DCDC_NV_Komponentenfehler_3_11_Cx3_TF_TC_Error_1), 4=Cx4_TF_TC_Error_2 (CM_DCDC_NV_Komponentenfehler_3_11_Cx4_TF_TC_Error_2), 5=Cx5_TF_TC_Error_3 (CM_DCDC_NV_Komponentenfehler_3_11_Cx5_TF_TC_Error_3), 6=Cx6_TF_TC_Error_4 (CM_DCDC_NV_Komponentenfehler_3_11_Cx6_TF_TC_Error_4), 7=Cx7_TF_TC_Error_5 (CM_DCDC_NV_Komponentenfehler_3_11_Cx7_TF_TC_Error_5)}, range raw 0..7, transfer-property=PENDING, to BMC_HV(timeout 5 s)  # Übertragung OBD relevanter Fehlerpfade vom Secondary zum Primary Steuergerät. Zuordnung der generischen Komponentenfehler muss zwischen Sender und Empfänger abgestimmt werden.
          signal DCDC_NV_Komponentenfehler_3_12_XIX_DCDC_NV_Komponentenfehler_04_XIX_HCP5_CANFD01: start 33, 3 bit, little-endian, data-type-policy=OVERRIDE, i-signal-type=PRIMITIVE, init-value=0, base-type=BT_DCDC_NV_Komponentenfehler_3_12, compu {0=Cx0_TNCTOC (CM_DCDC_NV_Komponentenfehler_3_12_Cx0_TNCTOC), 1=Cx1_TP_TC (CM_DCDC_NV_Komponentenfehler_3_12_Cx1_TP_TC), 2=Cx2_TP_TC_WCMTL (CM_DCDC_NV_Komponentenfehler_3_12_Cx2_TP_TC_WCMTL), 3=Cx3_TF_TC_Error_1 (CM_DCDC_NV_Komponentenfehler_3_12_Cx3_TF_TC_Error_1), 4=Cx4_TF_TC_Error_2 (CM_DCDC_NV_Komponentenfehler_3_12_Cx4_TF_TC_Error_2), 5=Cx5_TF_TC_Error_3 (CM_DCDC_NV_Komponentenfehler_3_12_Cx5_TF_TC_Error_3), 6=Cx6_TF_TC_Error_4 (CM_DCDC_NV_Komponentenfehler_3_12_Cx6_TF_TC_Error_4), 7=Cx7_TF_TC_Error_5 (CM_DCDC_NV_Komponentenfehler_3_12_Cx7_TF_TC_Error_5)}, range raw 0..7, transfer-property=PENDING, to BMC_HV(timeout 5 s)  # Übertragung OBD relevanter Fehlerpfade vom Secondary zum Primary Steuergerät. Zuordnung der generischen Komponentenfehler muss zwischen Sender und Empfänger abgestimmt werden.
          signal DCDC_NV_Komponentenfehler_3_13_XIX_DCDC_NV_Komponentenfehler_04_XIX_HCP5_CANFD01: start 36, 3 bit, little-endian, data-type-policy=OVERRIDE, i-signal-type=PRIMITIVE, init-value=0, base-type=BT_DCDC_NV_Komponentenfehler_3_13, compu {0=Cx0_TNCTOC (CM_DCDC_NV_Komponentenfehler_3_13_Cx0_TNCTOC), 1=Cx1_TP_TC (CM_DCDC_NV_Komponentenfehler_3_13_Cx1_TP_TC), 2=Cx2_TP_TC_WCMTL (CM_DCDC_NV_Komponentenfehler_3_13_Cx2_TP_TC_WCMTL), 3=Cx3_TF_TC_Error_1 (CM_DCDC_NV_Komponentenfehler_3_13_Cx3_TF_TC_Error_1), 4=Cx4_TF_TC_Error_2 (CM_DCDC_NV_Komponentenfehler_3_13_Cx4_TF_TC_Error_2), 5=Cx5_TF_TC_Error_3 (CM_DCDC_NV_Komponentenfehler_3_13_Cx5_TF_TC_Error_3), 6=Cx6_TF_TC_Error_4 (CM_DCDC_NV_Komponentenfehler_3_13_Cx6_TF_TC_Error_4), 7=Cx7_TF_TC_Error_5 (CM_DCDC_NV_Komponentenfehler_3_13_Cx7_TF_TC_Error_5)}, range raw 0..7, transfer-property=PENDING, to BMC_HV(timeout 5 s)  # Übertragung OBD relevanter Fehlerpfade vom Secondary zum Primary Steuergerät. Zuordnung der generischen Komponentenfehler muss zwischen Sender und Empfänger abgestimmt werden.
          signal DCDC_NV_Komponentenfehler_3_14_XIX_DCDC_NV_Komponentenfehler_04_XIX_HCP5_CANFD01: start 39, 3 bit, little-endian, data-type-policy=OVERRIDE, i-signal-type=PRIMITIVE, init-value=0, base-type=BT_DCDC_NV_Komponentenfehler_3_14, compu {0=Cx0_TNCTOC (CM_DCDC_NV_Komponentenfehler_3_14_Cx0_TNCTOC), 1=Cx1_TP_TC (CM_DCDC_NV_Komponentenfehler_3_14_Cx1_TP_TC), 2=Cx2_TP_TC_WCMTL (CM_DCDC_NV_Komponentenfehler_3_14_Cx2_TP_TC_WCMTL), 3=Cx3_TF_TC_Error_1 (CM_DCDC_NV_Komponentenfehler_3_14_Cx3_TF_TC_Error_1), 4=Cx4_TF_TC_Error_2 (CM_DCDC_NV_Komponentenfehler_3_14_Cx4_TF_TC_Error_2), 5=Cx5_TF_TC_Error_3 (CM_DCDC_NV_Komponentenfehler_3_14_Cx5_TF_TC_Error_3), 6=Cx6_TF_TC_Error_4 (CM_DCDC_NV_Komponentenfehler_3_14_Cx6_TF_TC_Error_4), 7=Cx7_TF_TC_Error_5 (CM_DCDC_NV_Komponentenfehler_3_14_Cx7_TF_TC_Error_5)}, range raw 0..7, transfer-property=PENDING, to BMC_HV(timeout 5 s)  # Übertragung OBD relevanter Fehlerpfade vom Secondary zum Primary Steuergerät. Zuordnung der generischen Komponentenfehler muss zwischen Sender und Empfänger abgestimmt werden.
          signal DCDC_NV_Komponentenfehler_3_15_XIX_DCDC_NV_Komponentenfehler_04_XIX_HCP5_CANFD01: start 42, 3 bit, little-endian, data-type-policy=OVERRIDE, i-signal-type=PRIMITIVE, init-value=0, base-type=BT_DCDC_NV_Komponentenfehler_3_15, compu {0=Cx0_TNCTOC (CM_DCDC_NV_Komponentenfehler_3_15_Cx0_TNCTOC), 1=Cx1_TP_TC (CM_DCDC_NV_Komponentenfehler_3_15_Cx1_TP_TC), 2=Cx2_TP_TC_WCMTL (CM_DCDC_NV_Komponentenfehler_3_15_Cx2_TP_TC_WCMTL), 3=Cx3_TF_TC_Error_1 (CM_DCDC_NV_Komponentenfehler_3_15_Cx3_TF_TC_Error_1), 4=Cx4_TF_TC_Error_2 (CM_DCDC_NV_Komponentenfehler_3_15_Cx4_TF_TC_Error_2), 5=Cx5_TF_TC_Error_3 (CM_DCDC_NV_Komponentenfehler_3_15_Cx5_TF_TC_Error_3), 6=Cx6_TF_TC_Error_4 (CM_DCDC_NV_Komponentenfehler_3_15_Cx6_TF_TC_Error_4), 7=Cx7_TF_TC_Error_5 (CM_DCDC_NV_Komponentenfehler_3_15_Cx7_TF_TC_Error_5)}, range raw 0..7, transfer-property=PENDING, to BMC_HV(timeout 5 s)  # Übertragung OBD relevanter Fehlerpfade vom Secondary zum Primary Steuergerät. Zuordnung der generischen Komponentenfehler muss zwischen Sender und Empfänger abgestimmt werden.
          signal DCDC_NV_Komponentenfehler_3_16_XIX_DCDC_NV_Komponentenfehler_04_XIX_HCP5_CANFD01: start 45, 3 bit, little-endian, data-type-policy=OVERRIDE, i-signal-type=PRIMITIVE, init-value=0, base-type=BT_DCDC_NV_Komponentenfehler_3_16, compu {0=Cx0_TNCTOC (CM_DCDC_NV_Komponentenfehler_3_16_Cx0_TNCTOC), 1=Cx1_TP_TC (CM_DCDC_NV_Komponentenfehler_3_16_Cx1_TP_TC), 2=Cx2_TP_TC_WCMTL (CM_DCDC_NV_Komponentenfehler_3_16_Cx2_TP_TC_WCMTL), 3=Cx3_TF_TC_Error_1 (CM_DCDC_NV_Komponentenfehler_3_16_Cx3_TF_TC_Error_1), 4=Cx4_TF_TC_Error_2 (CM_DCDC_NV_Komponentenfehler_3_16_Cx4_TF_TC_Error_2), 5=Cx5_TF_TC_Error_3 (CM_DCDC_NV_Komponentenfehler_3_16_Cx5_TF_TC_Error_3), 6=Cx6_TF_TC_Error_4 (CM_DCDC_NV_Komponentenfehler_3_16_Cx6_TF_TC_Error_4), 7=Cx7_TF_TC_Error_5 (CM_DCDC_NV_Komponentenfehler_3_16_Cx7_TF_TC_Error_5)}, range raw 0..7, transfer-property=PENDING, to BMC_HV(timeout 5 s)  # Übertragung OBD relevanter Fehlerpfade vom Secondary zum Primary Steuergerät. Zuordnung der generischen Komponentenfehler muss zwischen Sender und Empfänger abgestimmt werden.
      frame DEV_BJB_Req_01_XIX_HCP5_CANFD01: id 0x18FED000, to BMC_HV, frame-length=8, can-addressing-mode=EXTENDED, can-frame-rx-behavior=CAN-FD, can-frame-tx-behavior=CAN-FD
        user defined pdu CDD_DEV_BJB_Req_01_XIX_HCP5_CANFD01: length=8, cdd-type=EID
      frame DEV_BJB_Resp_FF_XIX_HCP5_CANFD01: id 0x18FED0FF, from BMC_HV, frame-length=8, can-addressing-mode=EXTENDED, can-frame-rx-behavior=CAN-FD, can-frame-tx-behavior=CAN-FD
        user defined pdu CDD_DEV_BJB_Resp_FF_XIX_HCP5_CANFD01: length=8, cdd-type=EID
      frame DEV_Hybrid_01_Req_00_XIX_HCP5_CANFD01: id 0x1BFC6300, to BMC_HV, frame-length=64, can-addressing-mode=EXTENDED, can-frame-rx-behavior=CAN-FD, can-frame-tx-behavior=CAN-FD
        pdu DEV_Hybrid_01_Req_00_XIX_HCP5_CANFD01: length=64, transmission-mode-true-timing=event-controlled-timing={number-of-repetitions=0, repetition-period=0}, unused-bit-pattern=0
          signal DEV_Hybrid_01_Req_00_FD_Data_XIX_DEV_Hybrid_01_Req_00_XIX_HCP5_CANFD01: start 0, 512 bit, opaque, data-type-policy=OVERRIDE, i-signal-type=ARRAY, init-value=64 x 0, base-type=BT_DEV_Hybrid_01_Req_00_FD_Data, implementation-data-type=DEV_Hybrid_01_Req_00_FD_Data, transfer-property=TRIGGERED-ON-CHANGE-WITHOUT-REPETITION, to BMC_HV
      frame DEV_Hybrid_01_Resp_FF_XIX_HCP5_CANFD01: id 0x1BFC63FF, from BMC_HV, frame-length=64, can-addressing-mode=EXTENDED, can-frame-rx-behavior=CAN-FD, can-frame-tx-behavior=CAN-FD
        pdu DEV_Hybrid_01_Resp_FF_XIX_HCP5_CANFD01: length=64, transmission-mode-true-timing=event-controlled-timing={number-of-repetitions=0, repetition-period=0}, unused-bit-pattern=0
          signal DEV_Hybrid_01_Resp_FF_FD_Data_XIX_DEV_Hybrid_01_Resp_FF_XIX_HCP5_CANFD01: start 0, 512 bit, opaque, data-type-policy=OVERRIDE, i-signal-type=ARRAY, init-value=64 x 0, base-type=BT_DEV_Hybrid_01_Resp_FF_FD_Data, implementation-data-type=DEV_Hybrid_01_Resp_FF_FD_Data, transfer-property=TRIGGERED-ON-CHANGE-WITHOUT-REPETITION
      frame DIA_BJB_Req_XIX_HCP5_CANFD01: id 0x17FC16D0, to BMC_HV, frame-length=8, can-addressing-mode=EXTENDED, can-frame-rx-behavior=CAN-FD, can-frame-tx-behavior=CAN-FD
        n pdu DIA_BJB_Req_XIX_HCP5_CANFD01: length=8
      frame DIA_BJB_Resp_XIX_HCP5_CANFD01: id 0x17FE16D0, from BMC_HV, frame-length=8, can-addressing-mode=EXTENDED, can-frame-rx-behavior=CAN-FD, can-frame-tx-behavior=CAN-FD
        n pdu DIA_BJB_Resp_XIX_HCP5_CANFD01: length=8
      frame DIA_UI2Sens01_Req_XIX_HCP5_CANFD01: id 0x17FC17B1, to BMC_HV, frame-length=8, can-addressing-mode=EXTENDED, can-frame-rx-behavior=CAN-FD, can-frame-tx-behavior=CAN-FD
        n pdu DIA_UI2Sens01_Req_XIX_HCP5_CANFD01: length=8
      frame DIA_UI2Sens01_Resp_XIX_HCP5_CANFD01: id 0x17FE17B1, from BMC_HV, frame-length=8, can-addressing-mode=EXTENDED, can-frame-rx-behavior=CAN-FD, can-frame-tx-behavior=CAN-FD
        n pdu DIA_UI2Sens01_Resp_XIX_HCP5_CANFD01: length=8
      frame DIA_UI2Sens02_Req_XIX_HCP5_CANFD01: id 0x17FC17B2, to BMC_HV, frame-length=8, can-addressing-mode=EXTENDED, can-frame-rx-behavior=CAN-FD, can-frame-tx-behavior=CAN-FD
        n pdu DIA_UI2Sens02_Req_XIX_HCP5_CANFD01: length=8
      frame DIA_UI2Sens02_Resp_XIX_HCP5_CANFD01: id 0x17FE17B2, from BMC_HV, frame-length=8, can-addressing-mode=EXTENDED, can-frame-rx-behavior=CAN-FD, can-frame-tx-behavior=CAN-FD
        n pdu DIA_UI2Sens02_Resp_XIX_HCP5_CANFD01: length=8
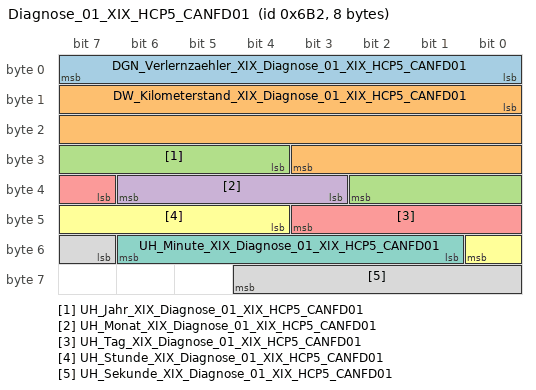
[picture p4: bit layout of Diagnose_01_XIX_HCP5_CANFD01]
      frame Diagnose_01_XIX_HCP5_CANFD01: id 0x6B2, to BMC_HV, frame-length=8, can-addressing-mode=STANDARD, can-frame-rx-behavior=CAN-FD, can-frame-tx-behavior=CAN-FD
        pdu Diagnose_01_XIX_HCP5_CANFD01: length=8, transmission-mode-true-timing=cyclic-timing={time-offset=0, time-period=1}, unused-bit-pattern=0
          signal DGN_Verlernzaehler_XIX_Diagnose_01_XIX_HCP5_CANFD01: start 0, 8 bit, little-endian, data-type-policy=OVERRIDE, i-signal-type=PRIMITIVE, init-value=0, base-type=BT_DGN_Verlernzaehler, compu {phys=raw for raw 0..254, 255=Cxff_ungueltiger_Zaehlerstand_oder_kein_gueltiger_Fahrzyklus (CM_DGN_Verlernzaehler_Cxff_ungueltiger_Zaehlerstand_oder_kein_gueltiger_Fahrzyklus) (ungültiger Zählerstand oder kein gültiger Fahrzyklus)}, range phys 0..254, raw 0..255, transfer-property=PENDING  # wrap around 254 --> 0
          signal DW_Kilometerstand_XIX_Diagnose_01_XIX_HCP5_CANFD01: start 8, 20 bit, little-endian, data-type-policy=OVERRIDE, i-signal-type=PRIMITIVE, init-value=1048574, base-type=BT_DW_Kilometerstand, invalid-value=Invalid_DW_Kilometerstand_XIX_Diagnose_01_XIX_HCP5_CANFD01:1048575, compu {phys=raw for raw 0..1048573, 1048574=Cxffffe_Init (CM_DW_Kilometerstand_Cxffffe_Init), 1048575=Cxfffff_Fehler (CM_DW_Kilometerstand_Cxfffff_Fehler); unit Unit_KiloMeter}, range phys 0..1048573 Unit_KiloMeter, raw 0..1048575, unit=Unit_KiloMeter, transfer-property=PENDING, to BMC_HV(timeout 5 s)  # Fehler wird ausgegeben, falls Kilometerstand nicht restaurierbar
          signal UH_Jahr_XIX_Diagnose_01_XIX_HCP5_CANFD01: start 28, 7 bit, little-endian, data-type-policy=OVERRIDE, i-signal-type=PRIMITIVE, init-value=0, base-type=BT_UH_Jahr, compu {phys=raw+2000 for raw 0..127; unit Unit_Year}, range phys 2000..2127 Unit_Year, raw 0..127, unit=Unit_Year, transfer-property=PENDING, to BMC_HV(timeout 5 s)
          signal UH_Monat_XIX_Diagnose_01_XIX_HCP5_CANFD01: start 35, 4 bit, little-endian, data-type-policy=OVERRIDE, i-signal-type=PRIMITIVE, init-value=0, base-type=BT_UH_Monat, invalid-value=Invalid_UH_Monat_XIX_Diagnose_01_XIX_HCP5_CANFD01:15, compu {0=Cx0_Init (CM_UH_Monat_Cx0_Init), phys=raw for raw 1..12, 14=Cxe_Relatives_Datum (CM_UH_Monat_Cxe_Relatives_Datum), 15=Cxf_Fehler (CM_UH_Monat_Cxf_Fehler); unit Unit_Month}, range phys 1..12 Unit_Month, raw 0..15, unit=Unit_Month, transfer-property=PENDING, to BMC_HV(timeout 5 s)  # 0x0D, 0xF = Werte ungültig 0x0E = Relatives Datum (nur VW)
          signal UH_Tag_XIX_Diagnose_01_XIX_HCP5_CANFD01: start 39, 5 bit, little-endian, data-type-policy=OVERRIDE, i-signal-type=PRIMITIVE, init-value=0, base-type=BT_UH_Tag, compu {0=Cx0_Init (CM_UH_Tag_Cx0_Init), phys=raw for raw 1..31; unit Unit_Day}, range phys 1..31 Unit_Day, raw 0..31, unit=Unit_Day, transfer-property=PENDING, to BMC_HV(timeout 5 s)  # 0x0: reserviert bei VW
          signal UH_Stunde_XIX_Diagnose_01_XIX_HCP5_CANFD01: start 44, 5 bit, little-endian, data-type-policy=OVERRIDE, i-signal-type=PRIMITIVE, init-value=0, base-type=BT_UH_Stunde, compu {phys=raw for raw 0..23; unit Unit_Hours}, range phys 0..23 Unit_Hours, raw 0..23, unit=Unit_Hours, transfer-property=PENDING, to BMC_HV(timeout 5 s)  # 0x18 - 0x1F = Werte ungültig
          signal UH_Minute_XIX_Diagnose_01_XIX_HCP5_CANFD01: start 49, 6 bit, little-endian, data-type-policy=OVERRIDE, i-signal-type=PRIMITIVE, init-value=0, base-type=BT_UH_Minute, compu {phys=raw for raw 0..59; unit Unit_Minut}, range phys 0..59 Unit_Minut, raw 0..59, unit=Unit_Minut, transfer-property=PENDING, to BMC_HV(timeout 5 s)  # 0x3C- 0x3f = Werte ungültig
          signal UH_Sekunde_XIX_Diagnose_01_XIX_HCP5_CANFD01: start 55, 6 bit, little-endian, data-type-policy=OVERRIDE, i-signal-type=PRIMITIVE, init-value=0, base-type=BT_UH_Sekunde, compu {phys=raw for raw 0..59; unit Unit_Secon}, range phys 0..59 Unit_Secon, raw 0..59, unit=Unit_Secon, transfer-property=PENDING, to BMC_HV(timeout 5 s)  # 0x3C- 0x3f = Werte ungültig
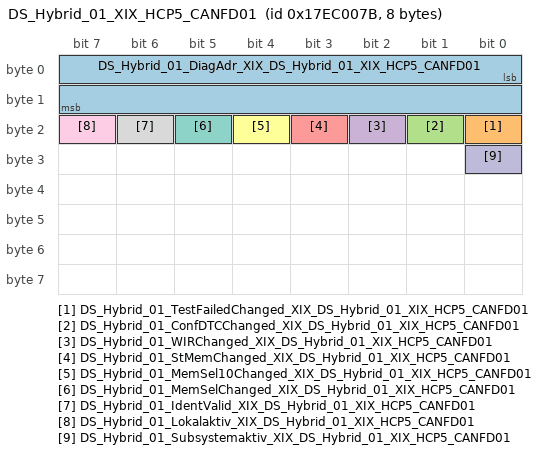
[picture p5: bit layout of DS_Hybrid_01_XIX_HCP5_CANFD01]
      frame DS_Hybrid_01_XIX_HCP5_CANFD01: id 0x17EC007B, from BMC_HV, frame-length=8, can-addressing-mode=EXTENDED, can-frame-rx-behavior=CAN-FD, can-frame-tx-behavior=CAN-FD
        pdu DS_Hybrid_01_XIX_HCP5_CANFD01: length=8, minimum-delay=0.08, transmission-mode-true-timing={cyclic-timing={time-offset=0, time-period=1}, event-controlled-timing={number-of-repetitions=0, repetition-period=0}}, unused-bit-pattern=0
          signal DS_Hybrid_01_DiagAdr_XIX_DS_Hybrid_01_XIX_HCP5_CANFD01: start 0, 16 bit, little-endian, data-type-policy=OVERRIDE, i-signal-type=PRIMITIVE, init-value=140, base-type=BT_DS_Hybrid_01_DiagAdr, compu {phys=raw for raw 0..65535}, range phys 0..65535, raw 0..65535, transfer-property=PENDING  # Übertragung vom Diagnosestatus gem. 80114
          signal DS_Hybrid_01_TestFailedChanged_XIX_DS_Hybrid_01_XIX_HCP5_CANFD01: start 16, 1 bit, little-endian, data-type-policy=OVERRIDE, i-signal-type=PRIMITIVE, init-value=0, base-type=BT_DS_Hybrid_01_TestFailedChanged, compu {phys=raw for raw 0..1}, range phys 0..1, raw 0..1, transfer-property=TRIGGERED-ON-CHANGE-WITHOUT-REPETITION  # Übertragung vom Diagnosestatus gem. 80114
          signal DS_Hybrid_01_ConfDTCChanged_XIX_DS_Hybrid_01_XIX_HCP5_CANFD01: start 17, 1 bit, little-endian, data-type-policy=OVERRIDE, i-signal-type=PRIMITIVE, init-value=0, base-type=BT_DS_Hybrid_01_ConfDTCChanged, compu {phys=raw for raw 0..1}, range phys 0..1, raw 0..1, transfer-property=TRIGGERED-ON-CHANGE-WITHOUT-REPETITION  # Übertragung vom Diagnosestatus gem. 80114
          signal DS_Hybrid_01_WIRChanged_XIX_DS_Hybrid_01_XIX_HCP5_CANFD01: start 18, 1 bit, little-endian, data-type-policy=OVERRIDE, i-signal-type=PRIMITIVE, init-value=0, base-type=BT_DS_Hybrid_01_WIRChanged, compu {phys=raw for raw 0..1}, range phys 0..1, raw 0..1, transfer-property=TRIGGERED-ON-CHANGE-WITHOUT-REPETITION  # Übertragung vom Diagnosestatus gem. 80114
          signal DS_Hybrid_01_StMemChanged_XIX_DS_Hybrid_01_XIX_HCP5_CANFD01: start 19, 1 bit, little-endian, data-type-policy=OVERRIDE, i-signal-type=PRIMITIVE, init-value=0, base-type=BT_DS_Hybrid_01_StMemChanged, compu {phys=raw for raw 0..1}, range phys 0..1, raw 0..1, transfer-property=TRIGGERED-ON-CHANGE-WITHOUT-REPETITION  # Übertragung vom Diagnosestatus gem. 80114
          signal DS_Hybrid_01_MemSel10Changed_XIX_DS_Hybrid_01_XIX_HCP5_CANFD01: start 20, 1 bit, little-endian, data-type-policy=OVERRIDE, i-signal-type=PRIMITIVE, init-value=0, base-type=BT_DS_Hybrid_01_MemSel10Changed, compu {phys=raw for raw 0..1}, range phys 0..1, raw 0..1, transfer-property=TRIGGERED-ON-CHANGE-WITHOUT-REPETITION  # Übertragung vom Diagnosestatus gem. 80114
          signal DS_Hybrid_01_MemSelChanged_XIX_DS_Hybrid_01_XIX_HCP5_CANFD01: start 21, 1 bit, little-endian, data-type-policy=OVERRIDE, i-signal-type=PRIMITIVE, init-value=0, base-type=BT_DS_Hybrid_01_MemSelChanged, compu {phys=raw for raw 0..1}, range phys 0..1, raw 0..1, transfer-property=TRIGGERED-ON-CHANGE-WITHOUT-REPETITION  # Übertragung vom Diagnosestatus gem. 80114
          signal DS_Hybrid_01_IdentValid_XIX_DS_Hybrid_01_XIX_HCP5_CANFD01: start 22, 1 bit, little-endian, data-type-policy=OVERRIDE, i-signal-type=PRIMITIVE, init-value=1, base-type=BT_DS_Hybrid_01_IdentValid, compu {0=Cx0_Ungueltig (CM_DS_Hybrid_01_IdentValid_Cx0_Ungueltig), 1=Cx1_Gueltig (CM_DS_Hybrid_01_IdentValid_Cx1_Gueltig)}, range raw 0..1, transfer-property=TRIGGERED-ON-CHANGE-WITHOUT-REPETITION  # Signalisiert ob die Identifikationsdaten gueltig sind
          signal DS_Hybrid_01_Lokalaktiv_XIX_DS_Hybrid_01_XIX_HCP5_CANFD01: start 23, 1 bit, little-endian, data-type-policy=OVERRIDE, i-signal-type=PRIMITIVE, init-value=0, base-type=BT_DS_Hybrid_01_Lokalaktiv, compu {0=Cx0_war_nicht_lokal_aktiv (CM_DS_Hybrid_01_Lokalaktiv_Cx0_war_nicht_lokal_aktiv), 1=Cx1_war_lokal_aktiv (CM_DS_Hybrid_01_Lokalaktiv_Cx1_war_lokal_aktiv)}, range raw 0..1, transfer-property=PENDING  # Zeigt an ob das SG nach Klemme15 AUS und nach entsprechender MAX Aktivzeit noch aktiv war.
          signal DS_Hybrid_01_Subsystemaktiv_XIX_DS_Hybrid_01_XIX_HCP5_CANFD01: start 24, 1 bit, little-endian, data-type-policy=OVERRIDE, i-signal-type=PRIMITIVE, init-value=0, base-type=BT_DS_Hybrid_01_Subsystemaktiv, compu {0=Cx0_war_nicht_lokal_aktiv (CM_DS_Hybrid_01_Subsystemaktiv_Cx0_war_nicht_lokal_aktiv), 1=Cx1_war_lokal_aktiv (CM_DS_Hybrid_01_Subsystemaktiv_Cx1_war_lokal_aktiv)}, range raw 0..1, transfer-property=PENDING  # Zeigt an ob ein Subsystem des SGs nach Klemme15 AUS und nach entsprechender MAX Aktivzeit noch aktiv war
